BU_:  Airbag BAP_Tester ICAS1_Gateway ICAS1_KommunikationsServer LE1 LE2 Motor_BEV Schaltbetaetigung

BO_ 949 Klima_11: 8 ICAS1_Gateway
 SG_ KL_Drehz_Anh  : 0|1@1+ (1.000000,0.000000) [0.000000|1.000000] "" Vector__XXX
 SG_ KL_Vorwarn_Komp_ein  : 1|1@1+ (1.000000,0.000000) [0.000000|1.000000] "" Vector__XXX
 SG_ KL_AC_Schalter  : 2|1@1+ (1.000000,0.000000) [0.000000|1.000000] "" Vector__XXX
 SG_ KL_Komp_Moment_alt  : 3|1@1+ (1.000000,0.000000) [0.000000|1.000000] "" Vector__XXX
 SG_ KL_Vorwarn_Zuheizer_ein  : 6|1@1+ (1.000000,0.000000) [0.000000|1.000000] "" Vector__XXX
 SG_ KL_Zustand  : 7|1@1+ (1.000000,0.000000) [0.000000|1.000000] "" Vector__XXX
 SG_ KL_Kompressorkupplung_linear  : 8|8@1+ (20.000000,0.000000) [0.000000|4000.000000] "Unit_MilliAmper" Vector__XXX
 SG_ KL_Charisma_FahrPr  : 16|4@1+ (1.000000,0.000000) [0.000000|15.000000] "" Vector__XXX
 SG_ KL_Charisma_Status  : 20|2@1+ (1.000000,0.000000) [0.000000|3.000000] "" Vector__XXX
 SG_ KL_nachtr_Stopp_Anf  : 22|1@1+ (1.000000,0.000000) [0.000000|1.000000] "" Vector__XXX
 SG_ KL_T_Charge  : 23|1@1+ (1.000000,0.000000) [0.000000|1.000000] "" Vector__XXX
 SG_ KL_Last_Kompr  : 24|8@1+ (0.250000,0.000000) [0.000000|63.500000] "Unit_NewtoMeter" Vector__XXX
 SG_ KL_Spannungs_Anf  : 32|2@1+ (1.000000,0.000000) [0.000000|3.000000] "" Vector__XXX
 SG_ KL_Thermomanagement  : 34|2@1+ (1.000000,0.000000) [0.000000|3.000000] "" Motor_BEV
 SG_ KL_StartStopp_Info  : 36|2@1+ (1.000000,0.000000) [0.000000|3.000000] "" Vector__XXX
 SG_ KL_Freilauf_Info  : 38|2@1+ (1.000000,0.000000) [0.000000|3.000000] "" Vector__XXX
 SG_ KL_Anf_KL  : 40|8@1+ (0.400000,0.000000) [0.000000|101.600000] "Unit_PerCent" Motor_BEV
 SG_ KL_el_Zuheizer_Stufe  : 48|3@1+ (1.000000,0.000000) [0.000000|7.000000] "" Vector__XXX
 SG_ KL_Ausstattung_Klima  : 51|3@1+ (1.000000,0.000000) [0.000000|7.000000] "" Vector__XXX
 SG_ KL_Variante_Standheizung  : 54|2@1+ (1.000000,0.000000) [0.000000|3.000000] "" Vector__XXX
 SG_ KL_Anf_KV  : 57|7@1+ (1.000000,0.000000) [0.000000|100.000000] "Unit_PerCent" Motor_BEV

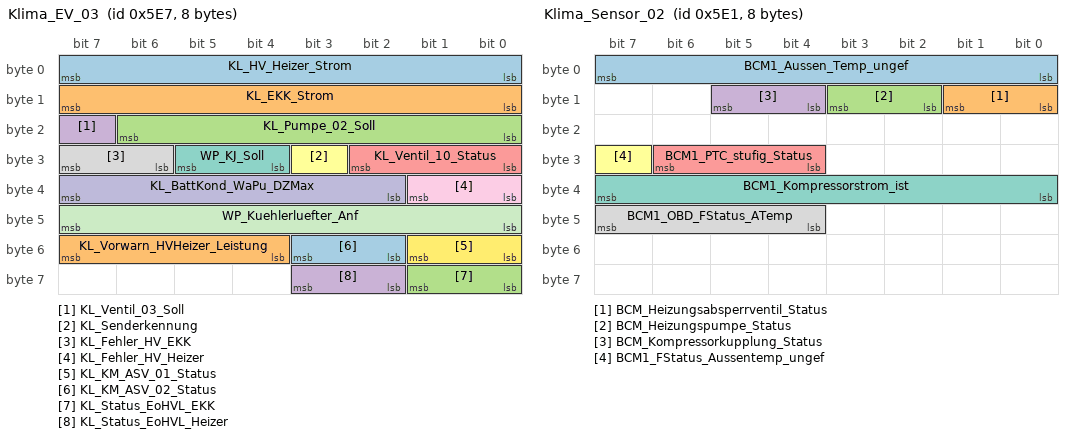
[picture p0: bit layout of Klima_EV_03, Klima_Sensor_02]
BO_ 1511 Klima_EV_03: 8 ICAS1_Gateway
 SG_ KL_HV_Heizer_Strom  : 0|8@1+ (0.250000,0.000000) [0.000000|63.500000] "Unit_Amper" Motor_BEV
 SG_ KL_EKK_Strom  : 8|8@1+ (0.250000,0.000000) [0.000000|63.500000] "Unit_Amper" Motor_BEV
 SG_ KL_Pumpe_02_Soll  : 16|7@1+ (1.000000,0.000000) [0.000000|100.000000] "Unit_PerCent" Motor_BEV
 SG_ KL_Ventil_03_Soll  : 23|1@1+ (1.000000,0.000000) [0.000000|1.000000] "" Vector__XXX
 SG_ KL_Ventil_10_Status  : 24|3@1+ (1.000000,0.000000) [0.000000|7.000000] "" Vector__XXX
 SG_ KL_Senderkennung  : 27|1@1+ (1.000000,0.000000) [0.000000|1.000000] "" Vector__XXX
 SG_ WP_KJ_Soll  : 28|2@1+ (1.000000,0.000000) [0.000000|3.000000] "" Vector__XXX
 SG_ KL_Fehler_HV_EKK  : 30|2@1+ (1.000000,0.000000) [0.000000|3.000000] "" Vector__XXX
 SG_ KL_Fehler_HV_Heizer  : 32|2@1+ (1.000000,0.000000) [0.000000|3.000000] "" Vector__XXX
 SG_ KL_BattKond_WaPu_DZMax  : 34|6@1+ (2.000000,0.000000) [0.000000|100.000000] "Unit_PerCent" Vector__XXX
 SG_ WP_Kuehlerluefter_Anf  : 40|8@1+ (0.400000,0.000000) [0.000000|101.600000] "Unit_PerCent" Vector__XXX
 SG_ KL_KM_ASV_01_Status  : 48|2@1+ (1.000000,0.000000) [0.000000|3.000000] "" Vector__XXX
 SG_ KL_KM_ASV_02_Status  : 50|2@1+ (1.000000,0.000000) [0.000000|3.000000] "" Vector__XXX
 SG_ KL_Vorwarn_HVHeizer_Leistung  : 52|4@1+ (1.000000,0.000000) [0.000000|15.000000] "" Vector__XXX
 SG_ KL_Status_EoHVL_EKK  : 56|2@1+ (1.000000,0.000000) [0.000000|3.000000] "" Motor_BEV
 SG_ KL_Status_EoHVL_Heizer  : 58|2@1+ (1.000000,0.000000) [0.000000|3.000000] "" Motor_BEV

BO_ 1505 Klima_Sensor_02: 8 ICAS1_Gateway
 SG_ BCM1_Aussen_Temp_ungef  : 0|8@1+ (0.500000,-50.000000) [-50.000000|76.000000] "Unit_DegreCelsi" LE1 LE2 Motor_BEV
 SG_ BCM_Heizungsabsperrventil_Status  : 8|2@1+ (1.000000,0.000000) [0.000000|3.000000] "" Vector__XXX
 SG_ BCM_Heizungspumpe_Status  : 10|2@1+ (1.000000,0.000000) [0.000000|3.000000] "" Vector__XXX
 SG_ BCM_Kompressorkupplung_Status  : 12|2@1+ (1.000000,0.000000) [0.000000|3.000000] "" Vector__XXX
 SG_ BCM1_PTC_stufig_Status  : 28|3@1+ (1.000000,0.000000) [0.000000|7.000000] "" Vector__XXX
 SG_ BCM1_FStatus_Aussentemp_ungef  : 31|1@1+ (1.000000,0.000000) [0.000000|1.000000] "" Vector__XXX
 SG_ BCM1_Kompressorstrom_ist  : 32|8@1+ (4.000000,0.000000) [0.000000|1000.000000] "Unit_MilliAmper" Vector__XXX
 SG_ BCM1_OBD_FStatus_ATemp  : 44|4@1+ (1.000000,0.000000) [0.000000|15.000000] "" Vector__XXX

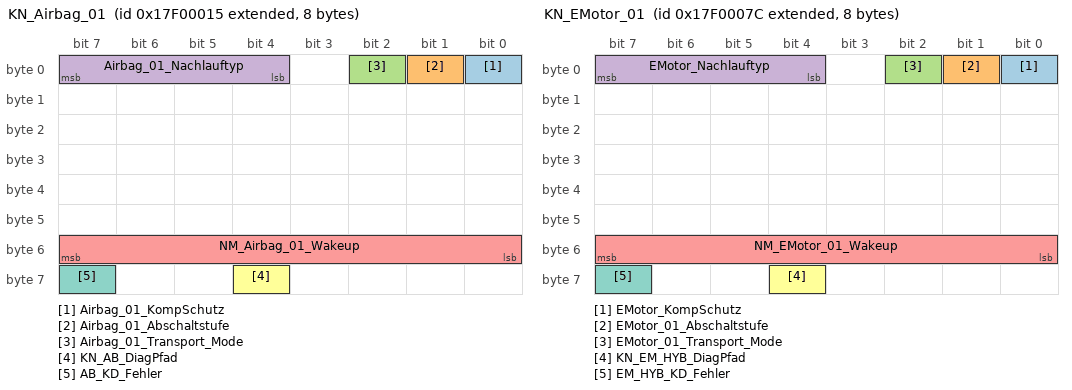
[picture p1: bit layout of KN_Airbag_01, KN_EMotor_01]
BO_ 2549088277 KN_Airbag_01: 8 Airbag
 SG_ Airbag_01_KompSchutz  : 0|1@1+ (1.000000,0.000000) [0.000000|1.000000] "" Vector__XXX
 SG_ Airbag_01_Abschaltstufe  : 1|1@1+ (1.000000,0.000000) [0.000000|1.000000] "" Vector__XXX
 SG_ Airbag_01_Transport_Mode  : 2|1@1+ (1.000000,0.000000) [0.000000|1.000000] "" Vector__XXX
 SG_ Airbag_01_Nachlauftyp  : 4|4@1+ (1.000000,0.000000) [0.000000|15.000000] "" ICAS1_Gateway
 SG_ NM_Airbag_01_Wakeup  : 48|8@1+ (1.000000,0.000000) [0.000000|255.000000] "" Vector__XXX
 SG_ KN_AB_DiagPfad  : 60|1@1+ (1.000000,0.000000) [0.000000|1.000000] "" ICAS1_Gateway
 SG_ AB_KD_Fehler  : 63|1@1+ (1.000000,0.000000) [0.000000|1.000000] "" ICAS1_Gateway

BO_ 2549088380 KN_EMotor_01: 8 LE1
 SG_ EMotor_KompSchutz  : 0|1@1+ (1.000000,0.000000) [0.000000|1.000000] "" Vector__XXX
 SG_ EMotor_01_Abschaltstufe  : 1|1@1+ (1.000000,0.000000) [0.000000|1.000000] "" Vector__XXX
 SG_ EMotor_01_Transport_Mode  : 2|1@1+ (1.000000,0.000000) [0.000000|1.000000] "" Vector__XXX
 SG_ EMotor_Nachlauftyp  : 4|4@1+ (1.000000,0.000000) [0.000000|15.000000] "" ICAS1_Gateway
 SG_ NM_EMotor_01_Wakeup  : 48|8@1+ (1.000000,0.000000) [0.000000|255.000000] "" Vector__XXX
 SG_ KN_EM_HYB_DiagPfad  : 60|1@1+ (1.000000,0.000000) [0.000000|1.000000] "" ICAS1_Gateway
 SG_ EM_HYB_KD_Fehler  : 63|1@1+ (1.000000,0.000000) [0.000000|1.000000] "" ICAS1_Gateway

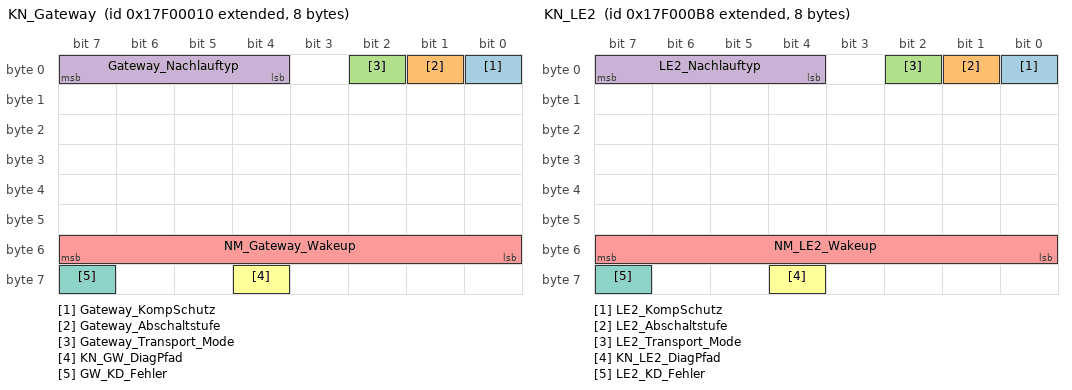
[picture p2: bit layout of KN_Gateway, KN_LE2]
BO_ 2549088272 KN_Gateway: 8 ICAS1_Gateway
 SG_ Gateway_KompSchutz  : 0|1@1+ (1.000000,0.000000) [0.000000|1.000000] "" Vector__XXX
 SG_ Gateway_Abschaltstufe  : 1|1@1+ (1.000000,0.000000) [0.000000|1.000000] "" Vector__XXX
 SG_ Gateway_Transport_Mode  : 2|1@1+ (1.000000,0.000000) [0.000000|1.000000] "" Vector__XXX
 SG_ Gateway_Nachlauftyp  : 4|4@1+ (1.000000,0.000000) [0.000000|15.000000] "" Vector__XXX
 SG_ NM_Gateway_Wakeup  : 48|8@1+ (1.000000,0.000000) [0.000000|255.000000] "" Vector__XXX
 SG_ KN_GW_DiagPfad  : 60|1@1+ (1.000000,0.000000) [0.000000|1.000000] "" Vector__XXX
 SG_ GW_KD_Fehler  : 63|1@1+ (1.000000,0.000000) [0.000000|1.000000] "" Vector__XXX

BO_ 2549088440 KN_LE2: 8 LE2
 SG_ LE2_KompSchutz  : 0|1@1+ (1.000000,0.000000) [0.000000|1.000000] "" Vector__XXX
 SG_ LE2_Abschaltstufe  : 1|1@1+ (1.000000,0.000000) [0.000000|1.000000] "" Vector__XXX
 SG_ LE2_Transport_Mode  : 2|1@1+ (1.000000,0.000000) [0.000000|1.000000] "" Vector__XXX
 SG_ LE2_Nachlauftyp  : 4|4@1+ (1.000000,0.000000) [0.000000|15.000000] "" ICAS1_Gateway
 SG_ NM_LE2_Wakeup  : 48|8@1+ (1.000000,0.000000) [0.000000|255.000000] "" Vector__XXX
 SG_ KN_LE2_DiagPfad  : 60|1@1+ (1.000000,0.000000) [0.000000|1.000000] "" ICAS1_Gateway
 SG_ LE2_KD_Fehler  : 63|1@1+ (1.000000,0.000000) [0.000000|1.000000] "" ICAS1_Gateway

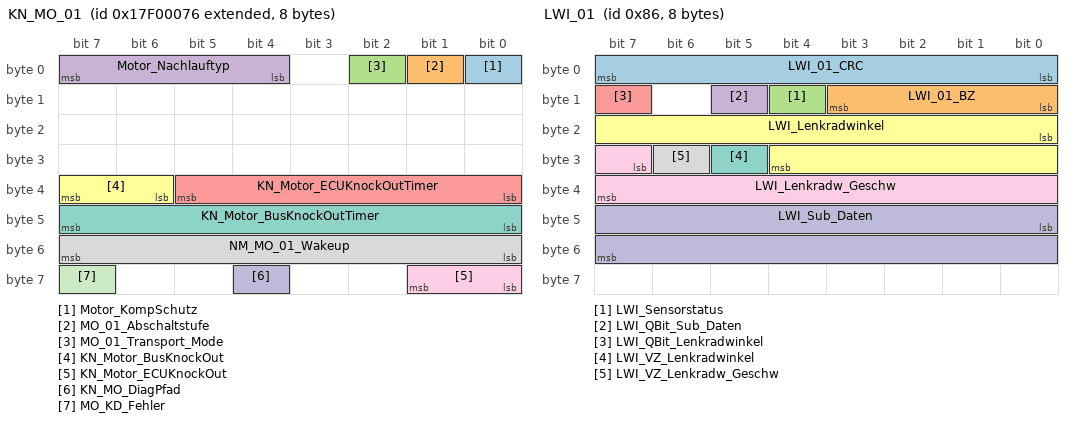
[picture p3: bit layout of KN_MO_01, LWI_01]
BO_ 2549088374 KN_MO_01: 8 Motor_BEV
 SG_ Motor_KompSchutz  : 0|1@1+ (1.000000,0.000000) [0.000000|1.000000] "" Vector__XXX
 SG_ MO_01_Abschaltstufe  : 1|1@1+ (1.000000,0.000000) [0.000000|1.000000] "" Vector__XXX
 SG_ MO_01_Transport_Mode  : 2|1@1+ (1.000000,0.000000) [0.000000|1.000000] "" Vector__XXX
 SG_ Motor_Nachlauftyp  : 4|4@1+ (1.000000,0.000000) [0.000000|15.000000] "" ICAS1_Gateway
 SG_ KN_Motor_ECUKnockOutTimer  : 32|6@1+ (1.000000,0.000000) [0.000000|62.000000] "Unit_Minut" Vector__XXX
 SG_ KN_Motor_BusKnockOut  : 38|2@1+ (1.000000,0.000000) [0.000000|3.000000] "" Vector__XXX
 SG_ KN_Motor_BusKnockOutTimer  : 40|8@1+ (1.000000,0.000000) [0.000000|254.000000] "" Vector__XXX
 SG_ NM_MO_01_Wakeup  : 48|8@1+ (1.000000,0.000000) [0.000000|255.000000] "" Vector__XXX
 SG_ KN_Motor_ECUKnockOut  : 56|2@1+ (1.000000,0.000000) [0.000000|3.000000] "" Vector__XXX
 SG_ KN_MO_DiagPfad  : 60|1@1+ (1.000000,0.000000) [0.000000|1.000000] "" ICAS1_Gateway
 SG_ MO_KD_Fehler  : 63|1@1+ (1.000000,0.000000) [0.000000|1.000000] "" ICAS1_Gateway

BO_ 2621440277 KS_Airbag_01_Req_FD: 16 ICAS1_Gateway
 SG_ KS_Airbag_01_Req_FD_Data  : 0|128@1+ (1.000000,0.000000) [0.000000|340282366920938463463374607431768211456.000000] "" Airbag

BO_ 2621571349 KS_Airbag_01_Resp_FD: 16 Airbag
 SG_ KS_Airbag_01_Resp_FD_Data  : 0|128@1+ (1.000000,0.000000) [0.000000|340282366920938463463374607431768211456.000000] "" ICAS1_Gateway

BO_ 982 Licht_hinten_01: 8 ICAS1_Gateway
 SG_ Licht_hinten_01_BZ  : 0|4@1+ (1.000000,0.000000) [0.000000|15.000000] "" Vector__XXX
 SG_ LH_Aussenlicht_def  : 7|1@1+ (1.000000,0.000000) [0.000000|1.000000] "" Vector__XXX
 SG_ LH_Standlicht_H_aktiv  : 8|1@1+ (1.000000,0.000000) [0.000000|1.000000] "" Vector__XXX
 SG_ LH_Parklicht_HL_aktiv  : 9|1@1+ (1.000000,0.000000) [0.000000|1.000000] "" Vector__XXX
 SG_ LH_Parklicht_HR_aktiv  : 10|1@1+ (1.000000,0.000000) [0.000000|1.000000] "" Vector__XXX
 SG_ LH_Bremslicht_H_aktiv  : 11|1@1+ (1.000000,0.000000) [0.000000|1.000000] "" Vector__XXX
 SG_ LH_Nebelschluss_aktiv  : 12|1@1+ (1.000000,0.000000) [0.000000|1.000000] "" Vector__XXX
 SG_ LH_Rueckfahrlicht_aktiv  : 13|1@1+ (1.000000,0.000000) [0.000000|1.000000] "" Vector__XXX
 SG_ LH_Blinker_HL_akt  : 14|1@1+ (1.000000,0.000000) [0.000000|1.000000] "" Vector__XXX
 SG_ LH_Blinker_HR_akt  : 15|1@1+ (1.000000,0.000000) [0.000000|1.000000] "" Vector__XXX
 SG_ LH_Blinker_li_def  : 16|1@1+ (1.000000,0.000000) [0.000000|1.000000] "" Vector__XXX
 SG_ LH_Bremsl_li_def  : 17|1@1+ (1.000000,0.000000) [0.000000|1.000000] "" Vector__XXX
 SG_ LH_Schlusslicht_li_def  : 18|1@1+ (1.000000,0.000000) [0.000000|1.000000] "" Vector__XXX
 SG_ LH_Rueckf_li_def  : 19|1@1+ (1.000000,0.000000) [0.000000|1.000000] "" Vector__XXX
 SG_ LH_Nebel_li_def  : 20|1@1+ (1.000000,0.000000) [0.000000|1.000000] "" Vector__XXX
 SG_ LH_Schluss_Brems_Nebel_li_def  : 21|1@1+ (1.000000,0.000000) [0.000000|1.000000] "" Vector__XXX
 SG_ LH_Schluss_Brems_Nebel_re_def  : 22|1@1+ (1.000000,0.000000) [0.000000|1.000000] "" Vector__XXX
 SG_ LH_Zusatzschlussl_def  : 23|1@1+ (1.000000,0.000000) [0.000000|1.000000] "" Vector__XXX
 SG_ LH_Schluss_Brems_li_def  : 24|1@1+ (1.000000,0.000000) [0.000000|1.000000] "" Vector__XXX
 SG_ LH_Schluss_Nebel_li_def  : 25|1@1+ (1.000000,0.000000) [0.000000|1.000000] "" Vector__XXX
 SG_ LH_SL_BRL_BLK_li_def  : 26|1@1+ (1.000000,0.000000) [0.000000|1.000000] "" Vector__XXX
 SG_ LH_Brems_Blk_li_def  : 27|1@1+ (1.000000,0.000000) [0.000000|1.000000] "" Vector__XXX
 SG_ LH_Diag_Status_re_def  : 28|1@1+ (1.000000,0.000000) [0.000000|1.000000] "" Vector__XXX
 SG_ LH_Diag_Status_li_def  : 29|1@1+ (1.000000,0.000000) [0.000000|1.000000] "" Vector__XXX
 SG_ LH_Diag_LED_li_def  : 30|1@1+ (1.000000,0.000000) [0.000000|1.000000] "" Vector__XXX
 SG_ LH_Diag_LED_re_def  : 31|1@1+ (1.000000,0.000000) [0.000000|1.000000] "" Vector__XXX
 SG_ LH_Blinker_re_def  : 32|1@1+ (1.000000,0.000000) [0.000000|1.000000] "" Vector__XXX
 SG_ LH_Bremsl_re_def  : 33|1@1+ (1.000000,0.000000) [0.000000|1.000000] "" Vector__XXX
 SG_ LH_Schlusslicht_re_def  : 34|1@1+ (1.000000,0.000000) [0.000000|1.000000] "" Vector__XXX
 SG_ LH_Rueckf_re_def  : 35|1@1+ (1.000000,0.000000) [0.000000|1.000000] "" Vector__XXX
 SG_ LH_Nebel_re_def  : 36|1@1+ (1.000000,0.000000) [0.000000|1.000000] "" Vector__XXX
 SG_ LH_Schluss_Brems_mi_def  : 37|1@1+ (1.000000,0.000000) [0.000000|1.000000] "" Vector__XXX
 SG_ LH_Schluss_Brems_re_def  : 40|1@1+ (1.000000,0.000000) [0.000000|1.000000] "" Vector__XXX
 SG_ LH_Schluss_Nebel_re_def  : 41|1@1+ (1.000000,0.000000) [0.000000|1.000000] "" Vector__XXX
 SG_ LH_SL_BRL_BLK_re_def  : 42|1@1+ (1.000000,0.000000) [0.000000|1.000000] "" Vector__XXX
 SG_ LH_Brems_Blk_re_def  : 43|1@1+ (1.000000,0.000000) [0.000000|1.000000] "" Vector__XXX
 SG_ LH_Kennzl_def  : 48|1@1+ (1.000000,0.000000) [0.000000|1.000000] "" Vector__XXX
 SG_ LH_3_Bremsl_def  : 49|1@1+ (1.000000,0.000000) [0.000000|1.000000] "" Motor_BEV
 SG_ LH_Nebel_mi_def  : 50|1@1+ (1.000000,0.000000) [0.000000|1.000000] "" Vector__XXX
 SG_ LH_Rueckf_mi_def  : 51|1@1+ (1.000000,0.000000) [0.000000|1.000000] "" Vector__XXX
 SG_ LH_Schlusslicht_mi_def  : 52|1@1+ (1.000000,0.000000) [0.000000|1.000000] "" Vector__XXX
 SG_ LH_Bremsl_li_ges_def  : 54|1@1+ (1.000000,0.000000) [0.000000|1.000000] "" Motor_BEV
 SG_ LH_Bremsl_re_ges_def  : 55|1@1+ (1.000000,0.000000) [0.000000|1.000000] "" Motor_BEV
 SG_ LH_Bremsl_mi_def  : 61|1@1+ (1.000000,0.000000) [0.000000|1.000000] "" Vector__XXX
 SG_ BRL_als_SHL  : 62|1@1+ (1.000000,0.000000) [0.000000|1.000000] "" Vector__XXX

BO_ 134 LWI_01: 8 ICAS1_Gateway
 SG_ LWI_01_CRC  : 0|8@1+ (1.000000,0.000000) [0.000000|255.000000] "" Airbag Motor_BEV
 SG_ LWI_01_BZ  : 8|4@1+ (1.000000,0.000000) [0.000000|15.000000] "" Airbag Motor_BEV
 SG_ LWI_Sensorstatus  : 12|1@1+ (1.000000,0.000000) [0.000000|1.000000] "" Airbag Motor_BEV
 SG_ LWI_QBit_Sub_Daten  : 13|1@1+ (1.000000,0.000000) [0.000000|1.000000] "" Vector__XXX
 SG_ LWI_QBit_Lenkradwinkel  : 15|1@1+ (1.000000,0.000000) [0.000000|1.000000] "" Airbag Motor_BEV
 SG_ LWI_Lenkradwinkel  : 16|13@1+ (0.100000,0.000000) [0.000000|800.000000] "Unit_DegreOfArc" Airbag Motor_BEV
 SG_ LWI_VZ_Lenkradwinkel  : 29|1@1+ (1.000000,0.000000) [0.000000|1.000000] "" Airbag Motor_BEV
 SG_ LWI_VZ_Lenkradw_Geschw  : 30|1@1+ (1.000000,0.000000) [0.000000|1.000000] "" Vector__XXX
 SG_ LWI_Lenkradw_Geschw  : 31|9@1+ (5.000000,0.000000) [0.000000|2500.000000] "Unit_DegreOfArcPerSecon" Airbag
 SG_ LWI_Sub_Daten  : 40|16@1+ (1.000000,0.000000) [0.000000|65535.000000] "" Vector__XXX

BO_ 817 MFL_01: 8 ICAS1_Gateway
 SG_ MFL_Zaehler  : 0|4@1+ (1.000000,0.000000) [0.000000|15.000000] "" Vector__XXX
 SG_ MFL_Toggle  : 4|1@1+ (1.000000,0.000000) [0.000000|1.000000] "" Vector__XXX
 SG_ MFL_Lokalaktiv  : 5|1@1+ (1.000000,0.000000) [0.000000|1.000000] "" Vector__XXX
 SG_ MFL_M_Taste  : 6|1@1+ (1.000000,0.000000) [0.000000|1.000000] "" Vector__XXX
 SG_ MFL_Paddle_Verbau  : 7|1@1+ (1.000000,0.000000) [0.000000|1.000000] "" Vector__XXX
 SG_ MFL_Tastencode_1  : 8|8@1+ (1.000000,0.000000) [0.000000|255.000000] "" Vector__XXX
 SG_ MFL_Tastencode_2  : 16|8@1+ (1.000000,0.000000) [0.000000|255.000000] "" Vector__XXX
 SG_ MFL_Eventcode_1  : 24|4@1+ (1.000000,0.000000) [0.000000|15.000000] "" Vector__XXX
 SG_ MFL_Eventcode_2  : 28|4@1+ (1.000000,0.000000) [0.000000|15.000000] "" Vector__XXX
 SG_ MFL_Marke  : 32|4@1+ (1.000000,0.000000) [0.000000|15.000000] "" Vector__XXX
 SG_ MFL_Variante  : 36|4@1+ (1.000000,0.000000) [0.000000|15.000000] "" Vector__XXX
 SG_ MFL_Dummy_0_Signal_1  : 40|8@1+ (1.000000,0.000000) [0.000000|255.000000] "" Vector__XXX
 SG_ MFL_Tip_Down  : 48|1@1+ (1.000000,0.000000) [0.000000|1.000000] "" Motor_BEV
 SG_ MFL_Tip_Up  : 49|1@1+ (1.000000,0.000000) [0.000000|1.000000] "" Motor_BEV
 SG_ MFL_SatModul_links_Err  : 50|1@1+ (1.000000,0.000000) [0.000000|1.000000] "" Vector__XXX
 SG_ MFL_SatModul_rechts_Err  : 51|1@1+ (1.000000,0.000000) [0.000000|1.000000] "" Vector__XXX
 SG_ MFL_Dummy_0_Signal_2  : 52|1@1+ (1.000000,0.000000) [0.000000|1.000000] "" Vector__XXX
 SG_ MFL_Dummy_0_Signal_3  : 53|1@1+ (1.000000,0.000000) [0.000000|1.000000] "" Vector__XXX
 SG_ MFL_LR_HZG_Status  : 54|1@1+ (1.000000,0.000000) [0.000000|1.000000] "" Vector__XXX
 SG_ MFL_LR_HZG_Err  : 55|1@1+ (1.000000,0.000000) [0.000000|1.000000] "" Vector__XXX
 SG_ MFL_Signalhorn  : 56|1@1+ (1.000000,0.000000) [0.000000|1.000000] "" Vector__XXX
 SG_ MFL_Signalhorn_Err  : 57|1@1+ (1.000000,0.000000) [0.000000|1.000000] "" Vector__XXX
 SG_ MFL_Tip_links_Err  : 58|1@1+ (1.000000,0.000000) [0.000000|1.000000] "" Vector__XXX
 SG_ MFL_Tip_rechts_Err  : 59|1@1+ (1.000000,0.000000) [0.000000|1.000000] "" Vector__XXX
 SG_ MFL_Taste_links_Err  : 60|1@1+ (1.000000,0.000000) [0.000000|1.000000] "" Vector__XXX
 SG_ MFL_Taste_rechts_Err  : 61|1@1+ (1.000000,0.000000) [0.000000|1.000000] "" Vector__XXX
 SG_ MFL_ECU_Err  : 62|1@1+ (1.000000,0.000000) [0.000000|1.000000] "" Vector__XXX
 SG_ MFL_Response_Err  : 63|1@1+ (1.000000,0.000000) [0.000000|1.000000] "" Vector__XXX

BO_ 15 MO_SOPC: 1 Motor_BEV
 SG_ MO_SOPC  : 0|1@1+ (1.000000,0.000000) [0.000000|1.000000] "" Vector__XXX

BO_ 1600 Motor_07: 8 Motor_BEV
 SG_ MO_QBit_Ansaugluft_Temp  : 0|1@1+ (1.000000,0.000000) [0.000000|1.000000] "" Vector__XXX
 SG_ MO_QBit_Oel_Temp  : 1|1@1+ (1.000000,0.000000) [0.000000|1.000000] "" Vector__XXX
 SG_ MO_QBit_Kuehlmittel_Temp  : 2|1@1+ (1.000000,0.000000) [0.000000|1.000000] "" Vector__XXX
 SG_ MO_KL15_Abschaltempfehlung  : 3|1@1+ (1.000000,0.000000) [0.000000|1.000000] "" Vector__XXX
 SG_ MO_HYB_Fehler_HV_Netz  : 4|1@1+ (1.000000,0.000000) [0.000000|1.000000] "" Vector__XXX
 SG_ MO_aktives_Getriebeheizen  : 5|1@1+ (1.000000,0.000000) [0.000000|1.000000] "" Vector__XXX
 SG_ MO_Absperrventil_oeffnen  : 6|2@1+ (1.000000,0.000000) [0.000000|3.000000] "" Vector__XXX
 SG_ MO_Ansaugluft_Temp  : 8|8@1+ (0.750000,-48.000000) [-48.000000|141.750000] "Unit_DegreCelsi" Vector__XXX
 SG_ MO_Oel_Temp  : 16|8@1+ (1.000000,-60.000000) [-60.000000|192.000000] "Unit_DegreCelsi" Vector__XXX
 SG_ MO_Kuehlmittel_Temp  : 24|8@1+ (0.750000,-48.000000) [-48.000000|141.750000] "Unit_DegreCelsi" Vector__XXX
 SG_ MO_Hoeheninfo  : 32|8@1+ (0.007810,0.000000) [0.000000|1.983740] "" Vector__XXX
 SG_ MO_Kennfeldk  : 40|1@1+ (1.000000,0.000000) [0.000000|1.000000] "" Vector__XXX
 SG_ MO_Versionsinfo_02  : 41|5@1+ (1.000000,0.000000) [0.000000|31.000000] "" Vector__XXX
 SG_ MO_QBit_Hoeheninfo  : 46|1@1+ (1.000000,0.000000) [0.000000|1.000000] "" Vector__XXX
 SG_ MO_Getriebe_kuehlen  : 47|1@1+ (1.000000,0.000000) [0.000000|1.000000] "" Vector__XXX
 SG_ MO_Mom_Traegheit_02  : 48|5@1+ (0.010000,0.000000) [0.000000|0.310000] "Unit_KiloGramMeterSquar" Vector__XXX
 SG_ MO_Heizungspumpenansteuerung  : 53|4@1+ (10.000000,0.000000) [0.000000|100.000000] "Unit_PerCent" Vector__XXX
 SG_ MO_SpannungsAnf  : 57|1@1+ (1.000000,0.000000) [0.000000|1.000000] "" Vector__XXX
 SG_ MO_Nachlaufzeit_Heizungspumpe  : 58|6@1+ (15.000000,0.000000) [0.000000|945.000000] "Unit_Secon" Vector__XXX

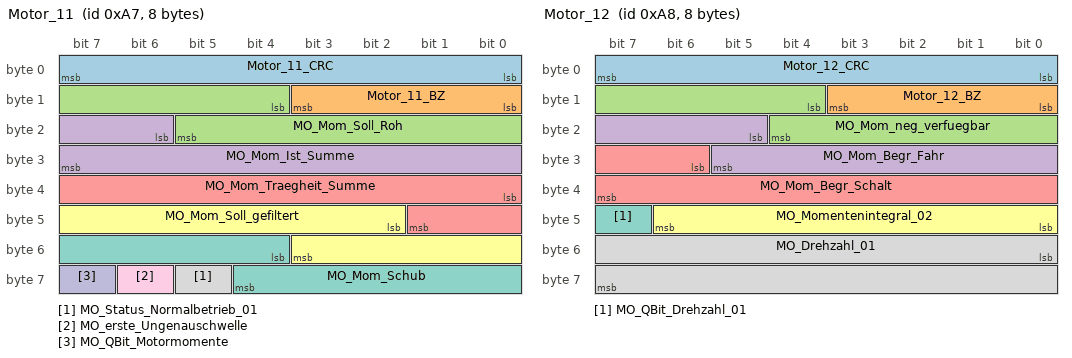
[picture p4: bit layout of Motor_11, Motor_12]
BO_ 167 Motor_11: 8 Motor_BEV
 SG_ Motor_11_CRC  : 0|8@1+ (1.000000,0.000000) [0.000000|255.000000] "" ICAS1_Gateway
 SG_ Motor_11_BZ  : 8|4@1+ (1.000000,0.000000) [0.000000|15.000000] "" ICAS1_Gateway
 SG_ MO_Mom_Soll_Roh  : 12|10@1+ (1.000000,-509.000000) [-509.000000|509.000000] "" ICAS1_Gateway
 SG_ MO_Mom_Ist_Summe  : 22|10@1+ (1.000000,-509.000000) [-509.000000|509.000000] "" ICAS1_Gateway
 SG_ MO_Mom_Traegheit_Summe  : 32|10@1+ (1.000000,-509.000000) [-509.000000|509.000000] "" ICAS1_Gateway
 SG_ MO_Mom_Soll_gefiltert  : 42|10@1+ (1.000000,-509.000000) [-509.000000|509.000000] "" ICAS1_Gateway
 SG_ MO_Mom_Schub  : 52|9@1+ (1.000000,-509.000000) [-509.000000|0.000000] "" ICAS1_Gateway
 SG_ MO_Status_Normalbetrieb_01  : 61|1@1+ (1.000000,0.000000) [0.000000|1.000000] "" ICAS1_Gateway
 SG_ MO_erste_Ungenauschwelle  : 62|1@1+ (1.000000,0.000000) [0.000000|1.000000] "" ICAS1_Gateway
 SG_ MO_QBit_Motormomente  : 63|1@1+ (1.000000,0.000000) [0.000000|1.000000] "" ICAS1_Gateway

BO_ 168 Motor_12: 8 Motor_BEV
 SG_ Motor_12_CRC  : 0|8@1+ (1.000000,0.000000) [0.000000|255.000000] "" ICAS1_Gateway
 SG_ Motor_12_BZ  : 8|4@1+ (1.000000,0.000000) [0.000000|15.000000] "" ICAS1_Gateway
 SG_ MO_Mom_neg_verfuegbar  : 12|9@1+ (1.000000,-509.000000) [-509.000000|0.000000] "" ICAS1_Gateway
 SG_ MO_Mom_Begr_Fahr  : 21|9@1+ (1.000000,0.000000) [0.000000|509.000000] "" ICAS1_Gateway
 SG_ MO_Mom_Begr_Schalt  : 30|10@1+ (1.000000,-509.000000) [-509.000000|509.000000] "" ICAS1_Gateway
 SG_ MO_Momentenintegral_02  : 40|7@1+ (1.000000,0.000000) [0.000000|100.000000] "Unit_PerCent" ICAS1_Gateway
 SG_ MO_QBit_Drehzahl_01  : 47|1@1+ (1.000000,0.000000) [0.000000|1.000000] "" Airbag ICAS1_Gateway LE2
 SG_ MO_Drehzahl_01  : 48|16@1+ (0.250000,0.000000) [0.000000|16383.000000] "Unit_MinutInver" ICAS1_Gateway

BO_ 958 Motor_14: 8 Motor_BEV
 SG_ Motor_14_CRC  : 0|8@1+ (1.000000,0.000000) [0.000000|255.000000] "" ICAS1_Gateway
 SG_ Motor_14_BZ  : 8|4@1+ (1.000000,0.000000) [0.000000|15.000000] "" ICAS1_Gateway
 SG_ MO_StartStopp_Status  : 12|2@1+ (1.000000,0.000000) [0.000000|3.000000] "" ICAS1_Gateway
 SG_ MO_StartStopp_Wiederstart  : 14|1@1+ (1.000000,0.000000) [0.000000|1.000000] "" ICAS1_Gateway
 SG_ MO_StartStopp_Motorstopp  : 15|1@1+ (1.000000,0.000000) [0.000000|1.000000] "" ICAS1_Gateway
 SG_ MO_Freig_Reku  : 16|2@1+ (1.000000,0.000000) [0.000000|3.000000] "" ICAS1_Gateway
 SG_ MO_Kl_75  : 18|1@1+ (1.000000,0.000000) [0.000000|1.000000] "" ICAS1_Gateway
 SG_ MO_Kl_50  : 19|1@1+ (1.000000,0.000000) [0.000000|1.000000] "" ICAS1_Gateway
 SG_ MO_Gangposition  : 20|4@1+ (1.000000,0.000000) [0.000000|15.000000] "" ICAS1_Gateway
 SG_ MO_StartStopp_Fahrerwunsch  : 24|2@1+ (1.000000,0.000000) [0.000000|3.000000] "" ICAS1_Gateway
 SG_ MO_HYB_Fahrbereitschaft  : 26|1@1+ (1.000000,0.000000) [0.000000|1.000000] "" ICAS1_Gateway
 SG_ MO_Ext_E_Fahrt_aktiv  : 27|1@1+ (1.000000,0.000000) [0.000000|1.000000] "" ICAS1_Gateway
 SG_ MO_Fahrer_bremst  : 28|1@1+ (1.000000,0.000000) [0.000000|1.000000] "" Airbag ICAS1_Gateway
 SG_ MO_QBit_Fahrer_bremst  : 29|1@1+ (1.000000,0.000000) [0.000000|1.000000] "" Airbag ICAS1_Gateway
 SG_ MO_BLS  : 30|1@1+ (1.000000,0.000000) [0.000000|1.000000] "" Airbag ICAS1_Gateway
 SG_ MO_Konsistenz_Bremsped  : 31|1@1+ (1.000000,0.000000) [0.000000|1.000000] "" ICAS1_Gateway
 SG_ MO_Timeout_ESP  : 32|1@1+ (1.000000,0.000000) [0.000000|1.000000] "" ICAS1_Gateway
 SG_ MO_Klima_Eingr  : 33|2@1+ (1.000000,0.000000) [0.000000|3.000000] "" ICAS1_Gateway
 SG_ MO_Aussp_Anlass  : 35|1@1+ (1.000000,0.000000) [0.000000|1.000000] "" ICAS1_Gateway
 SG_ MO_Freig_Anlass  : 36|1@1+ (1.000000,0.000000) [0.000000|1.000000] "" ICAS1_Gateway
 SG_ MO_Kuppl_schalter  : 37|1@1+ (1.000000,0.000000) [0.000000|1.000000] "" ICAS1_Gateway
 SG_ MO_Interlock  : 38|1@1+ (1.000000,0.000000) [0.000000|1.000000] "" ICAS1_Gateway
 SG_ MO_Motor_laeuft  : 39|1@1+ (1.000000,0.000000) [0.000000|1.000000] "" ICAS1_Gateway
 SG_ MO_Kickdown  : 40|1@1+ (1.000000,0.000000) [0.000000|1.000000] "" ICAS1_Gateway ICAS1_KommunikationsServer
 SG_ MO_QBit_KL_75  : 41|1@1+ (1.000000,0.000000) [0.000000|1.000000] "" ICAS1_Gateway
 SG_ MO_EKlKomLeiRed  : 42|2@1+ (1.000000,0.000000) [0.000000|3.000000] "" ICAS1_Gateway
 SG_ MO_Handshake_STH  : 44|1@1+ (1.000000,0.000000) [0.000000|1.000000] "" ICAS1_Gateway
 SG_ MO_BKV_Unterdruckwarnung  : 45|1@1+ (1.000000,0.000000) [0.000000|1.000000] "" ICAS1_Gateway
 SG_ MO_Freigabe_Segeln  : 46|1@1+ (1.000000,0.000000) [0.000000|1.000000] "" ICAS1_Gateway
 SG_ MO_PTC_Status  : 47|3@1+ (1.000000,0.000000) [0.000000|7.000000] "" ICAS1_Gateway
 SG_ MO_QBit_Gangposition  : 50|1@1+ (1.000000,0.000000) [0.000000|1.000000] "" ICAS1_Gateway
 SG_ MO_Signalquelle_Gangposition  : 51|1@1+ (1.000000,0.000000) [0.000000|1.000000] "" ICAS1_Gateway
 SG_ MO_Remotestart_Betrieb  : 52|1@1+ (1.000000,0.000000) [0.000000|1.000000] "" ICAS1_Gateway
 SG_ MO_Remotestart_moeglich  : 53|1@1+ (1.000000,0.000000) [0.000000|1.000000] "" ICAS1_Gateway
 SG_ MO_FMAus_aktiv  : 55|1@1+ (1.000000,0.000000) [0.000000|1.000000] "" ICAS1_Gateway
 SG_ MO_FMAus_Startvariante  : 56|2@1+ (1.000000,0.000000) [0.000000|3.000000] "" ICAS1_Gateway
 SG_ MO_BMS_NV_Anf_stuetzen  : 58|1@1+ (1.000000,0.000000) [0.000000|1.000000] "" ICAS1_Gateway
 SG_ MO_Zylinderabschaltung  : 59|2@1+ (1.000000,0.000000) [0.000000|3.000000] "" ICAS1_Gateway
 SG_ MO_HYB_VM_aktiv  : 61|1@1+ (1.000000,0.000000) [0.000000|1.000000] "" ICAS1_Gateway
 SG_ MO_StartVorauss_erfuellt  : 62|2@1+ (1.000000,0.000000) [0.000000|3.000000] "" ICAS1_Gateway

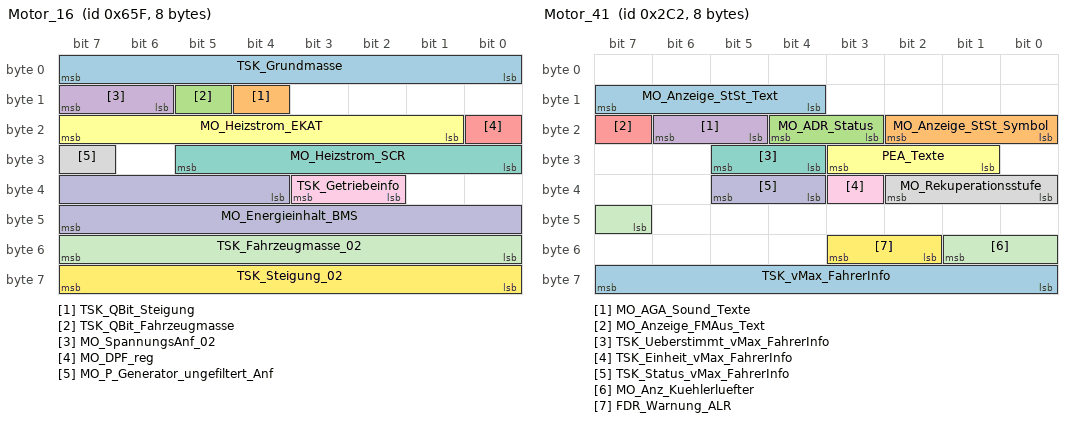
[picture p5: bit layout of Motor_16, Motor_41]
BO_ 1631 Motor_16: 8 Motor_BEV
 SG_ TSK_Grundmasse  : 0|8@1+ (32.000000,0.000000) [0.000000|8128.000000] "Unit_KiloGram" ICAS1_Gateway
 SG_ TSK_QBit_Steigung  : 12|1@1+ (1.000000,0.000000) [0.000000|1.000000] "" ICAS1_Gateway
 SG_ TSK_QBit_Fahrzeugmasse  : 13|1@1+ (1.000000,0.000000) [0.000000|1.000000] "" ICAS1_Gateway
 SG_ MO_SpannungsAnf_02  : 14|2@1+ (1.000000,0.000000) [0.000000|3.000000] "" ICAS1_Gateway
 SG_ MO_DPF_reg  : 16|1@1+ (1.000000,0.000000) [0.000000|1.000000] "" ICAS1_Gateway
 SG_ MO_Heizstrom_EKAT  : 17|7@1+ (1.000000,0.000000) [0.000000|126.000000] "Unit_Amper" ICAS1_Gateway
 SG_ MO_Heizstrom_SCR  : 24|6@1+ (1.000000,0.000000) [0.000000|62.000000] "Unit_Amper" ICAS1_Gateway
 SG_ MO_P_Generator_ungefiltert_Anf  : 31|1@1+ (1.000000,0.000000) [0.000000|1.000000] "" ICAS1_Gateway
 SG_ TSK_Getriebeinfo  : 34|2@1+ (1.000000,0.000000) [0.000000|3.000000] "" ICAS1_Gateway
 SG_ MO_Energieinhalt_BMS  : 36|12@1+ (25.000000,0.000000) [0.000000|102325.000000] "Unit_WattHour" ICAS1_Gateway
 SG_ TSK_Fahrzeugmasse_02  : 48|8@1+ (32.000000,0.000000) [0.000000|8128.000000] "Unit_KiloGram" ICAS1_Gateway
 SG_ TSK_Steigung_02  : 56|8@1+ (0.800000,-101.600000) [-100.800000|101.600000] "Unit_PerCent" ICAS1_Gateway

BO_ 1648 Motor_18: 8 Motor_BEV
 SG_ MO_max_Ladedruck  : 0|6@1+ (0.100000,0.000000) [0.000000|6.300000] "Unit_Bar" ICAS1_Gateway
 SG_ MO_ANC_Kennfeld_Anf  : 6|2@1+ (1.000000,0.000000) [0.000000|3.000000] "" ICAS1_Gateway
 SG_ MO_Bremslicht_Reku  : 8|1@1+ (1.000000,0.000000) [0.000000|1.000000] "" ICAS1_Gateway
 SG_ MO_StartStopp_PopUp  : 9|2@1+ (1.000000,0.000000) [0.000000|3.000000] "" ICAS1_Gateway
 SG_ MO1_Sperr_Info_WFS  : 11|1@1+ (1.000000,0.000000) [0.000000|1.000000] "" ICAS1_Gateway
 SG_ MO1_Freigabe_Info_WFS  : 12|1@1+ (1.000000,0.000000) [0.000000|1.000000] "" ICAS1_Gateway
 SG_ MO_EPCL  : 13|3@1+ (1.000000,0.000000) [0.000000|7.000000] "" ICAS1_Gateway ICAS1_KommunikationsServer
 SG_ MO_Zylabsch_Texte_02  : 16|4@1+ (1.000000,0.000000) [0.000000|15.000000] "" ICAS1_Gateway
 SG_ MO_Fahrzeugtyp  : 20|3@1+ (1.000000,0.000000) [0.000000|7.000000] "" ICAS1_Gateway ICAS1_KommunikationsServer
 SG_ MO_NMAX_Schaltanzeige  : 23|9@1+ (25.000000,0.000000) [0.000000|12775.000000] "Unit_MinutInver" ICAS1_Gateway
 SG_ MO_Abstellzeit  : 32|8@1+ (8.000000,0.000000) [0.000000|2024.000000] "Unit_Minut" ICAS1_Gateway
 SG_ MO_Abstellzeit_Status  : 40|2@1+ (1.000000,0.000000) [0.000000|3.000000] "" ICAS1_Gateway
 SG_ MO1_Freigabe_Verfallsinfo_WFS  : 42|1@1+ (1.000000,0.000000) [0.000000|1.000000] "" ICAS1_Gateway
 SG_ MO_Hybrid_StartStopp_LED  : 43|2@1+ (1.000000,0.000000) [0.000000|3.000000] "" ICAS1_Gateway
 SG_ MO_Fehler_Zylabsch  : 45|2@1+ (1.000000,0.000000) [0.000000|3.000000] "" ICAS1_Gateway
 SG_ MO_Anzahl_Abgesch_Zyl  : 47|3@1+ (1.000000,0.000000) [0.000000|7.000000] "" ICAS1_Gateway
 SG_ MO_Zylabsch_Texte  : 50|2@1+ (1.000000,0.000000) [0.000000|3.000000] "" ICAS1_Gateway
 SG_ MO_Ethanol_BS_Texte  : 52|3@1+ (1.000000,0.000000) [0.000000|7.000000] "" ICAS1_Gateway
 SG_ MO_Drehzahl_Warnung  : 55|1@1+ (1.000000,0.000000) [0.000000|1.000000] "" ICAS1_Gateway
 SG_ MO_obere_Drehzahlgrenze  : 56|8@1+ (50.000000,0.000000) [50.000000|12750.000000] "Unit_MinutInver" ICAS1_Gateway

BO_ 967 Motor_26: 8 Motor_BEV
 SG_ MO_Kuehlerluefter_MUX M : 0|1@1+ (1.000000,0.000000) [0.000000|1.000000] "siema ooo" ICAS1_Gateway
 SG_ MO_Kuehlerluefter_1 m0 : 1|7@1+ (1.000000,0.000000) [0.000000|100.000000] "Unit_PerCent" ICAS1_Gateway
 SG_ MO_Kuehlerluefter_2 m1 : 1|7@1+ (1.000000,0.000000) [0.000000|100.000000] "Unit_PerCent" ICAS1_Gateway
 SG_ MO_EFLEX_Lampe  : 8|2@1+ (1.000000,0.000000) [0.000000|3.000000] "" ICAS1_Gateway
 SG_ MO_KJS_nicht_bereit  : 10|1@1+ (1.000000,0.000000) [0.000000|1.000000] "" ICAS1_Gateway
 SG_ MO_ITM_Warnung_Pumpe  : 11|1@1+ (1.000000,0.000000) [0.000000|1.000000] "" ICAS1_Gateway
 SG_ WIV_Anzeige_aktiv  : 12|1@1+ (1.000000,0.000000) [0.000000|1.000000] "" ICAS1_Gateway
 SG_ WIV_Oelmin_Warn  : 13|1@1+ (1.000000,0.000000) [0.000000|1.000000] "" ICAS1_Gateway
 SG_ WIV_Sensorfehler  : 14|1@1+ (1.000000,0.000000) [0.000000|1.000000] "" ICAS1_Gateway
 SG_ WIV_Schieflage  : 15|1@1+ (1.000000,0.000000) [0.000000|1.000000] "" ICAS1_Gateway
 SG_ WIV_Oelstand  : 16|4@1+ (12.500000,0.000000) [0.000000|100.000000] "Unit_PerCent" ICAS1_Gateway
 SG_ MO_Zustand_HWP  : 20|2@1+ (1.000000,0.000000) [0.000000|3.000000] "" ICAS1_Gateway
 SG_ OLEV_Systemstoerung  : 22|1@1+ (1.000000,0.000000) [0.000000|1.000000] "" ICAS1_Gateway
 SG_ MO_Oelwarnung_max  : 23|1@1+ (1.000000,0.000000) [0.000000|1.000000] "" ICAS1_Gateway
 SG_ WIV_Oelsystem_aktiv  : 24|1@1+ (1.000000,0.000000) [0.000000|1.000000] "" ICAS1_Gateway
 SG_ WIV_nicht_betriebswarm  : 25|1@1+ (1.000000,0.000000) [0.000000|1.000000] "" ICAS1_Gateway
 SG_ WIV_Ueberfuell_Warn  : 26|1@1+ (1.000000,0.000000) [0.000000|1.000000] "" ICAS1_Gateway
 SG_ WIV_laufender_Motor  : 27|1@1+ (1.000000,0.000000) [0.000000|1.000000] "" ICAS1_Gateway
 SG_ MO_E_Warnungen  : 28|4@1+ (1.000000,0.000000) [0.000000|15.000000] "" ICAS1_Gateway
 SG_ MO_Text_Motorstart  : 32|4@1+ (1.000000,0.000000) [0.000000|15.000000] "" ICAS1_Gateway
 SG_ MO_E_Texte  : 36|4@1+ (1.000000,0.000000) [0.000000|15.000000] "" ICAS1_Gateway
 SG_ WIV_Oeldyn_avl  : 40|1@1+ (1.000000,0.000000) [0.000000|1.000000] "" ICAS1_Gateway
 SG_ MO_Text_Partikelfil_Reg  : 41|1@1+ (1.000000,0.000000) [0.000000|1.000000] "" ICAS1_Gateway
 SG_ OLEV_Oelstand_nicht_vorhanden  : 42|1@1+ (1.000000,0.000000) [0.000000|1.000000] "" ICAS1_Gateway
 SG_ WIV_Oelmenge  : 43|5@1+ (125.000000,0.000000) [0.000000|3875.000000] "Unit_MilliLiter" ICAS1_Gateway
 SG_ MO_Systemlampe  : 48|1@1+ (1.000000,0.000000) [0.000000|1.000000] "" ICAS1_Gateway
 SG_ MO_OBD2_Lampe  : 49|1@1+ (1.000000,0.000000) [0.000000|1.000000] "" ICAS1_Gateway
 SG_ MO_Heissleuchte  : 50|1@1+ (1.000000,0.000000) [0.000000|1.000000] "" ICAS1_Gateway
 SG_ MO_Partikel_Lampe  : 51|1@1+ (1.000000,0.000000) [0.000000|1.000000] "" ICAS1_Gateway
 SG_ MO_RedFahrleistung_Lampe  : 52|1@1+ (1.000000,0.000000) [0.000000|1.000000] "" ICAS1_Gateway ICAS1_KommunikationsServer
 SG_ WIV_Oelstand_nicht_vorhanden  : 53|1@1+ (1.000000,0.000000) [0.000000|1.000000] "" ICAS1_Gateway
 SG_ WIV_nachfuellanzeige_ein  : 54|1@1+ (1.000000,0.000000) [0.000000|1.000000] "" ICAS1_Gateway
 SG_ WIV_Ueberfuell_deaktiv  : 55|1@1+ (1.000000,0.000000) [0.000000|1.000000] "" ICAS1_Gateway
 SG_ WIV_Unterfuell_Warn  : 56|1@1+ (1.000000,0.000000) [0.000000|1.000000] "" ICAS1_Gateway
 SG_ MO_Tankdeckel_Lampe  : 57|1@1+ (1.000000,0.000000) [0.000000|1.000000] "" ICAS1_Gateway
 SG_ MO_Text_Tankdeckelwarn  : 58|1@1+ (1.000000,0.000000) [0.000000|1.000000] "" ICAS1_Gateway
 SG_ MO_Vorglueh_Lampe  : 59|1@1+ (1.000000,0.000000) [0.000000|1.000000] "" ICAS1_Gateway
 SG_ WIV_Oeldr_Warn_Motor  : 60|1@1+ (1.000000,0.000000) [0.000000|1.000000] "" ICAS1_Gateway
 SG_ MO_E_Mode  : 61|3@1+ (1.000000,0.000000) [0.000000|7.000000] "" ICAS1_Gateway

BO_ 706 Motor_41: 8 Motor_BEV
 SG_ MO_Anzeige_StSt_Text  : 12|4@1+ (1.000000,0.000000) [0.000000|15.000000] "" Vector__XXX
 SG_ MO_Anzeige_StSt_Symbol  : 16|3@1+ (1.000000,0.000000) [0.000000|7.000000] "" Vector__XXX
 SG_ MO_ADR_Status  : 19|2@1+ (1.000000,0.000000) [0.000000|3.000000] "" Vector__XXX
 SG_ MO_AGA_Sound_Texte  : 21|2@1+ (1.000000,0.000000) [0.000000|3.000000] "" Vector__XXX
 SG_ MO_Anzeige_FMAus_Text  : 23|1@1+ (1.000000,0.000000) [0.000000|1.000000] "" Vector__XXX
 SG_ PEA_Texte  : 25|3@1+ (1.000000,0.000000) [0.000000|7.000000] "" Vector__XXX
 SG_ TSK_Ueberstimmt_vMax_FahrerInfo  : 28|2@1+ (1.000000,0.000000) [0.000000|3.000000] "" Vector__XXX
 SG_ MO_Rekuperationsstufe  : 32|3@1+ (1.000000,0.000000) [0.000000|7.000000] "" ICAS1_KommunikationsServer
 SG_ TSK_Einheit_vMax_FahrerInfo  : 35|1@1+ (1.000000,0.000000) [0.000000|1.000000] "" ICAS1_KommunikationsServer
 SG_ TSK_Status_vMax_FahrerInfo  : 36|2@1+ (1.000000,0.000000) [0.000000|3.000000] "" ICAS1_KommunikationsServer
 SG_ MO_Anz_Kuehlerluefter  : 47|3@1+ (1.000000,0.000000) [0.000000|7.000000] "" Vector__XXX
 SG_ FDR_Warnung_ALR  : 50|2@1+ (1.000000,0.000000) [0.000000|3.000000] "" ICAS1_KommunikationsServer
 SG_ TSK_vMax_FahrerInfo  : 56|8@1+ (1.000000,15.000000) [16.000000|270.000000] "" ICAS1_KommunikationsServer

BO_ 267 Motor_51: 32 Motor_BEV
 SG_ Motor_51_CRC  : 0|8@1+ (1.000000,0.000000) [0.000000|255.000000] "" ICAS1_Gateway
 SG_ Motor_51_BZ  : 8|4@1+ (1.000000,0.000000) [0.000000|15.000000] "" ICAS1_Gateway
 SG_ MO_Fahrpedalrohwert_01  : 12|8@1+ (0.400000,0.000000) [0.000000|101.600000] "Unit_PerCent" Airbag ICAS1_Gateway
 SG_ MO_QBit_Fahrpedalwerte_01  : 20|1@1+ (1.000000,0.000000) [0.000000|1.000000] "" Airbag ICAS1_Gateway
 SG_ MO_Fahrpedalgradient  : 21|8@1+ (25.000000,0.000000) [0.000000|6350.000000] "Unit_PerCentPerSecon" ICAS1_Gateway
 SG_ MO_Sig_Fahrpedalgradient  : 29|1@1+ (1.000000,0.000000) [0.000000|1.000000] "" ICAS1_Gateway
 SG_ MO_rel_Saugrohrdruck  : 30|6@1+ (18.000000,0.000000) [0.000000|1116.000000] "Unit_MilliBar" ICAS1_Gateway
 SG_ MO_rel_Saugrohrdruck_gem_err  : 36|1@1+ (1.000000,0.000000) [0.000000|1.000000] "" ICAS1_Gateway
 SG_ MO_Moment_im_Leerlauf  : 37|1@1+ (1.000000,0.000000) [0.000000|1.000000] "" ICAS1_Gateway
 SG_ MO_Schubabschaltung  : 38|1@1+ (1.000000,0.000000) [0.000000|1.000000] "" ICAS1_Gateway
 SG_ MO_Solldrehz_Leerlauf  : 40|8@1+ (10.000000,0.000000) [0.000000|2540.000000] "Unit_MinutInver" ICAS1_Gateway
 SG_ MO_Entkopplung_Sollschlupf  : 48|7@1+ (20.000000,0.000000) [0.000000|2480.000000] "Unit_MinutInver" ICAS1_Gateway
 SG_ MO_temporaere_Fahrerabwesenheit  : 55|1@1+ (1.000000,0.000000) [0.000000|1.000000] "" ICAS1_Gateway
 SG_ TSK_a_Soll_gradientenbegrenzt  : 57|7@1+ (0.100000,-7.200000) [-7.200000|5.400000] "Unit_MeterPerSeconSquar" ICAS1_Gateway
 SG_ TSK_Radbremsmom  : 76|12@1+ (8.000000,0.000000) [0.000000|32760.000000] "Unit_NewtoMeter" ICAS1_Gateway
 SG_ TSK_Status  : 88|3@1+ (1.000000,0.000000) [0.000000|7.000000] "" ICAS1_Gateway
 SG_ TSK_v_Begrenzung_aktiv  : 91|1@1+ (1.000000,0.000000) [0.000000|1.000000] "" ICAS1_Gateway
 SG_ TSK_Standby_Anf_ESP  : 92|1@1+ (1.000000,0.000000) [0.000000|1.000000] "" ICAS1_Gateway
 SG_ TSK_Freig_WU  : 93|1@1+ (1.000000,0.000000) [0.000000|1.000000] "" ICAS1_Gateway
 SG_ TSK_Freig_Verzoeg_Anf  : 94|1@1+ (1.000000,0.000000) [0.000000|1.000000] "" ICAS1_Gateway
 SG_ TSK_Limiter_ausgewaehlt  : 95|1@1+ (1.000000,0.000000) [0.000000|1.000000] "" ICAS1_Gateway
 SG_ TSK_Wunsch_Uebersetz  : 96|10@1+ (0.024500,0.000000) [0.024500|25.063500] "" ICAS1_Gateway
 SG_ TSK_Hauptschalter_GRA_ACC  : 106|2@1+ (1.000000,0.000000) [0.000000|3.000000] "" ICAS1_Gateway ICAS1_KommunikationsServer
 SG_ TSK_SRBM_Anf_ASIL  : 108|3@1+ (1.000000,0.000000) [0.000000|7.000000] "" ICAS1_Gateway
 SG_ TSK_ax_Getriebe_02  : 112|9@1+ (0.024000,-2.016000) [-2.016000|10.224000] "Unit_MeterPerSeconSquar" ICAS1_Gateway
 SG_ TSK_Zwangszusch_ESP  : 121|1@1+ (1.000000,0.000000) [0.000000|1.000000] "" ICAS1_Gateway
 SG_ TSK_zul_Regelabw  : 122|6@1+ (0.024000,0.000000) [0.000000|1.512000] "Unit_MeterPerSeconSquar" ICAS1_Gateway
 SG_ MO_Status_MinDrzEingriff  : 235|3@1+ (1.000000,0.000000) [0.000000|7.000000] "" ICAS1_Gateway
 SG_ MO_Status_MaxDrzEingriff  : 238|3@1+ (1.000000,0.000000) [0.000000|7.000000] "" ICAS1_Gateway
 SG_ MO_Status_MinDrzEingriff_sek  : 241|3@1+ (1.000000,0.000000) [0.000000|7.000000] "" ICAS1_Gateway
 SG_ MO_Status_MaxDrzEingriff_sek  : 244|3@1+ (1.000000,0.000000) [0.000000|7.000000] "" ICAS1_Gateway
 SG_ GRA_KuFu_aktiv  : 247|1@1+ (1.000000,0.000000) [0.000000|1.000000] "" ICAS1_Gateway
 SG_ TSK_SRBM_max_Gradient  : 248|7@1+ (50.000000,0.000000) [0.000000|6250.000000] "Unit_NewtoMeterPerSecon" ICAS1_Gateway
 SG_ LIM_KuFu_aktiv  : 255|1@1+ (1.000000,0.000000) [0.000000|1.000000] "" ICAS1_Gateway

BO_ 330 Motor_52: 32 Motor_BEV
 SG_ MO_Hochschaltdrehz  : 21|12@1+ (3.000000,0.000000) [3.000000|12282.000000] "Unit_MinutInver" Vector__XXX
 SG_ MO_Anzeige_Verbr_Einheit  : 33|2@1+ (1.000000,0.000000) [0.000000|3.000000] "" Vector__XXX
 SG_ MO_Schaltblitz_Anz  : 35|7@1+ (1.000000,0.000000) [0.000000|100.000000] "Unit_PerCent" Vector__XXX
 SG_ MO_Anzeige_Drehmoment  : 42|11@1+ (1.000000,0.000000) [0.000000|2045.000000] "Unit_NewtoMeter" Vector__XXX
 SG_ MO_Anzeige_Leistung  : 53|11@1+ (0.600000,0.000000) [0.000000|1227.000000] "Unit_KiloWatt" Vector__XXX
 SG_ MO_rel_Ladedruck  : 64|8@1+ (0.400000,0.000000) [0.000000|100.000000] "Unit_PerCent" Vector__XXX
 SG_ MO_Istgang  : 72|4@1+ (1.000000,0.000000) [0.000000|15.000000] "" Vector__XXX
 SG_ MO_Sollgang  : 76|4@1+ (1.000000,0.000000) [0.000000|15.000000] "" Vector__XXX
 SG_ MO_Oeldruck  : 80|8@1+ (0.040000,0.000000) [0.000000|10.000000] "Unit_Bar" Vector__XXX
 SG_ MO_Anzeigedrehz  : 88|12@1+ (3.000000,0.000000) [0.000000|12282.000000] "Unit_MinutInver" Vector__XXX
 SG_ MO_Effizienzmodus  : 100|1@1+ (1.000000,0.000000) [0.000000|1.000000] "" Vector__XXX
 SG_ MO_Fehler_Oeldrucksensor  : 101|1@1+ (1.000000,0.000000) [0.000000|1.000000] "" Vector__XXX
 SG_ MO_Schaltempf_verfbar  : 102|1@1+ (1.000000,0.000000) [0.000000|1.000000] "" Vector__XXX
 SG_ MO_Ladedruck  : 103|9@1+ (0.010000,0.000000) [0.000000|5.100000] "Unit_Bar" Vector__XXX
 SG_ MO_KVS  : 112|15@1+ (1.000000,0.000000) [0.000000|32767.000000] "Unit_MicroLiter" Vector__XXX
 SG_ MO_KVS_Ueberlauf  : 127|1@1+ (1.000000,0.000000) [0.000000|1.000000] "" Vector__XXX
 SG_ MO_ePowermeter  : 128|8@1+ (0.400000,-0.400000) [0.000000|100.800000] "Unit_PerCent" Vector__XXX
 SG_ MO_ePerformance  : 136|8@1+ (0.400000,-0.400000) [0.000000|100.800000] "Unit_PerCent" ICAS1_KommunikationsServer
 SG_ MO_Zust_Antrieb  : 144|4@1+ (1.000000,0.000000) [0.000000|15.000000] "" Vector__XXX
 SG_ MO_Zust_Betriebsstrategie  : 148|3@1+ (1.000000,0.000000) [0.000000|7.000000] "" Vector__XXX
 SG_ Ladezustand_02  : 152|8@1+ (0.500000,0.000000) [0.000000|100.000000] "Unit_PerCent" ICAS1_Gateway ICAS1_KommunikationsServer
 SG_ MO_Powermeter_Elm_02  : 168|12@1+ (0.050000,-102.400000) [-100.000000|100.000000] "Unit_PerCent" Vector__XXX
 SG_ MO_Powermeter  : 180|12@1+ (1.000000,0.000000) [0.000000|4092.000000] "" ICAS1_KommunikationsServer

BO_ 512 Motor_53: 32 Motor_BEV
 SG_ TSK_Wunschgeschw  : 12|10@1+ (0.320000,0.000000) [0.000000|326.720000] "Unit_KiloMeterPerHour" ICAS1_Gateway ICAS1_KommunikationsServer
 SG_ TSK_praediktiver_Hinweis  : 22|3@1+ (1.000000,0.000000) [0.000000|7.000000] "" ICAS1_Gateway
 SG_ TSK_naechstes_Event  : 25|6@1+ (1.000000,0.000000) [0.000000|63.000000] "" ICAS1_Gateway
 SG_ TSK_Fahrzeugstatus_praed_Fkt  : 31|3@1+ (1.000000,0.000000) [0.000000|7.000000] "" ICAS1_Gateway
 SG_ TSK_Texte  : 40|5@1+ (1.000000,0.000000) [0.000000|31.000000] "" ICAS1_Gateway ICAS1_KommunikationsServer
 SG_ TSK_Akustik  : 45|3@1+ (1.000000,0.000000) [0.000000|7.000000] "" ICAS1_Gateway ICAS1_KommunikationsServer
 SG_ TSK_Texte_Primaeranz  : 48|5@1+ (1.000000,0.000000) [0.000000|31.000000] "" ICAS1_Gateway ICAS1_KommunikationsServer
 SG_ TSK_Limiter_Fahrerinfo  : 53|2@1+ (1.000000,0.000000) [0.000000|3.000000] "" ICAS1_Gateway ICAS1_KommunikationsServer
 SG_ TSK_Limiter_Anzeige  : 55|1@1+ (1.000000,0.000000) [0.000000|1.000000] "" ICAS1_Gateway ICAS1_KommunikationsServer
 SG_ TSK_Fahrzeugstatus_GRA  : 56|1@1+ (1.000000,0.000000) [0.000000|1.000000] "" ICAS1_Gateway ICAS1_KommunikationsServer
 SG_ TSK_Fahrzeugstatus_Limiter  : 57|1@1+ (1.000000,0.000000) [0.000000|1.000000] "" ICAS1_Gateway ICAS1_KommunikationsServer
 SG_ MO_Motorlaufwarnung  : 58|1@1+ (1.000000,0.000000) [0.000000|1.000000] "" ICAS1_Gateway
 SG_ TSK_naechstes_Event_Einheit  : 60|1@1+ (1.000000,0.000000) [0.000000|1.000000] "" ICAS1_Gateway
 SG_ TSK_Status_Anzeige  : 61|3@1+ (1.000000,0.000000) [0.000000|7.000000] "" ICAS1_Gateway ICAS1_KommunikationsServer
 SG_ MO_Sperrung_FahrPr_BZS  : 64|8@1+ (1.000000,0.000000) [0.000000|255.000000] "" ICAS1_Gateway
 SG_ MO_Rampenzeit_Generator_Anf  : 72|4@1+ (1.000000,0.000000) [0.000000|15.000000] "" ICAS1_Gateway
 SG_ MO_Prio_MAX_Wunschdrehzahl  : 76|1@1+ (1.000000,0.000000) [0.000000|1.000000] "" ICAS1_Gateway
 SG_ MO_Prio_MIN_Wunschdrehzahl  : 77|1@1+ (1.000000,0.000000) [0.000000|1.000000] "" ICAS1_Gateway
 SG_ MO_Luftpfad_aktiv  : 78|1@1+ (1.000000,0.000000) [0.000000|1.000000] "" ICAS1_Gateway
 SG_ MO_v_Begrenz_Aktivierbar  : 79|1@1+ (1.000000,0.000000) [0.000000|1.000000] "" ICAS1_Gateway
 SG_ MO_Drehzahlbeeinflussung  : 80|8@1+ (0.390000,0.000000) [0.000000|99.450000] "Unit_PerCent" ICAS1_Gateway
 SG_ MO_MIN_Wunschdrehzahl  : 88|8@1+ (25.000000,0.000000) [0.000000|6350.000000] "Unit_MinutInver" ICAS1_Gateway
 SG_ MO_MAX_Wunschdrehzahl  : 96|9@1+ (25.000000,0.000000) [0.000000|12750.000000] "Unit_MinutInver" ICAS1_Gateway
 SG_ MO_Charisma_FahrPr  : 105|4@1+ (1.000000,0.000000) [0.000000|15.000000] "" ICAS1_Gateway
 SG_ MO_Charisma_Status  : 109|2@1+ (1.000000,0.000000) [0.000000|3.000000] "" ICAS1_Gateway
 SG_ MO_StSt_Charisma_FahrPr  : 111|4@1+ (1.000000,0.000000) [0.000000|15.000000] "" ICAS1_Gateway
 SG_ MO_StSt_Charisma_Status  : 115|2@1+ (1.000000,0.000000) [0.000000|3.000000] "" ICAS1_Gateway
 SG_ MO_BZS_Charisma_FahrPr  : 117|4@1+ (1.000000,0.000000) [0.000000|15.000000] "" ICAS1_Gateway
 SG_ MO_BZS_Charisma_Status  : 121|2@1+ (1.000000,0.000000) [0.000000|3.000000] "" ICAS1_Gateway
 SG_ MO_NGS_Position  : 123|1@1+ (1.000000,0.000000) [0.000000|1.000000] "" ICAS1_Gateway
 SG_ MO_NGS_Status  : 124|2@1+ (1.000000,0.000000) [0.000000|3.000000] "" ICAS1_Gateway
 SG_ MO_v_Begrenzung_Niveau  : 126|2@1+ (1.000000,0.000000) [0.000000|3.000000] "" ICAS1_Gateway
 SG_ MO_Anzeige_Rekuperation  : 128|8@1+ (0.500000,-0.500000) [0.000000|100.000000] "Unit_PerCent" ICAS1_Gateway
 SG_ PEA_Fortschrittsanzeige  : 136|7@1+ (1.000000,0.000000) [0.000000|100.000000] "Unit_PerCent" ICAS1_Gateway
 SG_ MO_Anzeige_Fahrbereitschaft  : 143|1@1+ (1.000000,0.000000) [0.000000|1.000000] "" ICAS1_Gateway ICAS1_KommunikationsServer
 SG_ MO_Boost_verfuegbar  : 144|8@1+ (0.400000,-0.400000) [0.000000|100.400000] "Unit_PerCent" ICAS1_Gateway
 SG_ MO_Overboost  : 152|1@1+ (1.000000,0.000000) [0.000000|1.000000] "" ICAS1_Gateway
 SG_ MO_Boost_aktiv  : 153|1@1+ (1.000000,0.000000) [0.000000|1.000000] "" ICAS1_Gateway
 SG_ MO_Anzeige_Betriebsmodus  : 154|4@1+ (1.000000,0.000000) [0.000000|15.000000] "" ICAS1_Gateway
 SG_ PEA_Hinweis  : 158|2@1+ (1.000000,0.000000) [0.000000|3.000000] "" ICAS1_Gateway
 SG_ PEA_Ereignisanzeige  : 160|5@1+ (1.000000,0.000000) [0.000000|31.000000] "" ICAS1_Gateway
 SG_ PEA_Ereignisanzeige_temporaer  : 165|1@1+ (1.000000,0.000000) [0.000000|1.000000] "" ICAS1_Gateway
 SG_ PEA_Abschalttexte  : 166|2@1+ (1.000000,0.000000) [0.000000|3.000000] "" ICAS1_Gateway
 SG_ PEA_Zielgeschw_Einheit  : 168|1@1+ (1.000000,0.000000) [0.000000|1.000000] "" ICAS1_Gateway
 SG_ PEA_Zielgeschw  : 169|5@1+ (1.000000,0.000000) [0.000000|31.000000] "" ICAS1_Gateway
 SG_ MO_Antriebsstrang_Warnung_HS  : 174|2@1+ (1.000000,0.000000) [0.000000|3.000000] "" ICAS1_Gateway
 SG_ MO_Anzeige_Verbrauch_oE  : 176|16@1+ (0.005000,0.000000) [0.000000|327.675000] "Unit_None" ICAS1_Gateway

BO_ 332 Motor_54: 32 Motor_BEV
 SG_ MO_Anforderung_HMS  : 12|3@1+ (1.000000,0.000000) [0.000000|7.000000] "" ICAS1_Gateway
 SG_ FoD_DTC_TSK_GRA  : 15|1@1+ (1.000000,0.000000) [0.000000|1.000000] "" ICAS1_Gateway
 SG_ TSK_vMax_aktuell  : 16|8@1+ (1.000000,0.000000) [0.000000|253.000000] "Unit_KiloMeterPerHour" ICAS1_Gateway
 SG_ TSK_Status_EA  : 32|3@1+ (1.000000,0.000000) [0.000000|7.000000] "" ICAS1_Gateway
 SG_ FoD_DTC_TSK_ACC  : 35|1@1+ (1.000000,0.000000) [0.000000|1.000000] "" ICAS1_Gateway
 SG_ TSK_ACC_FoD_Status  : 36|2@1+ (1.000000,0.000000) [0.000000|3.000000] "" ICAS1_Gateway
 SG_ TSK_GRA_FoD_Status  : 38|2@1+ (1.000000,0.000000) [0.000000|3.000000] "" ICAS1_Gateway
 SG_ TSK_vMax_Fahrerassistenz  : 40|9@1+ (1.000000,0.000000) [0.000000|510.000000] "" ICAS1_Gateway
 SG_ TSK_Einheit_vMax_Fahrerassistenz  : 49|1@1+ (1.000000,0.000000) [0.000000|1.000000] "" ICAS1_Gateway
 SG_ TSK_Status_PLA  : 50|3@1+ (1.000000,0.000000) [0.000000|7.000000] "" ICAS1_Gateway
 SG_ TSK_aktives_System  : 53|3@1+ (1.000000,0.000000) [0.000000|7.000000] "" ICAS1_Gateway
 SG_ TSK_erhoehter_Fahrwiderstand  : 56|1@1+ (1.000000,0.000000) [0.000000|1.000000] "" ICAS1_Gateway
 SG_ TSK_Anf_Antriebsmoment  : 57|1@1+ (1.000000,0.000000) [0.000000|1.000000] "" ICAS1_Gateway
 SG_ TSK_Status_ARA  : 58|3@1+ (1.000000,0.000000) [0.000000|7.000000] "" ICAS1_Gateway
 SG_ TSK_Status_IPA  : 61|3@1+ (1.000000,0.000000) [0.000000|7.000000] "" ICAS1_Gateway
 SG_ MO_Fahrbereitschaft  : 76|2@1+ (1.000000,0.000000) [0.000000|3.000000] "" ICAS1_Gateway LE1 LE2
 SG_ MO_Freilauf_Info  : 78|2@1+ (1.000000,0.000000) [0.000000|3.000000] "" ICAS1_Gateway
 SG_ MO_Krit_Heckobjekt  : 81|3@1+ (1.000000,0.000000) [0.000000|7.000000] "" ICAS1_Gateway
 SG_ MO_NGS_Gangpos  : 84|3@1+ (1.000000,0.000000) [0.000000|7.000000] "" ICAS1_Gateway
 SG_ MO_Freilauf_Status  : 87|3@1+ (1.000000,0.000000) [0.000000|7.000000] "" ICAS1_Gateway
 SG_ MO_EBoost_verf_praed  : 90|2@1+ (1.000000,0.000000) [0.000000|3.000000] "" ICAS1_Gateway
 SG_ MO_Heckspoiler_Anf  : 92|1@1+ (1.000000,0.000000) [0.000000|1.000000] "" ICAS1_Gateway
 SG_ MO_eLaunch_verf  : 93|2@1+ (1.000000,0.000000) [0.000000|3.000000] "" ICAS1_Gateway
 SG_ MO_Positionierung_aktiv  : 95|1@1+ (1.000000,0.000000) [0.000000|1.000000] "" ICAS1_Gateway
 SG_ MO_Freilauf_Typ  : 98|2@1+ (1.000000,0.000000) [0.000000|3.000000] "" ICAS1_Gateway
 SG_ MO_Startwunsch  : 100|1@1+ (1.000000,0.000000) [0.000000|1.000000] "" ICAS1_Gateway
 SG_ OBD_Calc_Load_Val  : 128|8@1+ (0.392157,0.000000) [0.000000|100.000000] "Unit_PerCent" ICAS1_Gateway LE1 LE2
 SG_ OBD_Eng_Cool_Temp  : 136|8@1+ (1.000000,-40.000000) [-40.000000|215.000000] "Unit_DegreCelsi" ICAS1_Gateway LE1 LE2
 SG_ OBD_Abs_Throttle_Pos  : 144|8@1+ (0.392157,0.000000) [0.000000|100.000000] "Unit_PerCent" ICAS1_Gateway LE1 LE2
 SG_ OBD_Abs_Load_Val  : 152|16@1+ (0.392157,0.000000) [0.000000|25700.000000] "Unit_PerCent" ICAS1_Gateway LE1 LE2
 SG_ OBD_Abs_Pedal_Pos  : 168|8@1+ (0.392157,0.000000) [0.000000|100.000000] "Unit_PerCent" ICAS1_Gateway LE1 LE2
 SG_ MO_Servicemodus  : 176|4@1+ (1.000000,0.000000) [0.000000|15.000000] "" ICAS1_Gateway LE1 LE2
 SG_ OBD_ClearMem_Inhibit  : 183|1@1+ (1.000000,0.000000) [0.000000|1.000000] "" ICAS1_Gateway LE1 LE2
 SG_ OBD_Sperrung_Kaltstart_Denom  : 184|1@1+ (1.000000,0.000000) [0.000000|1.000000] "" ICAS1_Gateway LE1 LE2
 SG_ MO_QBit_Aussen_Temp  : 185|1@1+ (1.000000,0.000000) [0.000000|1.000000] "" ICAS1_Gateway
 SG_ OBD_Sperrung_IUMPR  : 186|1@1+ (1.000000,0.000000) [0.000000|1.000000] "" ICAS1_Gateway LE1 LE2
 SG_ OBD_Kaltstart_Denominator  : 187|1@1+ (1.000000,0.000000) [0.000000|1.000000] "" ICAS1_Gateway LE1 LE2
 SG_ OBD_Minimum_Trip  : 188|1@1+ (1.000000,0.000000) [0.000000|1.000000] "" ICAS1_Gateway LE1 LE2
 SG_ OBD_Driving_Cycle  : 189|1@1+ (1.000000,0.000000) [0.000000|1.000000] "" ICAS1_Gateway LE1 LE2
 SG_ OBD_Warm_Up_Cycle  : 190|1@1+ (1.000000,0.000000) [0.000000|1.000000] "" ICAS1_Gateway LE1 LE2
 SG_ OBD_Normed_Trip  : 191|1@1+ (1.000000,0.000000) [0.000000|1.000000] "" ICAS1_Gateway LE1 LE2
 SG_ OBD_Aussen_Temp_gef  : 248|8@1+ (1.000000,-40.000000) [-40.000000|213.000000] "Unit_DegreCelsi" ICAS1_Gateway

BO_ 246 Motor_55: 32 Motor_BEV
 SG_ Motor_55_CRC  : 0|8@1+ (1.000000,0.000000) [0.000000|255.000000] "" ICAS1_Gateway
 SG_ Motor_55_BZ  : 8|4@1+ (1.000000,0.000000) [0.000000|15.000000] "" ICAS1_Gateway
 SG_ TS_Faktor_Radmomente  : 12|2@1+ (1.000000,0.000000) [0.000000|3.000000] "" ICAS1_Gateway
 SG_ TS_Status_MomRad_Ist  : 14|2@1+ (1.000000,0.000000) [0.000000|3.000000] "" ICAS1_Gateway
 SG_ TS_MomRad_verfuegb_maxReku_Summe  : 16|12@1+ (3.000000,-12279.000000) [-12279.000000|0.000000] "" ICAS1_Gateway
 SG_ TS_MomRad_Ist  : 28|13@1+ (3.000000,-12279.000000) [-12279.000000|12279.000000] "Unit_None" ICAS1_Gateway
 SG_ TS_MomRad_Soll_Summe  : 41|13@1+ (3.000000,-12279.000000) [-12279.000000|12279.000000] "Unit_None" ICAS1_Gateway
 SG_ TS_MomRad_Wunsch  : 54|13@1+ (3.000000,-12279.000000) [-12279.000000|12279.000000] "Unit_None" ICAS1_Gateway
 SG_ TS_MomRad_Wunsch_sek  : 67|13@1+ (3.000000,-12279.000000) [-12279.000000|12279.000000] "Unit_None" ICAS1_Gateway
 SG_ TS_MomRad_verfuegb_max  : 80|12@1+ (3.000000,0.000000) [0.000000|12279.000000] "Unit_None" ICAS1_Gateway
 SG_ TS_MomRad_verfuegb_max_sek  : 92|12@1+ (3.000000,0.000000) [0.000000|12279.000000] "Unit_None" ICAS1_Gateway
 SG_ TS_MomRad_verfuegb_maxReku  : 104|12@1+ (3.000000,-12279.000000) [-12279.000000|0.000000] "Unit_None" ICAS1_Gateway
 SG_ TS_MomRad_verfuegb_maxReku_sek  : 116|12@1+ (3.000000,-12279.000000) [-12279.000000|0.000000] "Unit_None" ICAS1_Gateway
 SG_ TS_MomRad_Ist_sek  : 128|13@1+ (3.000000,-12279.000000) [-12279.000000|12279.000000] "Unit_None" ICAS1_Gateway
 SG_ TS_Allrad_Anteil_sek  : 141|9@1+ (0.200000,0.000000) [0.000000|100.000000] "Unit_PerCent" ICAS1_Gateway
 SG_ FDR_Allrad_Anteil_max_sek  : 150|9@1+ (0.200000,0.000000) [0.000000|100.000000] "Unit_PerCent" ICAS1_Gateway
 SG_ FDR_Allrad_Anteil_min_sek  : 159|9@1+ (0.200000,0.000000) [0.000000|100.000000] "Unit_PerCent" ICAS1_Gateway
 SG_ FDR_MomRad_Eingriff  : 168|13@1+ (3.000000,-12279.000000) [-12279.000000|12279.000000] "Unit_NewtoMeter" ICAS1_Gateway
 SG_ FDR_Status_Eingriff  : 181|1@1+ (1.000000,0.000000) [0.000000|1.000000] "" ICAS1_Gateway
 SG_ FDR_MomRad_Eingriff_sek  : 182|13@1+ (3.000000,-12279.000000) [-12279.000000|12279.000000] "Unit_NewtoMeter" ICAS1_Gateway
 SG_ FDR_Status_Eingriff_sek  : 195|1@1+ (1.000000,0.000000) [0.000000|1.000000] "" ICAS1_Gateway

BO_ 190 Motor_56: 48 Motor_BEV
 SG_ Motor_56_CRC  : 0|8@1+ (1.000000,0.000000) [0.000000|255.000000] "" ICAS1_Gateway LE1 LE2
 SG_ Motor_56_BZ  : 8|4@1+ (1.000000,0.000000) [0.000000|15.000000] "" ICAS1_Gateway LE1 LE2
 SG_ MO_EM1_MinDrehzahl  : 12|14@1+ (2.000000,-10000.000000) [-10000.000000|22764.000000] "Unit_MinutInver" ICAS1_Gateway LE1
 SG_ MO_EM1_MaxDrehzahl  : 26|14@1+ (2.000000,-10000.000000) [-10000.000000|22764.000000] "Unit_MinutInver" ICAS1_Gateway LE1
 SG_ MO_EM1_DynLimit_AR  : 40|8@1+ (1.000000,0.000000) [0.000000|254.000000] "Unit_NewtoMeter" ICAS1_Gateway LE1
 SG_ MO_EM1_Periode_AR  : 48|8@1+ (0.001953,0.000000) [0.000000|0.496094] "Unit_Secon" ICAS1_Gateway LE1
 SG_ MO_EM1_SollMoment  : 56|12@1+ (0.500000,-1023.000000) [-1023.000000|1023.500000] "Unit_NewtoMeter" ICAS1_Gateway LE1
 SG_ MO_EM1_Sollmodus  : 68|4@1+ (1.000000,0.000000) [0.000000|15.000000] "" ICAS1_Gateway LE1
 SG_ MO_EM1_Min_Leistung  : 72|14@1+ (100.000000,-819000.000000) [-819000.000000|819100.000000] "Unit_Watt" ICAS1_Gateway LE1
 SG_ MO_EM1_Max_Leistung  : 86|14@1+ (100.000000,-819000.000000) [-819000.000000|819100.000000] "Unit_Watt" ICAS1_Gateway LE1
 SG_ MO_EM1_Min_Strom_Lim  : 100|13@1+ (0.500000,-2047.000000) [-2047.000000|2047.500000] "Unit_Amper" ICAS1_Gateway LE1
 SG_ MO_EM1_Max_Strom_Lim  : 113|13@1+ (0.500000,-2047.000000) [-2047.000000|2047.500000] "Unit_Amper" ICAS1_Gateway LE1
 SG_ MO_EM1_AR_Anf  : 126|3@1+ (1.000000,0.000000) [0.000000|7.000000] "" ICAS1_Gateway LE1
 SG_ MO_EM1_Kp_AR  : 129|9@1+ (0.003906,0.000000) [0.000000|1.992188] "Unit_NewtoMeterPerRPM" ICAS1_Gateway LE1
 SG_ MO_EM1_SollSpannung  : 138|12@1+ (0.500000,0.000000) [0.000000|2047.000000] "Unit_Volt" ICAS1_Gateway LE1
 SG_ MO_EM2_MinDrehzahl  : 156|14@1+ (2.000000,-10000.000000) [-10000.000000|22764.000000] "Unit_MinutInver" ICAS1_Gateway LE2
 SG_ MO_EM2_MaxDrehzahl  : 170|14@1+ (2.000000,-10000.000000) [-10000.000000|22764.000000] "Unit_MinutInver" ICAS1_Gateway LE2
 SG_ MO_EM2_DynLimit_AR  : 184|8@1+ (1.000000,0.000000) [0.000000|254.000000] "Unit_NewtoMeter" ICAS1_Gateway LE2
 SG_ MO_EM2_Periode_AR  : 192|8@1+ (0.001953,0.000000) [0.000000|0.496094] "Unit_Secon" ICAS1_Gateway LE2
 SG_ MO_EM2_SollMoment  : 200|12@1+ (0.500000,-1023.000000) [-1023.000000|1023.500000] "Unit_NewtoMeter" ICAS1_Gateway LE2
 SG_ MO_EM2_Sollmodus  : 212|4@1+ (1.000000,0.000000) [0.000000|15.000000] "" ICAS1_Gateway LE2
 SG_ MO_EM2_Min_Leistung  : 216|14@1+ (100.000000,-819000.000000) [-819000.000000|819100.000000] "Unit_Watt" ICAS1_Gateway LE2
 SG_ MO_EM2_Max_Leistung  : 230|14@1+ (100.000000,-819000.000000) [-819000.000000|819100.000000] "Unit_Watt" ICAS1_Gateway LE2
 SG_ MO_EM2_Min_Strom_Lim  : 244|13@1+ (0.500000,-2047.000000) [-2047.000000|2047.500000] "Unit_Amper" ICAS1_Gateway LE2
 SG_ MO_EM2_Max_Strom_Lim  : 257|13@1+ (0.500000,-2047.000000) [-2047.000000|2047.500000] "Unit_Amper" ICAS1_Gateway LE2
 SG_ MO_EM2_AR_Anf  : 270|3@1+ (1.000000,0.000000) [0.000000|7.000000] "" ICAS1_Gateway LE2
 SG_ MO_EM2_SollSpannung  : 282|12@1+ (0.500000,0.000000) [0.000000|2047.000000] "Unit_Volt" ICAS1_Gateway LE2
 SG_ MO_DC_Max_Strom_HV  : 296|8@1+ (0.200000,0.000000) [0.000000|50.800000] "Unit_Amper" ICAS1_Gateway
 SG_ MO_DC_SollSpannung_HV  : 304|8@1+ (2.000000,0.000000) [0.000000|508.000000] "Unit_Volt" ICAS1_Gateway
 SG_ MO_EM1_Max_Moment  : 312|12@1+ (0.500000,-1023.000000) [-1023.000000|1023.500000] "Unit_NewtoMeter" ICAS1_Gateway LE1
 SG_ MO_EM1_Min_Moment  : 324|12@1+ (0.500000,-1023.000000) [-1023.000000|1023.500000] "Unit_NewtoMeter" ICAS1_Gateway LE1
 SG_ MO_EM2_Max_Moment  : 336|12@1+ (0.500000,-1023.000000) [-1023.000000|1023.500000] "Unit_NewtoMeter" ICAS1_Gateway LE2
 SG_ MO_EM2_Min_Moment  : 348|12@1+ (0.500000,-1023.000000) [-1023.000000|1023.500000] "Unit_NewtoMeter" ICAS1_Gateway LE2

BO_ 2463978666 Motor_57: 32 Motor_BEV
 SG_ MO_EM1_Min_Spannung_Lim  : 12|10@1+ (1.000000,0.000000) [0.000000|1021.000000] "Unit_Volt" ICAS1_Gateway LE1
 SG_ MO_EM1_Max_Spannung_Lim  : 22|10@1+ (1.000000,0.000000) [0.000000|1021.000000] "Unit_Volt" ICAS1_Gateway LE1
 SG_ MO_EM1_Min_Leistung_Gesamt  : 32|13@1+ (200.000000,-819000.000000) [-819000.000000|818800.000000] "Unit_Watt" ICAS1_Gateway LE1
 SG_ MO_EM1_Max_Leistung_Gesamt  : 45|13@1+ (200.000000,-819000.000000) [-819000.000000|818800.000000] "Unit_Watt" ICAS1_Gateway LE1
 SG_ MO_EM2_Min_Leistung_Gesamt  : 58|13@1+ (200.000000,-819000.000000) [-819000.000000|818800.000000] "Unit_Watt" ICAS1_Gateway LE2
 SG_ MO_EM2_Max_Leistung_Gesamt  : 71|13@1+ (200.000000,-819000.000000) [-819000.000000|818800.000000] "Unit_Watt" ICAS1_Gateway LE2
 SG_ MO_EM2_Min_Spannung_Lim  : 84|10@1+ (1.000000,0.000000) [0.000000|1021.000000] "Unit_Volt" ICAS1_Gateway LE2
 SG_ MO_EM2_Max_Spannung_Lim  : 94|10@1+ (1.000000,0.000000) [0.000000|1021.000000] "Unit_Volt" ICAS1_Gateway LE2
 SG_ MO_EM1_Generator_Leistung  : 104|8@1+ (100.000000,0.000000) [0.000000|25300.000000] "Unit_Watt" ICAS1_Gateway LE1
 SG_ MO_Verbrauch_EM_Ges  : 120|15@1+ (10.000000,0.000000) [0.000000|327670.000000] "Unit_WattSecond" ICAS1_Gateway ICAS1_KommunikationsServer
 SG_ MO_Verbrauch_EM_Ges_Ueberlauf  : 135|1@1+ (1.000000,0.000000) [0.000000|1.000000] "" ICAS1_Gateway ICAS1_KommunikationsServer
 SG_ MO_Rekuperation_Ges_EM  : 136|15@1+ (10.000000,0.000000) [0.000000|327670.000000] "Unit_WattSecond" ICAS1_Gateway ICAS1_KommunikationsServer
 SG_ MO_Rekuperation_EM_Ges_Ueberlauf  : 151|1@1+ (1.000000,0.000000) [0.000000|1.000000] "" ICAS1_Gateway ICAS1_KommunikationsServer
 SG_ MO_Drehzahl_EM  : 152|13@1+ (8.000000,-32768.000000) [-32768.000000|32744.000000] "Unit_RevPerMinute" ICAS1_Gateway
 SG_ MO_Uebersetzung_EM  : 165|10@1+ (0.031250,0.000000) [0.031250|31.906250] "" ICAS1_Gateway
 SG_ MO_Drehzahl_EM_sek  : 175|13@1+ (8.000000,-32768.000000) [-32768.000000|32744.000000] "Unit_RevPerMinute" ICAS1_Gateway
 SG_ MO_Uebersetzung_EM_sek  : 188|10@1+ (0.031250,0.000000) [0.031250|31.906250] "" ICAS1_Gateway

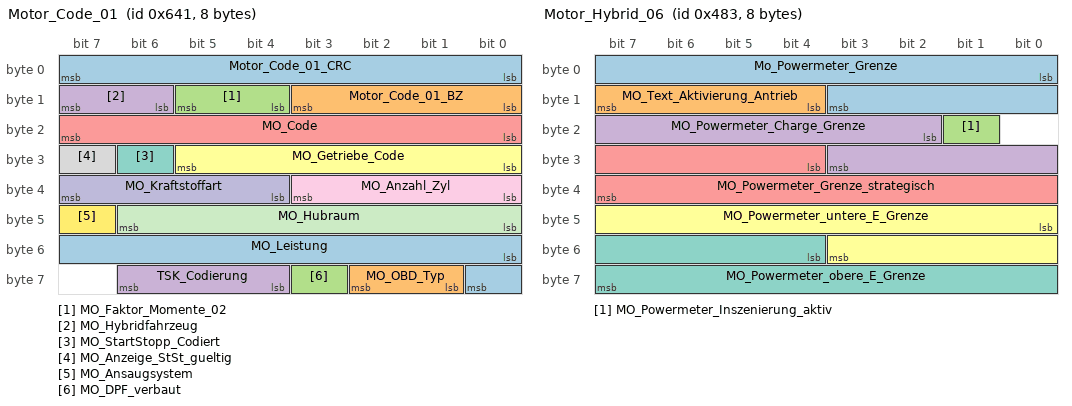
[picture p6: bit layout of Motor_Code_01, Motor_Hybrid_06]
BO_ 1601 Motor_Code_01: 8 Motor_BEV
 SG_ Motor_Code_01_CRC  : 0|8@1+ (1.000000,0.000000) [0.000000|255.000000] "" ICAS1_Gateway
 SG_ Motor_Code_01_BZ  : 8|4@1+ (1.000000,0.000000) [0.000000|15.000000] "" ICAS1_Gateway
 SG_ MO_Faktor_Momente_02  : 12|2@1+ (1.000000,0.000000) [1.000000|3.000000] "Unit_NewtoMeter" ICAS1_Gateway
 SG_ MO_Hybridfahrzeug  : 14|2@1+ (1.000000,0.000000) [0.000000|3.000000] "" ICAS1_Gateway
 SG_ MO_Code  : 16|8@1+ (1.000000,0.000000) [0.000000|255.000000] "" ICAS1_Gateway
 SG_ MO_Getriebe_Code  : 24|6@1+ (1.000000,0.000000) [0.000000|63.000000] "" ICAS1_Gateway
 SG_ MO_StartStopp_Codiert  : 30|1@1+ (1.000000,0.000000) [0.000000|1.000000] "" ICAS1_Gateway
 SG_ MO_Anzeige_StSt_gueltig  : 31|1@1+ (1.000000,0.000000) [0.000000|1.000000] "" ICAS1_Gateway
 SG_ MO_Anzahl_Zyl  : 32|4@1+ (1.000000,0.000000) [0.000000|15.000000] "" ICAS1_Gateway
 SG_ MO_Kraftstoffart  : 36|4@1+ (1.000000,0.000000) [0.000000|15.000000] "" ICAS1_Gateway ICAS1_KommunikationsServer
 SG_ MO_Hubraum  : 40|7@1+ (0.100000,0.000000) [0.000000|12.700000] "Unit_Liter" ICAS1_Gateway
 SG_ MO_Ansaugsystem  : 47|1@1+ (1.000000,0.000000) [0.000000|1.000000] "" ICAS1_Gateway
 SG_ MO_Leistung  : 48|9@1+ (1.000000,0.000000) [0.000000|511.000000] "Unit_KiloWatt" ICAS1_Gateway
 SG_ MO_OBD_Typ  : 57|2@1+ (1.000000,0.000000) [0.000000|3.000000] "" ICAS1_Gateway
 SG_ MO_DPF_verbaut  : 59|1@1+ (1.000000,0.000000) [0.000000|1.000000] "" ICAS1_Gateway
 SG_ TSK_Codierung  : 60|3@1+ (1.000000,0.000000) [0.000000|7.000000] "" ICAS1_Gateway

BO_ 1155 Motor_Hybrid_06: 8 Motor_BEV
 SG_ Mo_Powermeter_Grenze  : 0|12@1+ (1.000000,0.000000) [0.000000|4092.000000] "" ICAS1_KommunikationsServer
 SG_ MO_Text_Aktivierung_Antrieb  : 12|4@1+ (1.000000,0.000000) [0.000000|15.000000] "" ICAS1_KommunikationsServer
 SG_ MO_Powermeter_Inszenierung_aktiv  : 17|1@1+ (1.000000,0.000000) [0.000000|1.000000] "" Vector__XXX
 SG_ MO_Powermeter_Charge_Grenze  : 18|10@1+ (1.000000,0.000000) [0.000000|1021.000000] "Unit_None" ICAS1_KommunikationsServer
 SG_ MO_Powermeter_Grenze_strategisch  : 28|12@1+ (1.000000,0.000000) [0.000000|4093.000000] "Unit_None" ICAS1_KommunikationsServer
 SG_ MO_Powermeter_untere_E_Grenze  : 40|12@1+ (1.000000,0.000000) [0.000000|4093.000000] "Unit_None" Vector__XXX
 SG_ MO_Powermeter_obere_E_Grenze  : 52|12@1+ (1.000000,0.000000) [0.000000|4093.000000] "Unit_None" Vector__XXX

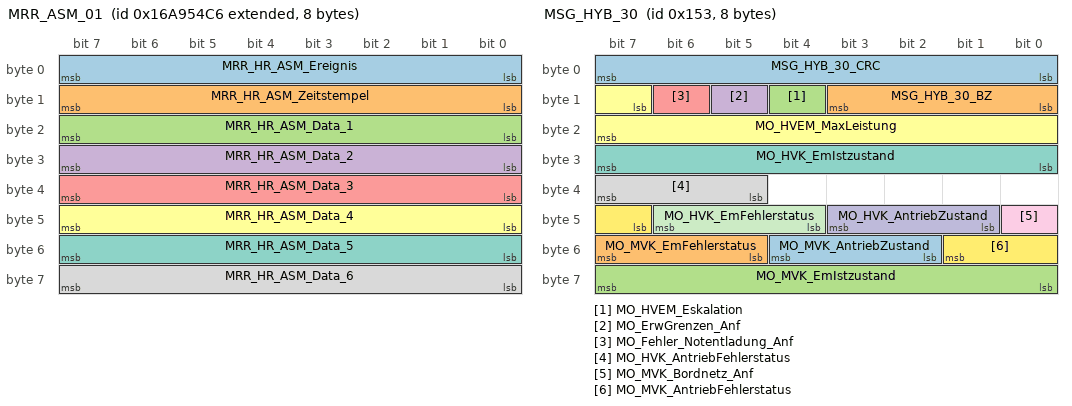
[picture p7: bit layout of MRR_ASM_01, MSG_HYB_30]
BO_ 2527679686 MRR_ASM_01: 8 ICAS1_Gateway
 SG_ MRR_HR_ASM_Ereignis  : 0|8@1+ (1.000000,0.000000) [1.000000|254.000000] "" Airbag
 SG_ MRR_HR_ASM_Zeitstempel  : 8|8@1+ (0.080000,0.000000) [0.000000|20.320000] "Unit_Secon" Airbag
 SG_ MRR_HR_ASM_Data_1  : 16|8@1+ (1.000000,0.000000) [0.000000|255.000000] "" Airbag
 SG_ MRR_HR_ASM_Data_2  : 24|8@1+ (1.000000,0.000000) [0.000000|255.000000] "" Airbag
 SG_ MRR_HR_ASM_Data_3  : 32|8@1+ (1.000000,0.000000) [0.000000|255.000000] "" Airbag
 SG_ MRR_HR_ASM_Data_4  : 40|8@1+ (1.000000,0.000000) [0.000000|255.000000] "" Airbag
 SG_ MRR_HR_ASM_Data_5  : 48|8@1+ (1.000000,0.000000) [0.000000|255.000000] "" Airbag
 SG_ MRR_HR_ASM_Data_6  : 56|8@1+ (1.000000,0.000000) [0.000000|255.000000] "" Airbag

BO_ 22 MSG3_WFS_Anfrage: 8 LE2
 SG_ WFS_MSG3_RND  : 0|32@1+ (1.000000,0.000000) [0.000000|4294967295.000000] "" ICAS1_Gateway
 SG_ WFS_MSG3_CRC  : 32|32@1+ (1.000000,0.000000) [0.000000|4294967295.000000] "" ICAS1_Gateway

BO_ 24 MSG4_WFS_Anfrage: 8 LE1
 SG_ WFS_MSG4_RND  : 0|32@1+ (1.000000,0.000000) [0.000000|4294967295.000000] "" ICAS1_Gateway
 SG_ WFS_MSG4_CRC  : 32|32@1+ (1.000000,0.000000) [0.000000|4294967295.000000] "" ICAS1_Gateway

BO_ 339 MSG_HYB_30: 8 Motor_BEV
 SG_ MSG_HYB_30_CRC  : 0|8@1+ (1.000000,0.000000) [0.000000|255.000000] "" Vector__XXX
 SG_ MSG_HYB_30_BZ  : 8|4@1+ (1.000000,0.000000) [0.000000|15.000000] "" Vector__XXX
 SG_ MO_HVEM_Eskalation  : 12|1@1+ (1.000000,0.000000) [0.000000|1.000000] "" ICAS1_Gateway
 SG_ MO_ErwGrenzen_Anf  : 13|1@1+ (1.000000,0.000000) [0.000000|1.000000] "" LE1 LE2
 SG_ MO_Fehler_Notentladung_Anf  : 14|1@1+ (1.000000,0.000000) [0.000000|1.000000] "" Vector__XXX
 SG_ MO_HVEM_MaxLeistung  : 15|9@1+ (50.000000,0.000000) [0.000000|25450.000000] "Unit_Watt" ICAS1_Gateway
 SG_ MO_HVK_EmIstzustand  : 24|8@1+ (1.000000,0.000000) [0.000000|255.000000] "" Vector__XXX
 SG_ MO_HVK_AntriebFehlerstatus  : 37|3@1+ (1.000000,0.000000) [0.000000|7.000000] "" Vector__XXX
 SG_ MO_MVK_Bordnetz_Anf  : 40|1@1+ (1.000000,0.000000) [0.000000|1.000000] "" Vector__XXX
 SG_ MO_HVK_AntriebZustand  : 41|3@1+ (1.000000,0.000000) [0.000000|7.000000] "" Vector__XXX
 SG_ MO_HVK_EmFehlerstatus  : 44|3@1+ (1.000000,0.000000) [0.000000|7.000000] "" Vector__XXX
 SG_ MO_MVK_AntriebFehlerstatus  : 47|3@1+ (1.000000,0.000000) [0.000000|7.000000] "" Vector__XXX
 SG_ MO_MVK_AntriebZustand  : 50|3@1+ (1.000000,0.000000) [0.000000|7.000000] "" Vector__XXX
 SG_ MO_MVK_EmFehlerstatus  : 53|3@1+ (1.000000,0.000000) [0.000000|7.000000] "" Vector__XXX
 SG_ MO_MVK_EmIstzustand  : 56|8@1+ (1.000000,0.000000) [0.000000|255.000000] "" Vector__XXX

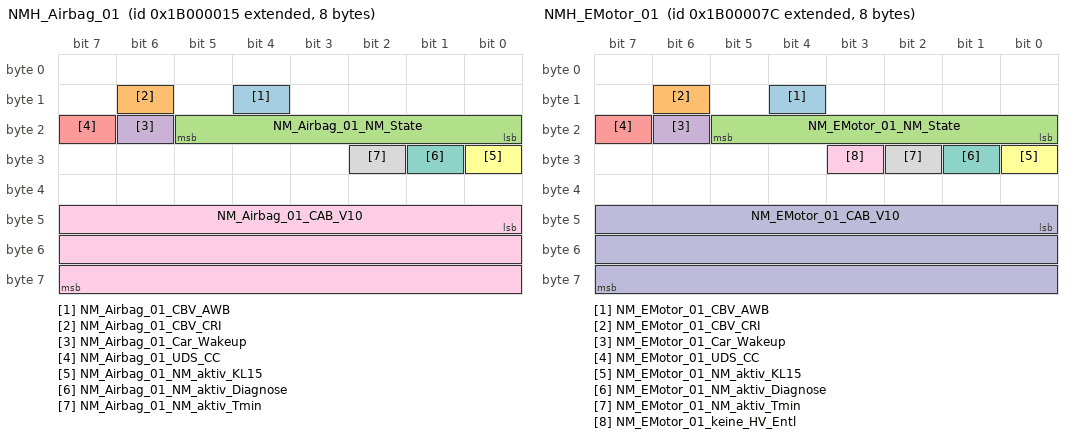
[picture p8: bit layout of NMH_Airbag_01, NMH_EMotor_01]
BO_ 2600468501 NMH_Airbag_01: 8 Airbag
 SG_ NM_Airbag_01_CBV_AWB  : 12|1@1+ (1.000000,0.000000) [0.000000|1.000000] "" ICAS1_Gateway
 SG_ NM_Airbag_01_CBV_CRI  : 14|1@1+ (1.000000,0.000000) [0.000000|1.000000] "" ICAS1_Gateway
 SG_ NM_Airbag_01_NM_State  : 16|6@1+ (1.000000,0.000000) [0.000000|63.000000] "" LE1 LE2 Motor_BEV Schaltbetaetigung
 SG_ NM_Airbag_01_Car_Wakeup  : 22|1@1+ (1.000000,0.000000) [0.000000|1.000000] "" ICAS1_Gateway
 SG_ NM_Airbag_01_UDS_CC  : 23|1@1+ (1.000000,0.000000) [0.000000|1.000000] "" Vector__XXX
 SG_ NM_Airbag_01_NM_aktiv_KL15  : 24|1@1+ (1.000000,0.000000) [0.000000|1.000000] "" Vector__XXX
 SG_ NM_Airbag_01_NM_aktiv_Diagnose  : 25|1@1+ (1.000000,0.000000) [0.000000|1.000000] "" Vector__XXX
 SG_ NM_Airbag_01_NM_aktiv_Tmin  : 26|1@1+ (1.000000,0.000000) [0.000000|1.000000] "" Vector__XXX
 SG_ NM_Airbag_01_CAB_V10  : 40|24@1+ (1.000000,0.000000) [0.000000|16777215.000000] "" ICAS1_Gateway

BO_ 2600468604 NMH_EMotor_01: 8 LE1
 SG_ NM_EMotor_01_CBV_AWB  : 12|1@1+ (1.000000,0.000000) [0.000000|1.000000] "" ICAS1_Gateway
 SG_ NM_EMotor_01_CBV_CRI  : 14|1@1+ (1.000000,0.000000) [0.000000|1.000000] "" ICAS1_Gateway
 SG_ NM_EMotor_01_NM_State  : 16|6@1+ (1.000000,0.000000) [0.000000|63.000000] "" Airbag LE2 Motor_BEV Schaltbetaetigung
 SG_ NM_EMotor_01_Car_Wakeup  : 22|1@1+ (1.000000,0.000000) [0.000000|1.000000] "" ICAS1_Gateway
 SG_ NM_EMotor_01_UDS_CC  : 23|1@1+ (1.000000,0.000000) [0.000000|1.000000] "" Vector__XXX
 SG_ NM_EMotor_01_NM_aktiv_KL15  : 24|1@1+ (1.000000,0.000000) [0.000000|1.000000] "" Vector__XXX
 SG_ NM_EMotor_01_NM_aktiv_Diagnose  : 25|1@1+ (1.000000,0.000000) [0.000000|1.000000] "" Vector__XXX
 SG_ NM_EMotor_01_NM_aktiv_Tmin  : 26|1@1+ (1.000000,0.000000) [0.000000|1.000000] "" Vector__XXX
 SG_ NM_EMotor_01_keine_HV_Entl  : 27|1@1+ (1.000000,0.000000) [0.000000|1.000000] "" Vector__XXX
 SG_ NM_EMotor_01_CAB_V10  : 40|24@1+ (1.000000,0.000000) [0.000000|16777215.000000] "" ICAS1_Gateway

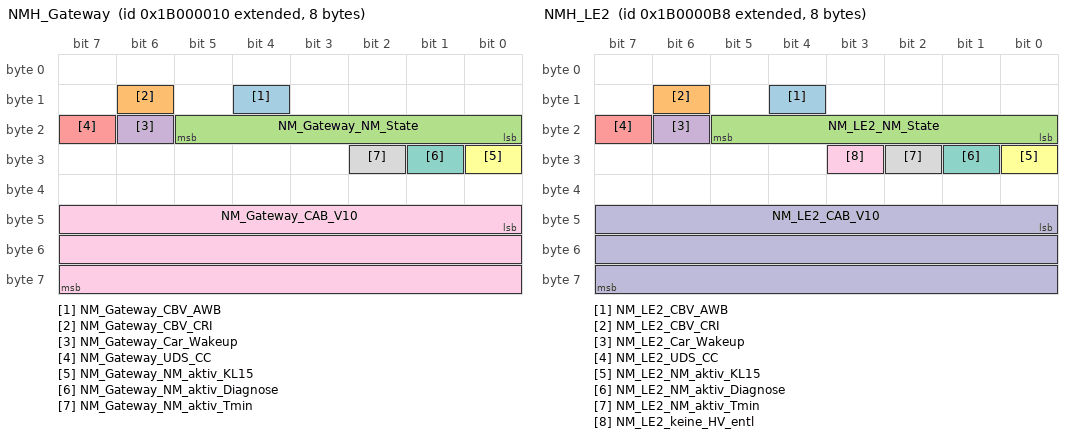
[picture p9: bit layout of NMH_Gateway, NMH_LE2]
BO_ 2600468496 NMH_Gateway: 8 ICAS1_Gateway
 SG_ NM_Gateway_CBV_AWB  : 12|1@1+ (1.000000,0.000000) [0.000000|1.000000] "" Vector__XXX
 SG_ NM_Gateway_CBV_CRI  : 14|1@1+ (1.000000,0.000000) [0.000000|1.000000] "" Vector__XXX
 SG_ NM_Gateway_NM_State  : 16|6@1+ (1.000000,0.000000) [0.000000|63.000000] "" Airbag LE1 LE2 Motor_BEV Schaltbetaetigung
 SG_ NM_Gateway_Car_Wakeup  : 22|1@1+ (1.000000,0.000000) [0.000000|1.000000] "" Vector__XXX
 SG_ NM_Gateway_UDS_CC  : 23|1@1+ (1.000000,0.000000) [0.000000|1.000000] "" Vector__XXX
 SG_ NM_Gateway_NM_aktiv_KL15  : 24|1@1+ (1.000000,0.000000) [0.000000|1.000000] "" Vector__XXX
 SG_ NM_Gateway_NM_aktiv_Diagnose  : 25|1@1+ (1.000000,0.000000) [0.000000|1.000000] "" Vector__XXX
 SG_ NM_Gateway_NM_aktiv_Tmin  : 26|1@1+ (1.000000,0.000000) [0.000000|1.000000] "" Vector__XXX
 SG_ NM_Gateway_CAB_V10  : 40|24@1+ (1.000000,0.000000) [0.000000|16777215.000000] "" Vector__XXX

BO_ 2600468664 NMH_LE2: 8 LE2
 SG_ NM_LE2_CBV_AWB  : 12|1@1+ (1.000000,0.000000) [0.000000|1.000000] "" ICAS1_Gateway
 SG_ NM_LE2_CBV_CRI  : 14|1@1+ (1.000000,0.000000) [0.000000|1.000000] "" ICAS1_Gateway
 SG_ NM_LE2_NM_State  : 16|6@1+ (1.000000,0.000000) [0.000000|63.000000] "" Airbag LE1 Motor_BEV Schaltbetaetigung
 SG_ NM_LE2_Car_Wakeup  : 22|1@1+ (1.000000,0.000000) [0.000000|1.000000] "" ICAS1_Gateway
 SG_ NM_LE2_UDS_CC  : 23|1@1+ (1.000000,0.000000) [0.000000|1.000000] "" Vector__XXX
 SG_ NM_LE2_NM_aktiv_KL15  : 24|1@1+ (1.000000,0.000000) [0.000000|1.000000] "" Vector__XXX
 SG_ NM_LE2_NM_aktiv_Diagnose  : 25|1@1+ (1.000000,0.000000) [0.000000|1.000000] "" Vector__XXX
 SG_ NM_LE2_NM_aktiv_Tmin  : 26|1@1+ (1.000000,0.000000) [0.000000|1.000000] "" Vector__XXX
 SG_ NM_LE2_keine_HV_entl  : 27|1@1+ (1.000000,0.000000) [0.000000|1.000000] "" Vector__XXX
 SG_ NM_LE2_CAB_V10  : 40|24@1+ (1.000000,0.000000) [0.000000|16777215.000000] "" ICAS1_Gateway

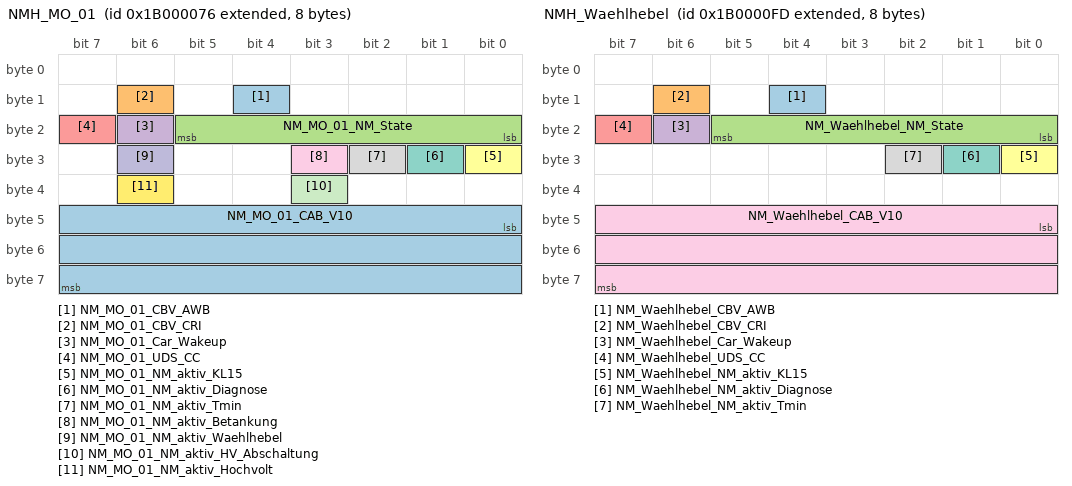
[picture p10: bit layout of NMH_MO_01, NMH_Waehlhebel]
BO_ 2600468598 NMH_MO_01: 8 Motor_BEV
 SG_ NM_MO_01_CBV_AWB  : 12|1@1+ (1.000000,0.000000) [0.000000|1.000000] "" ICAS1_Gateway
 SG_ NM_MO_01_CBV_CRI  : 14|1@1+ (1.000000,0.000000) [0.000000|1.000000] "" ICAS1_Gateway
 SG_ NM_MO_01_NM_State  : 16|6@1+ (1.000000,0.000000) [0.000000|63.000000] "" Airbag LE1 LE2 Schaltbetaetigung
 SG_ NM_MO_01_Car_Wakeup  : 22|1@1+ (1.000000,0.000000) [0.000000|1.000000] "" ICAS1_Gateway
 SG_ NM_MO_01_UDS_CC  : 23|1@1+ (1.000000,0.000000) [0.000000|1.000000] "" Vector__XXX
 SG_ NM_MO_01_NM_aktiv_KL15  : 24|1@1+ (1.000000,0.000000) [0.000000|1.000000] "" Vector__XXX
 SG_ NM_MO_01_NM_aktiv_Diagnose  : 25|1@1+ (1.000000,0.000000) [0.000000|1.000000] "" Vector__XXX
 SG_ NM_MO_01_NM_aktiv_Tmin  : 26|1@1+ (1.000000,0.000000) [0.000000|1.000000] "" Vector__XXX
 SG_ NM_MO_01_NM_aktiv_Betankung  : 27|1@1+ (1.000000,0.000000) [0.000000|1.000000] "" Vector__XXX
 SG_ NM_MO_01_NM_aktiv_Waehlhebel  : 30|1@1+ (1.000000,0.000000) [0.000000|1.000000] "" Vector__XXX
 SG_ NM_MO_01_NM_aktiv_HV_Abschaltung  : 35|1@1+ (1.000000,0.000000) [0.000000|1.000000] "" Vector__XXX
 SG_ NM_MO_01_NM_aktiv_Hochvolt  : 38|1@1+ (1.000000,0.000000) [0.000000|1.000000] "" Vector__XXX
 SG_ NM_MO_01_CAB_V10  : 40|24@1+ (1.000000,0.000000) [0.000000|16777215.000000] "" ICAS1_Gateway

BO_ 2600468733 NMH_Waehlhebel: 8 Schaltbetaetigung
 SG_ NM_Waehlhebel_CBV_AWB  : 12|1@1+ (1.000000,0.000000) [0.000000|1.000000] "" ICAS1_Gateway
 SG_ NM_Waehlhebel_CBV_CRI  : 14|1@1+ (1.000000,0.000000) [0.000000|1.000000] "" ICAS1_Gateway
 SG_ NM_Waehlhebel_NM_State  : 16|6@1+ (1.000000,0.000000) [0.000000|63.000000] "" Airbag LE1 LE2 Motor_BEV
 SG_ NM_Waehlhebel_Car_Wakeup  : 22|1@1+ (1.000000,0.000000) [0.000000|1.000000] "" ICAS1_Gateway
 SG_ NM_Waehlhebel_UDS_CC  : 23|1@1+ (1.000000,0.000000) [0.000000|1.000000] "" Vector__XXX
 SG_ NM_Waehlhebel_NM_aktiv_KL15  : 24|1@1+ (1.000000,0.000000) [0.000000|1.000000] "" Vector__XXX
 SG_ NM_Waehlhebel_NM_aktiv_Diagnose  : 25|1@1+ (1.000000,0.000000) [0.000000|1.000000] "" Vector__XXX
 SG_ NM_Waehlhebel_NM_aktiv_Tmin  : 26|1@1+ (1.000000,0.000000) [0.000000|1.000000] "" Vector__XXX
 SG_ NM_Waehlhebel_CAB_V10  : 40|24@1+ (1.000000,0.000000) [0.000000|16777215.000000] "" ICAS1_Gateway

BO_ 2621440533 OBDC_Airbag_01_Req_FD: 64 ICAS1_Gateway
 SG_ OBDC_Airbag_01_Req_FD_Data  : 0|512@1+ (1.000000,0.000000) [0.000000|13407807929942597099574024998205846127479365820592393377723561443721764030073546976801874298166903427690031858186486050853753882811946569946433649006084096.000000] "" Airbag

BO_ 2621571605 OBDC_Airbag_01_Resp_FD: 64 Airbag
 SG_ OBDC_Airbag_01_Resp_FD_Data  : 0|512@1+ (1.000000,0.000000) [0.000000|13407807929942597099574024998205846127479365820592393377723561443721764030073546976801874298166903427690031858186486050853753882811946569946433649006084096.000000] "" ICAS1_Gateway

BO_ 2621440636 OBDC_EMotor_01_Req_FD: 64 ICAS1_Gateway
 SG_ OBDC_EMotor_01_Req_FD_Data  : 0|512@1+ (1.000000,0.000000) [0.000000|13407807929942597099574024998205846127479365820592393377723561443721764030073546976801874298166903427690031858186486050853753882811946569946433649006084096.000000] "" LE1

BO_ 2621571708 OBDC_EMotor_01_Resp_FD: 64 LE1
 SG_ OBDC_EMotor_01_Resp_FD_Data  : 0|512@1+ (1.000000,0.000000) [0.000000|13407807929942597099574024998205846127479365820592393377723561443721764030073546976801874298166903427690031858186486050853753882811946569946433649006084096.000000] "" ICAS1_Gateway

BO_ 2621440696 OBDC_EMotor_02_Req_FD: 64 ICAS1_Gateway
 SG_ OBDC_EMotor_02_Req_FD_Data  : 0|512@1+ (1.000000,0.000000) [0.000000|13407807929942597099574024998205846127479365820592393377723561443721764030073546976801874298166903427690031858186486050853753882811946569946433649006084096.000000] "" LE2

BO_ 2621571768 OBDC_EMotor_02_Resp_FD: 64 LE2
 SG_ OBDC_EMotor_02_Resp_FD_Data  : 0|512@1+ (1.000000,0.000000) [0.000000|13407807929942597099574024998205846127479365820592393377723561443721764030073546976801874298166903427690031858186486050853753882811946569946433649006084096.000000] "" ICAS1_Gateway

BO_ 2621506048 OBDC_Funktionaler_Req_All_FD: 64 ICAS1_Gateway
 SG_ OBDC_Funktion_Req_All_FD_Data  : 0|512@1+ (1.000000,0.000000) [0.000000|13407807929942597099574024998205846127479365820592393377723561443721764030073546976801874298166903427690031858186486050853753882811946569946433649006084096.000000] "" Airbag LE1 LE2 Motor_BEV

BO_ 2621440630 OBDC_MO_01_Req_FD: 64 ICAS1_Gateway
 SG_ OBDC_MO_01_Req_FD_Data  : 0|512@1+ (1.000000,0.000000) [0.000000|13407807929942597099574024998205846127479365820592393377723561443721764030073546976801874298166903427690031858186486050853753882811946569946433649006084096.000000] "" Motor_BEV

BO_ 2621571702 OBDC_MO_01_Resp_FD: 64 Motor_BEV
 SG_ OBDC_MO_01_Resp_FD_Data  : 0|512@1+ (1.000000,0.000000) [0.000000|13407807929942597099574024998205846127479365820592393377723561443721764030073546976801874298166903427690031858186486050853753882811946569946433649006084096.000000] "" ICAS1_Gateway

BO_ 2564502513 OBDx_allOBD_Req: 8 ICAS1_Gateway
 SG_ OBDx_allOBD_Req_Data  : 0|64@1+ (1.000000,0.000000) [0.000000|18446744073709551616.000000] "" LE1 LE2 Motor_BEV

BO_ 2564425457 OBDx_LE1_Req: 8 ICAS1_Gateway
 SG_ OBDx_LE1_Req_Data  : 0|64@1+ (1.000000,0.000000) [0.000000|18446744073709551616.000000] "" LE1

BO_ 2564485382 OBDx_LE1_Resp: 8 LE1
 SG_ OBDx_LE1_Resp_Data  : 0|64@1+ (1.000000,0.000000) [0.000000|18446744073709551616.000000] "" ICAS1_Gateway

BO_ 2564425713 OBDx_LE2_Req: 8 ICAS1_Gateway
 SG_ OBDx_LE2_Req_Data  : 0|64@1+ (1.000000,0.000000) [0.000000|18446744073709551616.000000] "" LE2

BO_ 2564485383 OBDx_LE2_Resp: 8 LE2
 SG_ OBDx_LE2_Resp_Data  : 0|64@1+ (1.000000,0.000000) [0.000000|18446744073709551616.000000] "" ICAS1_Gateway

BO_ 2564424177 OBDx_MO_01_Req: 8 ICAS1_Gateway
 SG_ OBDx_MO_01_Req_Data  : 0|64@1+ (1.000000,0.000000) [0.000000|18446744073709551616.000000] "" Motor_BEV

BO_ 2564485377 OBDx_MO_01_Resp: 8 Motor_BEV
 SG_ OBDx_MO_01_Resp_Data  : 0|64@1+ (1.000000,0.000000) [0.000000|18446744073709551616.000000] "" ICAS1_Gateway

BO_ 627 OCC_01: 24 ICAS1_Gateway
 SG_ OCC_01_CRC  : 0|8@1+ (1.000000,0.000000) [0.000000|255.000000] "" Vector__XXX
 SG_ OCC_01_BZ  : 8|4@1+ (1.000000,0.000000) [0.000000|15.000000] "" Vector__XXX
 SG_ OCC_Stecker_Status  : 12|2@1+ (1.000000,0.000000) [0.000000|3.000000] "" Vector__XXX
 SG_ OCC_Status_Spgfreiheit  : 14|2@1+ (1.000000,0.000000) [0.000000|3.000000] "" Motor_BEV
 SG_ OCC_DC_IstStrom  : 16|11@1+ (0.100000,0.000000) [0.000000|204.500000] "Unit_Amper" Vector__XXX
 SG_ OCC_CC_Latchstatus_DC_GBT  : 27|3@1+ (1.000000,0.000000) [0.000000|7.000000] "" Vector__XXX
 SG_ OCC_Status_EoHVL  : 30|2@1+ (1.000000,0.000000) [0.000000|3.000000] "" Motor_BEV
 SG_ OCC_I_istAC_Netz_L1  : 32|9@1+ (0.100000,0.000000) [0.000000|50.800000] "Unit_Amper" Vector__XXX
 SG_ OCC_PP_Latchstatus_A  : 41|3@1+ (1.000000,0.000000) [0.000000|7.000000] "" Vector__XXX
 SG_ OCC_PP_Latchstatus_B  : 44|3@1+ (1.000000,0.000000) [0.000000|7.000000] "" Vector__XXX
 SG_ OCC_I_istAC_Netz_L2  : 47|9@1+ (0.100000,0.000000) [0.000000|50.800000] "Unit_Amper" Vector__XXX
 SG_ OCC_I_istAC_Netz_L3  : 56|9@1+ (0.100000,0.000000) [0.000000|50.800000] "Unit_Amper" Vector__XXX
 SG_ OCC_IstModus  : 65|3@1+ (1.000000,0.000000) [0.000000|7.000000] "" Motor_BEV
 SG_ OCC_CP_Status_A  : 68|2@1+ (1.000000,0.000000) [0.000000|3.000000] "" Vector__XXX
 SG_ OCC_CP_Status_B  : 70|2@1+ (1.000000,0.000000) [0.000000|3.000000] "" Vector__XXX
 SG_ OCC_IstSpannung_HV  : 72|10@1+ (1.000000,0.000000) [0.000000|1021.000000] "Unit_Volt" Vector__XXX
 SG_ OCC_PP_Status_A  : 82|2@1+ (1.000000,0.000000) [0.000000|3.000000] "" Vector__XXX
 SG_ OCC_PP_Status_B  : 84|2@1+ (1.000000,0.000000) [0.000000|3.000000] "" Vector__XXX
 SG_ OCC_CC_Status_DC_GBT  : 86|2@1+ (1.000000,0.000000) [0.000000|3.000000] "" Vector__XXX
 SG_ OCC_CC_Fehlerstatus_DC_GBT  : 88|4@1+ (1.000000,0.000000) [0.000000|15.000000] "" Vector__XXX
 SG_ OCC_Temp_Sensor_Fehlerstatus_DC  : 92|4@1+ (1.000000,0.000000) [0.000000|15.000000] "" Vector__XXX
 SG_ OCC_Temp_Sensor_Fehlerstatus_AC  : 96|3@1+ (1.000000,0.000000) [0.000000|7.000000] "" Vector__XXX
 SG_ OCC_Temp_Sensor_Status  : 99|3@1+ (1.000000,0.000000) [0.000000|7.000000] "" Vector__XXX

BO_ 2463978709 OCC_02: 32 ICAS1_Gateway
 SG_ OCC_CP_Tastgrad_A  : 12|10@1+ (0.100000,0.000000) [0.000000|100.000000] "Unit_PerCent" Vector__XXX
 SG_ OCC_CP_Tastgrad_B  : 22|10@1+ (0.100000,0.000000) [0.000000|100.000000] "Unit_PerCent" Vector__XXX
 SG_ OCC_CP_Frequenz_A  : 32|8@1+ (1.000000,880.000000) [880.000000|1132.000000] "Unit_Hertz" Vector__XXX
 SG_ OCC_CP_Frequenz_B  : 40|8@1+ (1.000000,880.000000) [880.000000|1132.000000] "Unit_Hertz" Vector__XXX
 SG_ OCC_CP_Spannung_A  : 48|9@1+ (0.100000,-25.000000) [-25.000000|25.900000] "Unit_Volt" Vector__XXX
 SG_ OCC_CP_Spannung_B  : 57|9@1+ (0.100000,-25.000000) [-25.000000|25.900000] "Unit_Volt" Vector__XXX
 SG_ OCC_CP_Fehlerstatus_A  : 66|3@1+ (1.000000,0.000000) [0.000000|7.000000] "" Vector__XXX
 SG_ OCC_CP_Fehlerstatus_B  : 69|3@1+ (1.000000,0.000000) [0.000000|7.000000] "" Vector__XXX
 SG_ OCC_Temp_Ladedose_A_AC  : 72|8@1+ (1.000000,-40.000000) [-40.000000|213.000000] "Unit_DegreCelsi" Vector__XXX
 SG_ OCC_Temp_Ladedose_A_DC_minus  : 80|8@1+ (1.000000,-40.000000) [-40.000000|213.000000] "Unit_DegreCelsi" Vector__XXX
 SG_ OCC_Temp_Ladedose_A_DC_plus  : 88|8@1+ (1.000000,-40.000000) [-40.000000|213.000000] "Unit_DegreCelsi" Vector__XXX
 SG_ OCC_U_istAC_Netz_L1  : 96|9@1+ (1.000000,0.000000) [0.000000|509.000000] "Unit_Volt" Vector__XXX
 SG_ OCC_U_istAC_Netz_L2  : 105|9@1+ (1.000000,0.000000) [0.000000|509.000000] "Unit_Volt" Vector__XXX
 SG_ OCC_U_istAC_Netz_L3  : 114|9@1+ (1.000000,0.000000) [0.000000|508.000000] "Unit_Volt" Vector__XXX
 SG_ OCC_StatusVerEntriegelungAktor_A  : 123|3@1+ (1.000000,0.000000) [0.000000|7.000000] "" Vector__XXX
 SG_ OCC_SteckerEntriegelung_Verbot_A  : 126|2@1+ (1.000000,0.000000) [0.000000|3.000000] "" Vector__XXX
 SG_ OCC_StatusVerEntriegelungAktor_B  : 128|3@1+ (1.000000,0.000000) [0.000000|7.000000] "" Vector__XXX
 SG_ OCC_SteckerEntriegelung_Verbot_B  : 131|2@1+ (1.000000,0.000000) [0.000000|3.000000] "" Vector__XXX
 SG_ OCC_Verriegelung_Status_A  : 133|3@1+ (1.000000,0.000000) [0.000000|7.000000] "" Vector__XXX
 SG_ OCC_Verriegelung_Status_B  : 136|3@1+ (1.000000,0.000000) [0.000000|7.000000] "" Vector__XXX
 SG_ OCC_RtmWarnLadeKommunikation  : 139|3@1+ (1.000000,0.000000) [0.000000|7.000000] "" Vector__XXX
 SG_ OCC_Ist_Wirkungsgrad  : 145|7@1+ (1.000000,0.000000) [0.000000|100.000000] "Unit_PerCent" Vector__XXX
 SG_ OCC_PP_Max_Strom_A  : 152|4@1+ (1.000000,0.000000) [0.000000|15.000000] "" Vector__XXX
 SG_ OCC_PP_Max_Strom_B  : 156|4@1+ (1.000000,0.000000) [0.000000|15.000000] "" Vector__XXX
 SG_ OCC_DC_MaxStrom  : 160|11@1+ (0.100000,0.000000) [0.000000|204.500000] "Unit_Amper" Vector__XXX
 SG_ OCC_Derating_Temperatur  : 171|1@1+ (1.000000,0.000000) [0.000000|1.000000] "" Vector__XXX
 SG_ OCC_Fehlerzustand  : 172|1@1+ (1.000000,0.000000) [0.000000|1.000000] "" Vector__XXX
 SG_ OCC_Ladest_Entriegelungs_Verbot  : 173|3@1+ (1.000000,0.000000) [0.000000|7.000000] "" Vector__XXX
 SG_ OCC_Netzfrequenz_EVU  : 176|9@1+ (0.100000,40.000000) [40.000000|80.000000] "Unit_Hertz" Vector__XXX
 SG_ OCC_Warnzustand  : 185|1@1+ (1.000000,0.000000) [0.000000|1.000000] "" Vector__XXX
 SG_ OCC_Kuehltemperatur  : 192|8@1+ (1.000000,-40.000000) [-40.000000|213.000000] "Unit_DegreCelsi" Motor_BEV
 SG_ OCC_PP_Fehlerstatus_A  : 200|4@1+ (1.000000,0.000000) [0.000000|15.000000] "" Vector__XXX
 SG_ OCC_PP_Fehlerstatus_B  : 204|4@1+ (1.000000,0.000000) [0.000000|15.000000] "" Vector__XXX

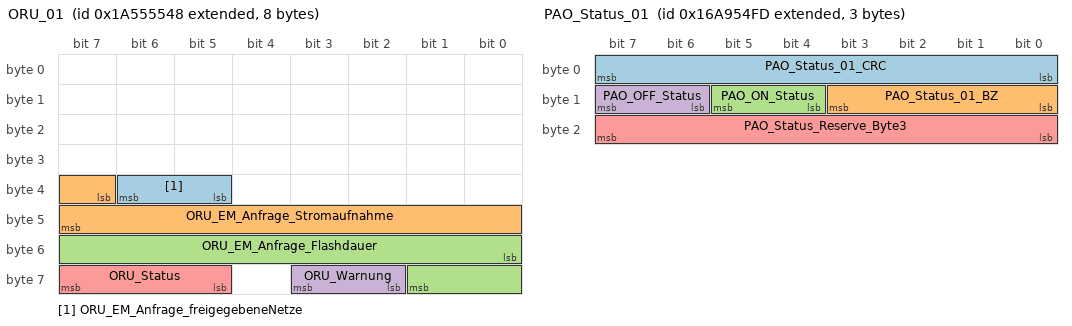
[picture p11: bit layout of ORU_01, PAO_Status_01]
BO_ 2589283656 ORU_01: 8 ICAS1_Gateway
 SG_ ORU_EM_Anfrage_freigegebeneNetze  : 37|2@1+ (1.000000,0.000000) [0.000000|3.000000] "" Vector__XXX
 SG_ ORU_EM_Anfrage_Stromaufnahme  : 39|9@1+ (0.100000,0.000000) [0.000000|51.100000] "Unit_Amper" Vector__XXX
 SG_ ORU_EM_Anfrage_Flashdauer  : 48|10@1+ (10.000000,0.000000) [0.000000|10230.000000] "Unit_Secon" Vector__XXX
 SG_ ORU_Warnung  : 58|2@1+ (1.000000,0.000000) [0.000000|3.000000] "" Vector__XXX
 SG_ ORU_Status  : 61|3@1+ (1.000000,0.000000) [0.000000|7.000000] "" Airbag LE1 LE2 Motor_BEV

BO_ 2527679741 PAO_Status_01: 3 ICAS1_Gateway
 SG_ PAO_Status_01_CRC  : 0|8@1+ (1.000000,0.000000) [0.000000|255.000000] "" Airbag
 SG_ PAO_Status_01_BZ  : 8|4@1+ (1.000000,0.000000) [0.000000|15.000000] "" Airbag
 SG_ PAO_ON_Status  : 12|2@1+ (1.000000,0.000000) [0.000000|3.000000] "" Airbag
 SG_ PAO_OFF_Status  : 14|2@1+ (1.000000,0.000000) [0.000000|3.000000] "" Airbag
 SG_ PAO_Status_Reserve_Byte3  : 16|8@1+ (1.000000,0.000000) [0.000000|255.000000] "" Vector__XXX

BO_ 518 Parken_01: 24 ICAS1_Gateway
 SG_ Parken_BKD_Anf  : 12|4@1+ (0.100000,0.000000) [0.000000|1.300000] "Unit_Secon" Vector__XXX
 SG_ Parken_Verz_Anf  : 16|7@1+ (0.100000,-12.600000) [-12.600000|-0.100000] "Unit_MeterPerSeconSquar" Vector__XXX
 SG_ Parken_Prefill_Anf  : 23|1@1+ (1.000000,0.000000) [0.000000|1.000000] "" Vector__XXX
 SG_ Parken_Warnruck_Anf  : 24|2@1+ (1.000000,0.000000) [0.000000|3.000000] "" Vector__XXX
 SG_ Parken_Verz_Anf_ASIL  : 26|2@1+ (1.000000,0.000000) [0.000000|3.000000] "" Vector__XXX
 SG_ Parken_Warnruckeln_Anf  : 28|2@1+ (1.000000,0.000000) [0.000000|3.000000] "" Vector__XXX
 SG_ Parken_beibehalten  : 30|2@1+ (1.000000,0.000000) [0.000000|3.000000] "" Vector__XXX
 SG_ Parken_Anforderung_HMS  : 32|3@1+ (1.000000,0.000000) [0.000000|7.000000] "" Vector__XXX
 SG_ Parken_Notstopp_Anf  : 40|2@1+ (1.000000,0.000000) [0.000000|3.000000] "" Vector__XXX
 SG_ Parken_Anhalteweg_Anf  : 42|10@1+ (0.010000,0.000000) [0.000000|10.210000] "Unit_Meter" Vector__XXX
 SG_ Parken_aktives_System  : 52|4@1+ (1.000000,0.000000) [0.000000|15.000000] "" Motor_BEV
 SG_ Parken_max_Beschleunigung  : 56|7@1+ (0.100000,-6.000000) [-5.900000|6.100000] "Unit_MeterPerSeconSquar" Motor_BEV
 SG_ Parken_Blinker_li_Anf  : 63|1@1+ (1.000000,0.000000) [0.000000|1.000000] "" Vector__XXX
 SG_ Parken_QFK_KruemmSoll  : 64|15@1+ (0.000007,0.000000) [0.000000|0.219539] "Unit_MeterInver" Vector__XXX
 SG_ Parken_QFK_KruemmSoll_VZ  : 79|1@1+ (1.000000,0.000000) [0.000000|1.000000] "" Vector__XXX
 SG_ Parken_QFK_Spuerb  : 80|8@1+ (0.400000,0.000000) [0.000000|100.000000] "Unit_PerCent" Vector__XXX
 SG_ Parken_QFK_AnfStat  : 88|4@1+ (1.000000,0.000000) [0.000000|15.000000] "" Vector__XXX
 SG_ Parken_QFK_Signal1  : 92|10@1+ (1.000000,0.000000) [0.000000|1023.000000] "" Vector__XXX
 SG_ Parken_QFK_Art1  : 102|3@1+ (1.000000,0.000000) [0.000000|7.000000] "" Vector__XXX
 SG_ Parken_QFK_Art2  : 105|3@1+ (1.000000,0.000000) [0.000000|7.000000] "" Vector__XXX
 SG_ Parken_QFK_Signal2  : 108|10@1+ (1.000000,0.000000) [0.000000|1023.000000] "" Vector__XXX
 SG_ Parken_Sollbeschleunigung  : 118|9@1+ (0.010000,-4.110000) [-4.100000|1.000000] "Unit_MeterPerSeconSquar" Motor_BEV
 SG_ Parken_Blinker_re_Anf  : 127|1@1+ (1.000000,0.000000) [0.000000|1.000000] "" Vector__XXX
 SG_ Parken_Status_IPA_TSK  : 128|4@1+ (1.000000,0.000000) [0.000000|15.000000] "" Motor_BEV
 SG_ Parken_erhoehtes_Moment  : 132|4@1+ (1.000000,0.000000) [0.000000|15.000000] "" Motor_BEV
 SG_ Parken_max_Geschwindigkeit  : 136|8@1+ (0.100000,0.000000) [0.100000|25.000000] "Unit_KiloMeterPerHour" Motor_BEV
 SG_ Parken_Soll_Anhalteweg_Anf  : 144|10@1+ (0.010000,0.000000) [0.000000|10.210000] "Unit_Meter" Vector__XXX
 SG_ Parken_Fahrstufenwunsch  : 154|3@1+ (1.000000,0.000000) [0.000000|7.000000] "" Motor_BEV
 SG_ IPA_TPA_Remote  : 157|2@1+ (1.000000,0.000000) [0.000000|3.000000] "" Vector__XXX
 SG_ IPA_TPA_Remote_Anf  : 159|1@1+ (1.000000,0.000000) [0.000000|1.000000] "" Vector__XXX
 SG_ IPA_TPA_Fehler  : 160|4@1+ (1.000000,0.000000) [0.000000|15.000000] "" Vector__XXX
 SG_ IPA_TPA_Abbruch  : 164|4@1+ (1.000000,0.000000) [0.000000|15.000000] "" Vector__XXX
 SG_ IPA_TPA_Status  : 168|4@1+ (1.000000,0.000000) [0.000000|15.000000] "" Vector__XXX

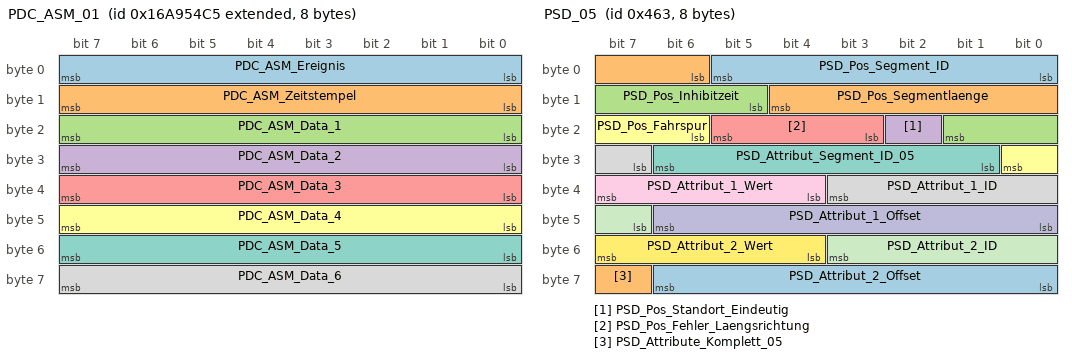
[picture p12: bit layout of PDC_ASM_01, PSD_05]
BO_ 2527679685 PDC_ASM_01: 8 ICAS1_Gateway
 SG_ PDC_ASM_Ereignis  : 0|8@1+ (1.000000,0.000000) [1.000000|254.000000] "" Airbag
 SG_ PDC_ASM_Zeitstempel  : 8|8@1+ (0.080000,0.000000) [0.000000|20.320000] "Unit_Secon" Airbag
 SG_ PDC_ASM_Data_1  : 16|8@1+ (1.000000,0.000000) [0.000000|255.000000] "" Airbag
 SG_ PDC_ASM_Data_2  : 24|8@1+ (1.000000,0.000000) [0.000000|255.000000] "" Airbag
 SG_ PDC_ASM_Data_3  : 32|8@1+ (1.000000,0.000000) [0.000000|255.000000] "" Airbag
 SG_ PDC_ASM_Data_4  : 40|8@1+ (1.000000,0.000000) [0.000000|255.000000] "" Airbag
 SG_ PDC_ASM_Data_5  : 48|8@1+ (1.000000,0.000000) [0.000000|255.000000] "" Airbag
 SG_ PDC_ASM_Data_6  : 56|8@1+ (1.000000,0.000000) [0.000000|255.000000] "" Airbag

BO_ 319 PreCrash_02: 8 Airbag
 SG_ PreCrash_Charisma_FahrPr  : 12|4@1+ (1.000000,0.000000) [0.000000|15.000000] "" ICAS1_Gateway
 SG_ PreCrash_Charisma_Status  : 16|2@1+ (1.000000,0.000000) [0.000000|3.000000] "" ICAS1_Gateway
 SG_ PreCrash_Schiebedach_schliessen  : 18|1@1+ (1.000000,0.000000) [0.000000|1.000000] "" ICAS1_Gateway
 SG_ PreCrash_Fenster_schliessen  : 19|1@1+ (1.000000,0.000000) [0.000000|1.000000] "" ICAS1_Gateway
 SG_ PreCrash_Blinken  : 20|3@1+ (1.000000,0.000000) [0.000000|7.000000] "" ICAS1_Gateway
 SG_ SC_PreSense_FCWP  : 23|1@1+ (1.000000,0.000000) [0.000000|1.000000] "" ICAS1_Gateway
 SG_ PreCrash_Tueren_Verriegeln  : 24|1@1+ (1.000000,0.000000) [0.000000|1.000000] "" ICAS1_Gateway
 SG_ PreCrash_FS_Laengsverstellung  : 25|1@1+ (1.000000,0.000000) [0.000000|1.000000] "" ICAS1_Gateway
 SG_ PreCrash_Anforderung_AFR  : 26|3@1+ (1.000000,0.000000) [0.000000|7.000000] "" ICAS1_Gateway
 SG_ SC_PreCrash_LED  : 29|2@1+ (1.000000,0.000000) [0.000000|3.000000] "" ICAS1_Gateway
 SG_ PreCrash_FS_Pneumatik_ansteuern  : 31|1@1+ (1.000000,0.000000) [0.000000|1.000000] "" ICAS1_Gateway
 SG_ PreCrash_BFS_Pneumatik_ansteuern  : 32|1@1+ (1.000000,0.000000) [0.000000|1.000000] "" ICAS1_Gateway
 SG_ PreCrash_Fo_Pneumatik_ansteuern  : 33|1@1+ (1.000000,0.000000) [0.000000|1.000000] "" ICAS1_Gateway
 SG_ PreCrash_FS_Sitzlehne_verfahren  : 34|3@1+ (1.000000,0.000000) [0.000000|7.000000] "" ICAS1_Gateway
 SG_ PreCrash_BFS_Sitzlehne_verfahren  : 37|3@1+ (1.000000,0.000000) [0.000000|7.000000] "" ICAS1_Gateway
 SG_ PreCrash_Fo_Sitzlehne_verfahren  : 40|3@1+ (1.000000,0.000000) [0.000000|7.000000] "" ICAS1_Gateway
 SG_ PreCrash_FS_KSV_verfahren  : 43|4@1+ (1.000000,0.000000) [0.000000|15.000000] "" ICAS1_Gateway
 SG_ PreCrash_BFS_KSV_verfahren  : 47|4@1+ (1.000000,0.000000) [0.000000|15.000000] "" ICAS1_Gateway
 SG_ PreCrash_Fo_KSV_verfahren  : 51|4@1+ (1.000000,0.000000) [0.000000|15.000000] "" ICAS1_Gateway
 SG_ PreCrash_BFS_Laengsverstellung  : 55|1@1+ (1.000000,0.000000) [0.000000|1.000000] "" ICAS1_Gateway
 SG_ SC_PreCrash_Warnung  : 56|4@1+ (1.000000,0.000000) [0.000000|15.000000] "" ICAS1_Gateway ICAS1_KommunikationsServer
 SG_ SC_PreCrash_Texte  : 60|4@1+ (1.000000,0.000000) [0.000000|15.000000] "" ICAS1_Gateway ICAS1_KommunikationsServer

BO_ 1122 PSD_04: 8 ICAS1_Gateway
 SG_ PSD_Segment_ID  : 0|6@1+ (1.000000,0.000000) [2.000000|63.000000] "" Motor_BEV
 SG_ PSD_Vorgaenger_Segment_ID  : 6|6@1+ (1.000000,0.000000) [2.000000|63.000000] "" Motor_BEV
 SG_ PSD_Segmentlaenge  : 12|7@1+ (2.000000,0.000000) [0.000000|254.000000] "Unit_Meter" Motor_BEV
 SG_ PSD_Strassenkategorie  : 19|3@1+ (1.000000,0.000000) [0.000000|7.000000] "" Motor_BEV
 SG_ PSD_Endkruemmung  : 22|8@1+ (1.000000,0.000000) [0.000000|254.000000] "Unit_None" Motor_BEV
 SG_ PSD_Endkruemmung_Vorz  : 30|1@1+ (1.000000,0.000000) [0.000000|1.000000] "" Motor_BEV
 SG_ PSD_Idenditaets_ID  : 31|6@1+ (1.000000,0.000000) [2.000000|63.000000] "" Vector__XXX
 SG_ PSD_ADAS_Qualitaet  : 37|1@1+ (1.000000,0.000000) [0.000000|1.000000] "" Motor_BEV
 SG_ PSD_wahrscheinlichster_Pfad  : 38|1@1+ (1.000000,0.000000) [0.000000|1.000000] "" Motor_BEV
 SG_ PSD_Geradester_Pfad  : 39|1@1+ (1.000000,0.000000) [0.000000|1.000000] "" Motor_BEV
 SG_ PSD_Fahrspuren_Anzahl  : 40|3@1+ (1.000000,0.000000) [0.000000|7.000000] "" Motor_BEV
 SG_ PSD_Bebauung  : 43|1@1+ (1.000000,0.000000) [0.000000|1.000000] "" Motor_BEV
 SG_ PSD_Segment_Komplett  : 44|1@1+ (1.000000,0.000000) [0.000000|1.000000] "" Motor_BEV
 SG_ PSD_Rampe  : 45|2@1+ (1.000000,0.000000) [0.000000|3.000000] "" Motor_BEV
 SG_ PSD_Anfangskruemmung  : 47|8@1+ (1.000000,0.000000) [0.000000|254.000000] "" Motor_BEV
 SG_ PSD_Anfangskruemmung_Vorz  : 55|1@1+ (1.000000,0.000000) [0.000000|1.000000] "" Motor_BEV
 SG_ PSD_Abzweigerichtung  : 56|1@1+ (1.000000,0.000000) [0.000000|1.000000] "" Motor_BEV
 SG_ PSD_Abzweigewinkel  : 57|7@1+ (1.417323,0.000000) [0.000000|180.000021] "" Motor_BEV

BO_ 1123 PSD_05: 8 ICAS1_Gateway
 SG_ PSD_Pos_Segment_ID  : 0|6@1+ (1.000000,0.000000) [2.000000|63.000000] "" Motor_BEV
 SG_ PSD_Pos_Segmentlaenge  : 6|7@1+ (2.000000,0.000000) [0.000000|254.000000] "Unit_Meter" Motor_BEV
 SG_ PSD_Pos_Inhibitzeit  : 13|5@1+ (10.000000,0.000000) [0.000000|310.000000] "Unit_MilliSecon" Motor_BEV
 SG_ PSD_Pos_Standort_Eindeutig  : 18|1@1+ (1.000000,0.000000) [0.000000|1.000000] "" Motor_BEV
 SG_ PSD_Pos_Fehler_Laengsrichtung  : 19|3@1+ (1.000000,0.000000) [0.000000|7.000000] "" Motor_BEV
 SG_ PSD_Pos_Fahrspur  : 22|3@1+ (1.000000,0.000000) [0.000000|7.000000] "" Motor_BEV
 SG_ PSD_Attribut_Segment_ID_05  : 25|6@1+ (1.000000,0.000000) [2.000000|63.000000] "" Motor_BEV
 SG_ PSD_Attribut_1_ID  : 31|5@1+ (1.000000,0.000000) [1.000000|31.000000] "" Motor_BEV
 SG_ PSD_Attribut_1_Wert  : 36|4@1+ (1.000000,0.000000) [0.000000|15.000000] "" Motor_BEV
 SG_ PSD_Attribut_1_Offset  : 40|7@1+ (2.000000,0.000000) [0.000000|254.000000] "Unit_Meter" Motor_BEV
 SG_ PSD_Attribut_2_ID  : 47|5@1+ (1.000000,0.000000) [1.000000|31.000000] "" Motor_BEV
 SG_ PSD_Attribut_2_Wert  : 52|4@1+ (1.000000,0.000000) [0.000000|15.000000] "" Motor_BEV
 SG_ PSD_Attribut_2_Offset  : 56|7@1+ (2.000000,0.000000) [0.000000|254.000000] "Unit_Meter" Motor_BEV
 SG_ PSD_Attribute_Komplett_05  : 63|1@1+ (1.000000,0.000000) [0.000000|1.000000] "" Motor_BEV

BO_ 1124 PSD_06: 8 ICAS1_Gateway
 SG_ PSD_06_Mux M : 0|3@1+ (1.000000,0.000000) [0.000000|7.000000] "" Motor_BEV
 SG_ PSD_Sys_Segment_ID m0 : 3|6@1+ (1.000000,0.000000) [2.000000|63.000000] "" Motor_BEV
 SG_ PSD_Attribut_Segment_ID m1 : 3|6@1+ (1.000000,0.000000) [2.000000|63.000000] "" Motor_BEV
 SG_ PSD_Ges_Segment_ID m2 : 3|6@1+ (1.000000,0.000000) [2.000000|63.000000] "" Motor_BEV
 SG_ PSD_Baum_Laenge_VZ m3 : 3|1@1+ (1.000000,0.000000) [0.000000|1.000000] "" Motor_BEV
 SG_ PSD_Steigung_1_Segment_ID m4 : 3|6@1+ (1.000000,0.000000) [2.000000|63.000000] "" Motor_BEV
 SG_ PSD_Baum_Laenge m3 : 4|25@1+ (0.000010,0.000000) [0.000000|180.000000] "Unit_DegreOfArc" Motor_BEV
 SG_ PSD_Sys_Laendercode m0 : 9|8@1+ (1.000000,0.000000) [0.000000|255.000000] "" Motor_BEV
 SG_ PSD_Attribut_3_ID m1 : 9|5@1+ (1.000000,0.000000) [1.000000|31.000000] "" Motor_BEV
 SG_ PSD_Ges_Offset m2 : 9|7@1+ (2.000000,0.000000) [0.000000|254.000000] "Unit_Meter" Motor_BEV
 SG_ PSD_Steigung_1_A_Steigung m4 : 9|7@1+ (0.120000,0.000000) [0.000000|15.000000] "Unit_PerCent" Motor_BEV
 SG_ PSD_Attribut_3_Offset m1 : 14|7@1+ (2.000000,0.000000) [0.000000|254.000000] "Unit_Meter" Motor_BEV
 SG_ PSD_Ges_Geschwindigkeit m2 : 16|5@1+ (1.000000,0.000000) [0.000000|31.000000] "" Motor_BEV
 SG_ PSD_Steigung_1_A_Vorz m4 : 16|1@1+ (1.000000,0.000000) [0.000000|1.000000] "" Motor_BEV
 SG_ PSD_Sys_Geschwindigkeit_Einheit m0 : 17|1@1+ (1.000000,0.000000) [0.000000|1.000000] "" Motor_BEV
 SG_ PSD_Steigung_1_A_Offset m4 : 17|7@1+ (2.000000,0.000000) [0.000000|254.000000] "Unit_Meter" Motor_BEV
 SG_ PSD_Sys_Verkehrsrichtung m0 : 18|1@1+ (1.000000,0.000000) [0.000000|1.000000] "" Motor_BEV
 SG_ PSD_Sys_Geometrieguete m0 : 19|2@1+ (1.000000,0.000000) [0.000000|3.000000] "" Motor_BEV
 SG_ PSD_Sys_Mapmatchingguete m0 : 21|2@1+ (1.000000,0.000000) [0.000000|3.000000] "" Motor_BEV
 SG_ PSD_Attribut_3_Wert m1 : 21|4@1+ (1.000000,0.000000) [0.000000|15.000000] "" Motor_BEV
 SG_ PSD_Ges_Typ m2 : 21|2@1+ (1.000000,0.000000) [0.000000|3.000000] "" Motor_BEV
 SG_ PSD_Sys_Alter_Karte m0 : 23|3@1+ (1.000000,0.000000) [0.000000|7.000000] "" Motor_BEV
 SG_ PSD_Ges_Spur_Geschw_Begrenzung m2 : 23|6@1+ (1.000000,0.000000) [0.000000|63.000000] "" Motor_BEV
 SG_ PSD_Steigung_1_B_Steigung m4 : 24|7@1+ (0.120000,0.000000) [0.000000|15.000000] "Unit_PerCent" Motor_BEV
 SG_ PSD_Attribut_4_ID m1 : 25|5@1+ (1.000000,0.000000) [1.000000|31.000000] "" Motor_BEV
 SG_ PSD_Sys_Zielfuehrung m0 : 26|1@1+ (1.000000,0.000000) [0.000000|1.000000] "" Motor_BEV
 SG_ PSD_Sys_US_State m0 : 27|6@1+ (1.000000,0.000000) [0.000000|63.000000] "" Motor_BEV
 SG_ PSD_Ges_Geschwindigkeit_Gespann m2 : 29|2@1+ (1.000000,0.000000) [0.000000|3.000000] "" Motor_BEV
 SG_ PSD_Baum_Breite_VZ m3 : 29|1@1+ (1.000000,0.000000) [0.000000|1.000000] "" Motor_BEV
 SG_ PSD_Attribut_4_Wert m1 : 30|4@1+ (1.000000,0.000000) [0.000000|15.000000] "" Motor_BEV
 SG_ PSD_Baum_Breite m3 : 30|24@1+ (0.000010,0.000000) [0.000000|90.000000] "Unit_DegreOfArc" Motor_BEV
 SG_ PSD_Ges_Geschwindigkeit_Witter m2 : 31|2@1+ (1.000000,0.000000) [0.000000|3.000000] "" Motor_BEV
 SG_ PSD_Steigung_1_B_Vorz m4 : 31|1@1+ (1.000000,0.000000) [0.000000|1.000000] "" Motor_BEV
 SG_ PSD_Steigung_1_B_Offset m4 : 32|7@1+ (2.000000,0.000000) [0.000000|254.000000] "Unit_Meter" Motor_BEV
 SG_ PSD_Sys_Quali_Geometrien m0 : 33|3@1+ (1.000000,0.000000) [0.000000|7.000000] "Unit_None" Vector__XXX
 SG_ PSD_Ges_Geschwindigkeit_Tag_Anf m2 : 33|3@1+ (1.000000,0.000000) [0.000000|7.000000] "" Motor_BEV
 SG_ PSD_Attribut_4_Offset m1 : 34|7@1+ (2.000000,0.000000) [0.000000|254.000000] "Unit_Meter" Motor_BEV
 SG_ PSD_Sys_Quali_Ortsinfo m0 : 36|2@1+ (1.000000,0.000000) [0.000000|3.000000] "Unit_None" Vector__XXX
 SG_ PSD_Ges_Geschwindigkeit_Tag_Ende m2 : 36|3@1+ (1.000000,0.000000) [0.000000|7.000000] "" Motor_BEV
 SG_ PSD_Sys_Quali_verfuegbar m0 : 38|1@1+ (1.000000,0.000000) [0.000000|1.000000] "" Vector__XXX
 SG_ PSD_Sys_Zielfuehrung_geaendert m0 : 39|1@1+ (1.000000,0.000000) [0.000000|1.000000] "" Motor_BEV
 SG_ PSD_Ges_Geschwindigkeit_Std_Anf m2 : 39|5@1+ (1.000000,0.000000) [0.000000|24.000000] "Unit_Hours" Motor_BEV
 SG_ PSD_Steigung_1_Attribute_kompl m4 : 39|1@1+ (1.000000,0.000000) [0.000000|1.000000] "" Motor_BEV
 SG_ PSD_Sys_Geometrieguete_erweitert m0 : 40|8@1+ (1.000000,0.000000) [0.000000|255.000000] "" Vector__XXX
 SG_ PSD_Steigung_2_Segment_ID m4 : 40|6@1+ (1.000000,0.000000) [2.000000|63.000000] "" Motor_BEV
 SG_ PSD_Attribut_5_ID m1 : 41|5@1+ (1.000000,0.000000) [1.000000|31.000000] "" Motor_BEV
 SG_ PSD_Ges_Geschwindigkeit_Std_Ende m2 : 44|5@1+ (1.000000,0.000000) [0.000000|24.000000] "Unit_Hours" Motor_BEV
 SG_ PSD_Attribut_5_Offset m1 : 46|7@1+ (2.000000,0.000000) [0.000000|254.000000] "Unit_Meter" Motor_BEV
 SG_ PSD_Steigung_2_Steigung m4 : 46|7@1+ (0.120000,0.000000) [0.000000|15.000000] "Unit_PerCent" Motor_BEV
 SG_ PSD_Sys_Quali_sonstige_Attribute m0 : 48|3@1+ (1.000000,0.000000) [0.000000|7.000000] "Unit_None" Vector__XXX
 SG_ PSD_Ges_Ueberholverbot m2 : 49|2@1+ (1.000000,0.000000) [0.000000|3.000000] "" Vector__XXX
 SG_ PSD_Sys_Quali_Steigungen m0 : 51|3@1+ (1.000000,0.000000) [0.000000|7.000000] "" Vector__XXX
 SG_ PSD_Ges_Wechselverkehrszeichen m2 : 51|3@1+ (1.000000,0.000000) [0.000000|7.000000] "" Vector__XXX
 SG_ PSD_Attribut_5_Wert m1 : 53|4@1+ (1.000000,0.000000) [0.000000|15.000000] "" Motor_BEV
 SG_ PSD_Steigung_2_Vorz m4 : 53|1@1+ (1.000000,0.000000) [0.000000|1.000000] "" Motor_BEV
 SG_ PSD_Sys_Quali_Strassenkennz m0 : 54|3@1+ (1.000000,0.000000) [0.000000|7.000000] "Unit_None" Vector__XXX
 SG_ PSD_Wechselverkehrszeichen_Typ m2 : 54|2@1+ (1.000000,0.000000) [0.000000|3.000000] "" Vector__XXX
 SG_ PSD_Baum_Ausrichtung m3 : 54|10@1+ (0.351562,0.000000) [0.000000|359.648438] "Unit_DegreOfArc" Vector__XXX
 SG_ PSD_Steigung_2_Offset m4 : 54|7@1+ (2.000000,0.000000) [0.000000|254.000000] "Unit_Meter" Motor_BEV
 SG_ PSD_Ges_Gesetzlich_Kategorie m2 : 56|3@1+ (1.000000,0.000000) [0.000000|7.000000] "" Motor_BEV
 SG_ PSD_Sys_Quali_Tempolimits m0 : 57|3@1+ (1.000000,0.000000) [0.000000|7.000000] "Unit_None" Vector__XXX
 SG_ PSD_Attribute_Komplett_06 m1 : 57|1@1+ (1.000000,0.000000) [0.000000|1.000000] "" Motor_BEV
 SG_ PSD_Ges_Gesetzlich_Zusatz m2 : 59|2@1+ (1.000000,0.000000) [0.000000|3.000000] "" Motor_BEV
 SG_ PSD_Sys_Quali_Vorfahrtsregelung m0 : 60|3@1+ (1.000000,0.000000) [0.000000|7.000000] "Unit_None" Vector__XXX
 SG_ PSD_Ges_Verkehrszeichen_Quelle m2 : 61|2@1+ (1.000000,0.000000) [0.000000|3.000000] "" Motor_BEV
 SG_ PSD_Steigung_2_Attribute_kompl m4 : 61|1@1+ (1.000000,0.000000) [0.000000|1.000000] "" Motor_BEV
 SG_ PSD_Ges_Attribute_Komplett m2 : 63|1@1+ (1.000000,0.000000) [0.000000|1.000000] "" Motor_BEV

BO_ 591 RDR1_Objekte_02: 64 ICAS1_Gateway
 SG_ RDR1_relevanter_Fehler  : 12|1@1+ (1.000000,0.000000) [0.000000|1.000000] "" Motor_BEV
 SG_ RDR1_Blindheit_erkannt  : 13|1@1+ (1.000000,0.000000) [0.000000|1.000000] "" Motor_BEV
 SG_ RDR1_relev_Nichtverfuegbarkeit  : 14|1@1+ (1.000000,0.000000) [0.000000|1.000000] "" Motor_BEV
 SG_ RDR1_Obj_01_Nummer  : 16|6@1+ (1.000000,0.000000) [0.000000|63.000000] "" Vector__XXX
 SG_ RDR1_Obj_02_Nummer  : 22|6@1+ (1.000000,0.000000) [0.000000|63.000000] "" Vector__XXX
 SG_ RDR1_Obj_03_Nummer  : 28|6@1+ (1.000000,0.000000) [0.000000|63.000000] "" Vector__XXX
 SG_ RDR1_Obj_04_Nummer  : 34|6@1+ (1.000000,0.000000) [0.000000|63.000000] "" Vector__XXX
 SG_ RDR1_Obj_05_Nummer  : 40|6@1+ (1.000000,0.000000) [0.000000|63.000000] "" Vector__XXX
 SG_ RDR1_Obj_06_Nummer  : 46|6@1+ (1.000000,0.000000) [0.000000|63.000000] "" Vector__XXX
 SG_ RDR1_Verkehrssinn  : 52|2@1+ (1.000000,0.000000) [0.000000|3.000000] "" Vector__XXX
 SG_ RDR1_Objekte_02_Datenalter  : 54|10@1+ (0.000977,0.000000) [0.000000|0.998047] "Unit_Secon" Vector__XXX
 SG_ RDR1_Obj_01_dx_v  : 64|12@1+ (0.062500,0.000000) [0.000000|255.937500] "Unit_Meter" Motor_BEV
 SG_ RDR1_Obj_01_dy_v  : 76|10@1+ (0.062500,-32.000000) [-32.000000|31.937500] "Unit_Meter" Motor_BEV
 SG_ RDR1_Obj_01_vx_v  : 86|10@1+ (0.250000,-128.000000) [-128.000000|127.750000] "Unit_MeterPerSecon" Motor_BEV
 SG_ RDR1_Obj_02_dx_v  : 96|12@1+ (0.062500,0.000000) [0.000000|255.937500] "Unit_Meter" Vector__XXX
 SG_ RDR1_Obj_02_dy_v  : 108|10@1+ (0.062500,-32.000000) [-32.000000|31.937500] "Unit_Meter" Vector__XXX
 SG_ RDR1_Obj_02_vx_v  : 118|10@1+ (0.250000,-128.000000) [-128.000000|127.750000] "Unit_MeterPerSecon" Vector__XXX
 SG_ RDR1_Obj_03_dx_v  : 128|12@1+ (0.062500,0.000000) [0.000000|255.937500] "Unit_Meter" Vector__XXX
 SG_ RDR1_Obj_03_dy_v  : 140|10@1+ (0.062500,-32.000000) [-32.000000|31.937500] "Unit_Meter" Vector__XXX
 SG_ RDR1_Obj_03_vx_v  : 150|10@1+ (0.250000,-128.000000) [-128.000000|127.750000] "Unit_MeterPerSecon" Vector__XXX
 SG_ RDR1_Obj_04_dx_v  : 160|12@1+ (0.062500,0.000000) [0.000000|255.937500] "Unit_Meter" Motor_BEV
 SG_ RDR1_Obj_04_dy_v  : 172|10@1+ (0.062500,-32.000000) [-32.000000|31.937500] "Unit_Meter" Vector__XXX
 SG_ RDR1_Obj_04_vx_v  : 182|10@1+ (0.250000,-128.000000) [-128.000000|127.750000] "Unit_MeterPerSecon" Motor_BEV
 SG_ RDR1_Obj_05_dx_v  : 192|12@1+ (0.062500,0.000000) [0.000000|255.937500] "Unit_Meter" Vector__XXX
 SG_ RDR1_Obj_05_dy_v  : 204|10@1+ (0.062500,-32.000000) [-32.000000|31.937500] "Unit_Meter" Vector__XXX
 SG_ RDR1_Obj_05_vx_v  : 214|10@1+ (0.250000,-128.000000) [-128.000000|127.750000] "Unit_MeterPerSecon" Vector__XXX
 SG_ RDR1_Obj_06_dx_v  : 224|12@1+ (0.062500,0.000000) [0.000000|255.937500] "Unit_Meter" Vector__XXX
 SG_ RDR1_Obj_06_dy_v  : 236|10@1+ (0.062500,-32.000000) [-32.000000|31.937500] "Unit_Meter" Vector__XXX
 SG_ RDR1_Obj_06_vx_v  : 246|10@1+ (0.250000,-128.000000) [-128.000000|127.750000] "Unit_MeterPerSecon" Vector__XXX
 SG_ RDR1_Obj_01_ax_v  : 256|8@1+ (0.125000,-16.000000) [-16.000000|15.750000] "Unit_MeterPerSeconSquar" Motor_BEV
 SG_ RDR1_Obj_01_ax_StdA  : 264|6@1+ (0.125000,0.000000) [0.000000|7.750000] "Unit_MeterPerSeconSquar" Motor_BEV
 SG_ RDR1_Obj_01_vx_StdA  : 270|7@1+ (0.031250,0.000000) [0.000000|3.937500] "Unit_MeterPerSecon" Motor_BEV
 SG_ RDR1_Obj_01_dx_StdA  : 277|7@1+ (0.050000,0.000000) [0.000000|6.300000] "Unit_Meter" Motor_BEV
 SG_ RDR1_Obj_01_dy_StdA  : 284|7@1+ (0.062500,0.000000) [0.000000|7.875000] "Unit_Meter" Motor_BEV

BO_ 2033 Request_Airbag_Deployment: 8 ICAS1_Gateway
 SG_ Request_Airbag_Deployment  : 0|64@1+ (1.000000,0.000000) [0.000000|18446744073709551616.000000] "" Airbag

BO_ 2041 Response_Airbag_Deployment: 8 Airbag
 SG_ Response_Airbag_Deployment  : 0|64@1+ (1.000000,0.000000) [0.000000|18446744073709551616.000000] "" ICAS1_Gateway

BO_ 980 SMLS_01: 8 ICAS1_Gateway
 SG_ SMLS_01_CRC  : 0|8@1+ (1.000000,0.000000) [0.000000|255.000000] "" Vector__XXX
 SG_ SMLS_01_BZ  : 8|4@1+ (1.000000,0.000000) [0.000000|15.000000] "" Vector__XXX
 SG_ BH_Blinker_li  : 12|1@1+ (1.000000,0.000000) [0.000000|1.000000] "" Motor_BEV
 SG_ BH_Blinker_re  : 13|1@1+ (1.000000,0.000000) [0.000000|1.000000] "" Motor_BEV
 SG_ BH_Lichthupe  : 14|1@1+ (1.000000,0.000000) [0.000000|1.000000] "" Vector__XXX
 SG_ BH_Fernlicht  : 15|1@1+ (1.000000,0.000000) [0.000000|1.000000] "" Vector__XXX
 SG_ WH_Tipwischen  : 16|1@1+ (1.000000,0.000000) [0.000000|1.000000] "" Vector__XXX
 SG_ WH_Intervall  : 17|1@1+ (1.000000,0.000000) [0.000000|1.000000] "" Vector__XXX
 SG_ WH_WischerStufe1  : 18|1@1+ (1.000000,0.000000) [0.000000|1.000000] "" Vector__XXX
 SG_ WH_WischerStufe2  : 19|1@1+ (1.000000,0.000000) [0.000000|1.000000] "" Vector__XXX
 SG_ WH_Frontwaschen  : 20|1@1+ (1.000000,0.000000) [0.000000|1.000000] "" Vector__XXX
 SG_ WH_Heckintervall  : 21|1@1+ (1.000000,0.000000) [0.000000|1.000000] "" Vector__XXX
 SG_ WH_Heckwaschen  : 22|1@1+ (1.000000,0.000000) [0.000000|1.000000] "" Vector__XXX
 SG_ WH_Intervallstufen  : 23|4@1+ (1.000000,0.000000) [0.000000|15.000000] "" Vector__XXX
 SG_ FAS_Taster  : 27|1@1+ (1.000000,0.000000) [0.000000|1.000000] "" Vector__XXX
 SG_ FAS_Taster_Fehler  : 28|1@1+ (1.000000,0.000000) [0.000000|1.000000] "" Vector__XXX
 SG_ SMLS_Hupe  : 29|1@1+ (1.000000,0.000000) [0.000000|1.000000] "" Vector__XXX
 SG_ LRH_on_off  : 30|2@1+ (1.000000,0.000000) [0.000000|3.000000] "" Vector__XXX
 SG_ LSS_Tastencode  : 32|8@1+ (1.000000,0.000000) [0.000000|255.000000] "" Vector__XXX
 SG_ LRH_aktiv  : 40|1@1+ (1.000000,0.000000) [0.000000|1.000000] "" Vector__XXX
 SG_ SMLS_P_verriegelt  : 41|2@1+ (1.000000,0.000000) [0.000000|3.000000] "" Vector__XXX
 SG_ SMLS_P_verriegelt_plausibel  : 43|1@1+ (1.000000,0.000000) [0.000000|1.000000] "" Vector__XXX
 SG_ WH_SRA  : 44|1@1+ (1.000000,0.000000) [0.000000|1.000000] "" Vector__XXX
 SG_ WH_Wischer_Fehler  : 45|1@1+ (1.000000,0.000000) [0.000000|1.000000] "" Vector__XXX
 SG_ BH_Blinker_Fehler  : 46|1@1+ (1.000000,0.000000) [0.000000|1.000000] "" Vector__XXX
 SG_ SMLS_PTT  : 47|1@1+ (1.000000,0.000000) [0.000000|1.000000] "" Vector__XXX
 SG_ WH_Tipwischen_lang  : 48|1@1+ (1.000000,0.000000) [0.000000|1.000000] "" Vector__XXX

BO_ 2464153718 SOK_FoD_MO_01_Req_Chal_01: 8 Motor_BEV
 SG_ SOK_FoD_MO_01_Req_Challenge  : 0|64@1+ (1.000000,0.000000) [0.000000|18446744073709551616.000000] "Unit_None" ICAS1_Gateway

BO_ 2464284790 SOK_FoD_MO_01_Resp_Chal_01: 8 ICAS1_Gateway
 SG_ SOK_FoD_MO_01_Resp_Challenge  : 0|64@1+ (1.000000,0.000000) [0.000000|18446744073709551616.000000] "Unit_None" Motor_BEV

BO_ 1413 Systeminfo_01: 8 ICAS1_Gateway
 SG_ SI_Sammel_SG_Fehler  : 0|6@1+ (1.000000,0.000000) [0.000000|60.000000] "" Vector__XXX
 SG_ SI_P_Mode_gueltig  : 6|1@1+ (1.000000,0.000000) [0.000000|1.000000] "" Vector__XXX
 SG_ SI_Diagnose_Aktiv  : 7|1@1+ (1.000000,0.000000) [0.000000|1.000000] "" Vector__XXX
 SG_ SI_QRS_Mode  : 8|1@1+ (1.000000,0.000000) [0.000000|1.000000] "" Airbag Motor_BEV
 SG_ SI_T_Mode  : 9|1@1+ (1.000000,0.000000) [0.000000|1.000000] "" Motor_BEV
 SG_ SI_NWDF  : 10|1@1+ (1.000000,0.000000) [0.000000|1.000000] "" Vector__XXX
 SG_ SI_NWDF_gueltig  : 11|1@1+ (1.000000,0.000000) [0.000000|1.000000] "" Vector__XXX
 SG_ SI_Sammelfehler  : 12|1@1+ (1.000000,0.000000) [0.000000|1.000000] "" Vector__XXX
 SG_ GW_KD_Fehler  : 13|1@1+ (1.000000,0.000000) [0.000000|1.000000] "" Vector__XXX
 SG_ SI_T_Schutz  : 14|1@1+ (1.000000,0.000000) [0.000000|1.000000] "" Motor_BEV
 SG_ SI_P_Mode  : 15|1@1+ (1.000000,0.000000) [0.000000|1.000000] "" Vector__XXX
 SG_ SI_BUS_01  : 16|1@1+ (1.000000,0.000000) [0.000000|1.000000] "" Vector__XXX
 SG_ SI_BUS_02  : 17|1@1+ (1.000000,0.000000) [0.000000|1.000000] "" Vector__XXX
 SG_ SI_BUS_03  : 18|1@1+ (1.000000,0.000000) [0.000000|1.000000] "" Vector__XXX
 SG_ SI_BUS_04  : 19|1@1+ (1.000000,0.000000) [0.000000|1.000000] "" Vector__XXX
 SG_ SI_BUS_05  : 20|1@1+ (1.000000,0.000000) [0.000000|1.000000] "" Vector__XXX
 SG_ SI_BUS_06  : 21|1@1+ (1.000000,0.000000) [0.000000|1.000000] "" Vector__XXX
 SG_ SI_BUS_07  : 22|1@1+ (1.000000,0.000000) [0.000000|1.000000] "" Vector__XXX
 SG_ SI_BUS_08  : 23|1@1+ (1.000000,0.000000) [0.000000|1.000000] "" Vector__XXX
 SG_ SI_BUS_09  : 24|1@1+ (1.000000,0.000000) [0.000000|1.000000] "" Vector__XXX
 SG_ SI_BUS_10  : 25|1@1+ (1.000000,0.000000) [0.000000|1.000000] "" Vector__XXX
 SG_ SI_BUS_11  : 26|1@1+ (1.000000,0.000000) [0.000000|1.000000] "" Vector__XXX
 SG_ SI_BUS_12  : 27|1@1+ (1.000000,0.000000) [0.000000|1.000000] "" Vector__XXX
 SG_ SI_BUS_13  : 28|1@1+ (1.000000,0.000000) [0.000000|1.000000] "" Vector__XXX
 SG_ SI_BUS_14  : 29|1@1+ (1.000000,0.000000) [0.000000|1.000000] "" Vector__XXX
 SG_ SI_BUS_15  : 30|1@1+ (1.000000,0.000000) [0.000000|1.000000] "" Vector__XXX
 SG_ SI_Bus_Identifikation  : 32|8@1+ (1.000000,0.000000) [0.000000|255.000000] "" Vector__XXX
 SG_ SI_CAB_V10  : 40|24@1+ (1.000000,0.000000) [0.000000|16777215.000000] "" Vector__XXX

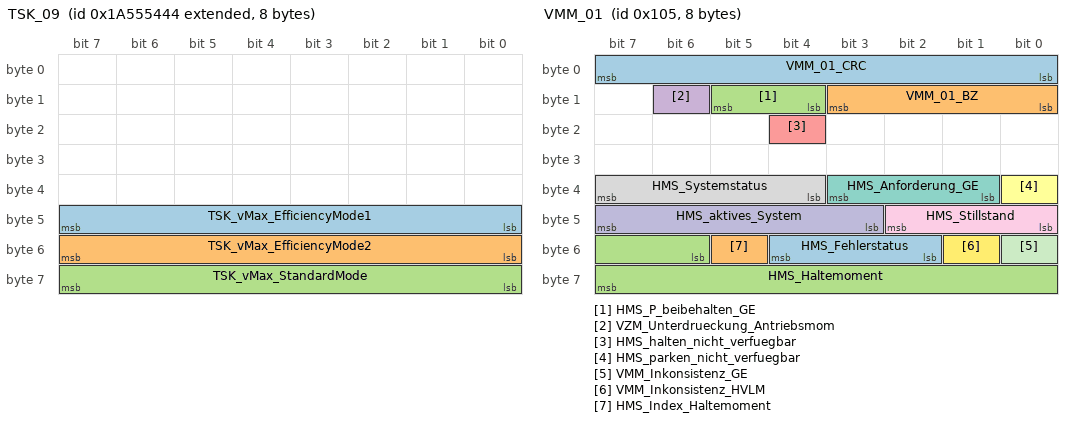
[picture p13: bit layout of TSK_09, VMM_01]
BO_ 2589283396 TSK_09: 8 Motor_BEV
 SG_ TSK_vMax_EfficiencyMode1  : 40|8@1+ (1.000000,0.000000) [0.000000|253.000000] "Unit_KiloMeterPerHour" ICAS1_Gateway
 SG_ TSK_vMax_EfficiencyMode2  : 48|8@1+ (1.000000,0.000000) [0.000000|253.000000] "Unit_KiloMeterPerHour" ICAS1_Gateway
 SG_ TSK_vMax_StandardMode  : 56|8@1+ (1.000000,0.000000) [0.000000|253.000000] "Unit_KiloMeterPerHour" ICAS1_Gateway

BO_ 1019 TSK_Ausrollkurve_01: 8 Motor_BEV
 SG_ TSK_Ausrollkurve_Schub_Reku_01 m0 : 0|7@1+ (2.000000,0.000000) [0.000000|252.000000] "Unit_KiloMeterPerHour" ICAS1_Gateway
 SG_ TSK_Ausrollkurve_Schub_Reku_05 m1 : 0|7@1+ (2.000000,0.000000) [0.000000|252.000000] "Unit_KiloMeterPerHour" ICAS1_Gateway
 SG_ TSK_Ausrollkurve_Schub_Reku_09 m2 : 0|7@1+ (2.000000,0.000000) [0.000000|252.000000] "Unit_KiloMeterPerHour" ICAS1_Gateway
 SG_ TSK_Ausrollkurve_Schub_Reku_13 m3 : 0|7@1+ (2.000000,0.000000) [0.000000|252.000000] "Unit_KiloMeterPerHour" ICAS1_Gateway
 SG_ TSK_Ausrollkurve_Schub_Reku_17 m4 : 0|7@1+ (2.000000,0.000000) [0.000000|252.000000] "Unit_KiloMeterPerHour" ICAS1_Gateway
 SG_ TSK_Ausrollkurve_Schub_Reku_02 m0 : 7|7@1+ (2.000000,0.000000) [0.000000|252.000000] "Unit_KiloMeterPerHour" ICAS1_Gateway
 SG_ TSK_Ausrollkurve_Schub_Reku_06 m1 : 7|7@1+ (2.000000,0.000000) [0.000000|252.000000] "Unit_KiloMeterPerHour" ICAS1_Gateway
 SG_ TSK_Ausrollkurve_Schub_Reku_10 m2 : 7|7@1+ (2.000000,0.000000) [0.000000|252.000000] "Unit_KiloMeterPerHour" ICAS1_Gateway
 SG_ TSK_Ausrollkurve_Schub_Reku_14 m3 : 7|7@1+ (2.000000,0.000000) [0.000000|252.000000] "Unit_KiloMeterPerHour" ICAS1_Gateway
 SG_ TSK_Ausrollkurve_Schub_Reku_18 m4 : 7|7@1+ (2.000000,0.000000) [0.000000|252.000000] "Unit_KiloMeterPerHour" ICAS1_Gateway
 SG_ TSK_Ausrollkurve_Schub_Reku_03 m0 : 14|7@1+ (2.000000,0.000000) [0.000000|252.000000] "Unit_KiloMeterPerHour" ICAS1_Gateway
 SG_ TSK_Ausrollkurve_Schub_Reku_07 m1 : 14|7@1+ (2.000000,0.000000) [0.000000|252.000000] "Unit_KiloMeterPerHour" ICAS1_Gateway
 SG_ TSK_Ausrollkurve_Schub_Reku_11 m2 : 14|7@1+ (2.000000,0.000000) [0.000000|252.000000] "Unit_KiloMeterPerHour" ICAS1_Gateway
 SG_ TSK_Ausrollkurve_Schub_Reku_15 m3 : 14|7@1+ (2.000000,0.000000) [0.000000|252.000000] "Unit_KiloMeterPerHour" ICAS1_Gateway
 SG_ TSK_Ausrollkurve_Schub_Reku_19 m4 : 14|7@1+ (2.000000,0.000000) [0.000000|252.000000] "Unit_KiloMeterPerHour" ICAS1_Gateway
 SG_ TSK_Ausrollkurve_Schub_Reku_04 m0 : 21|7@1+ (2.000000,0.000000) [0.000000|252.000000] "Unit_KiloMeterPerHour" ICAS1_Gateway
 SG_ TSK_Ausrollkurve_Schub_Reku_08 m1 : 21|7@1+ (2.000000,0.000000) [0.000000|252.000000] "Unit_KiloMeterPerHour" ICAS1_Gateway
 SG_ TSK_Ausrollkurve_Schub_Reku_12 m2 : 21|7@1+ (2.000000,0.000000) [0.000000|252.000000] "Unit_KiloMeterPerHour" ICAS1_Gateway
 SG_ TSK_Ausrollkurve_Schub_Reku_16 m3 : 21|7@1+ (2.000000,0.000000) [0.000000|252.000000] "Unit_KiloMeterPerHour" ICAS1_Gateway
 SG_ TSK_Ausrollkurve_Schub_Reku_20 m4 : 21|7@1+ (2.000000,0.000000) [0.000000|252.000000] "Unit_KiloMeterPerHour" ICAS1_Gateway
 SG_ TSK_Ausrollkurve_Segeln_01 m0 : 28|7@1+ (2.000000,0.000000) [0.000000|252.000000] "Unit_KiloMeterPerHour" ICAS1_Gateway
 SG_ TSK_Ausrollkurve_Segeln_05 m1 : 28|7@1+ (2.000000,0.000000) [0.000000|252.000000] "Unit_KiloMeterPerHour" ICAS1_Gateway
 SG_ TSK_Ausrollkurve_Segeln_09 m2 : 28|7@1+ (2.000000,0.000000) [0.000000|252.000000] "Unit_KiloMeterPerHour" ICAS1_Gateway
 SG_ TSK_Ausrollkurve_Segeln_13 m3 : 28|7@1+ (2.000000,0.000000) [0.000000|252.000000] "Unit_KiloMeterPerHour" ICAS1_Gateway
 SG_ TSK_Ausrollkurve_Segeln_17 m4 : 28|7@1+ (2.000000,0.000000) [0.000000|252.000000] "Unit_KiloMeterPerHour" ICAS1_Gateway
 SG_ TSK_Ausrollkurve_Segeln_02 m0 : 35|7@1+ (2.000000,0.000000) [0.000000|252.000000] "Unit_KiloMeterPerHour" ICAS1_Gateway
 SG_ TSK_Ausrollkurve_Segeln_06 m1 : 35|7@1+ (2.000000,0.000000) [0.000000|252.000000] "Unit_KiloMeterPerHour" ICAS1_Gateway
 SG_ TSK_Ausrollkurve_Segeln_10 m2 : 35|7@1+ (2.000000,0.000000) [0.000000|252.000000] "Unit_KiloMeterPerHour" ICAS1_Gateway
 SG_ TSK_Ausrollkurve_Segeln_14 m3 : 35|7@1+ (2.000000,0.000000) [0.000000|252.000000] "Unit_KiloMeterPerHour" ICAS1_Gateway
 SG_ TSK_Ausrollkurve_Segeln_18 m4 : 35|7@1+ (2.000000,0.000000) [0.000000|252.000000] "Unit_KiloMeterPerHour" ICAS1_Gateway
 SG_ TSK_Ausrollkurve_Segeln_03 m0 : 42|7@1+ (2.000000,0.000000) [0.000000|252.000000] "Unit_KiloMeterPerHour" ICAS1_Gateway
 SG_ TSK_Ausrollkurve_Segeln_07 m1 : 42|7@1+ (2.000000,0.000000) [0.000000|252.000000] "Unit_KiloMeterPerHour" ICAS1_Gateway
 SG_ TSK_Ausrollkurve_Segeln_11 m2 : 42|7@1+ (2.000000,0.000000) [0.000000|252.000000] "Unit_KiloMeterPerHour" ICAS1_Gateway
 SG_ TSK_Ausrollkurve_Segeln_15 m3 : 42|7@1+ (2.000000,0.000000) [0.000000|252.000000] "Unit_KiloMeterPerHour" ICAS1_Gateway
 SG_ TSK_Ausrollkurve_Segeln_19 m4 : 42|7@1+ (2.000000,0.000000) [0.000000|252.000000] "Unit_KiloMeterPerHour" ICAS1_Gateway
 SG_ TSK_Ausrollkurve_Segeln_04 m0 : 49|7@1+ (2.000000,0.000000) [0.000000|252.000000] "Unit_KiloMeterPerHour" ICAS1_Gateway
 SG_ TSK_Ausrollkurve_Segeln_08 m1 : 49|7@1+ (2.000000,0.000000) [0.000000|252.000000] "Unit_KiloMeterPerHour" ICAS1_Gateway
 SG_ TSK_Ausrollkurve_Segeln_12 m2 : 49|7@1+ (2.000000,0.000000) [0.000000|252.000000] "Unit_KiloMeterPerHour" ICAS1_Gateway
 SG_ TSK_Ausrollkurve_Segeln_16 m3 : 49|7@1+ (2.000000,0.000000) [0.000000|252.000000] "Unit_KiloMeterPerHour" ICAS1_Gateway
 SG_ TSK_Ausrollkurve_Segeln_20 m4 : 49|7@1+ (2.000000,0.000000) [0.000000|252.000000] "Unit_KiloMeterPerHour" ICAS1_Gateway
 SG_ TSK_Ausrollkurve_Mux M : 56|3@1+ (1.000000,0.000000) [0.000000|7.000000] "" ICAS1_Gateway
 SG_ TSK_Ausrollkurve_Reku  : 59|1@1+ (1.000000,0.000000) [0.000000|1.000000] "" ICAS1_Gateway
 SG_ TSK_Ausrollkurve_Schrittweite  : 60|1@1+ (1.000000,0.000000) [0.000000|1.000000] "" ICAS1_Gateway
 SG_ TSK_Ausrollkurve_Zaehler  : 61|2@1+ (1.000000,0.000000) [0.000000|3.000000] "" ICAS1_Gateway

BO_ 1716 VIN_01: 8 ICAS1_Gateway
 SG_ VIN_01_MUX M : 0|2@1+ (1.000000,0.000000) [0.000000|3.000000] "" Airbag Motor_BEV
 SG_ KS_Geheimnis_1 m0 : 8|8@1+ (1.000000,0.000000) [0.000000|255.000000] "" Airbag
 SG_ VIN_4 m1 : 8|8@1+ (1.000000,0.000000) [0.000000|255.000000] "" Airbag Motor_BEV
 SG_ VIN_11 m2 : 8|8@1+ (1.000000,0.000000) [0.000000|255.000000] "" Airbag Motor_BEV
 SG_ KS_Geheimnis_2 m0 : 16|8@1+ (1.000000,0.000000) [0.000000|255.000000] "" Airbag
 SG_ VIN_5 m1 : 16|8@1+ (1.000000,0.000000) [0.000000|255.000000] "" Airbag Motor_BEV
 SG_ VIN_12 m2 : 16|8@1+ (1.000000,0.000000) [0.000000|255.000000] "" Airbag Motor_BEV
 SG_ KS_Geheimnis_3 m0 : 24|8@1+ (1.000000,0.000000) [0.000000|255.000000] "" Airbag
 SG_ VIN_6 m1 : 24|8@1+ (1.000000,0.000000) [0.000000|255.000000] "" Airbag Motor_BEV
 SG_ VIN_13 m2 : 24|8@1+ (1.000000,0.000000) [0.000000|255.000000] "" Airbag Motor_BEV
 SG_ KS_Geheimnis_4 m0 : 32|8@1+ (1.000000,0.000000) [0.000000|255.000000] "" Airbag
 SG_ VIN_7 m1 : 32|8@1+ (1.000000,0.000000) [0.000000|255.000000] "" Airbag Motor_BEV
 SG_ VIN_14 m2 : 32|8@1+ (1.000000,0.000000) [0.000000|255.000000] "" Airbag Motor_BEV
 SG_ VIN_1 m0 : 40|8@1+ (1.000000,0.000000) [0.000000|255.000000] "" Airbag Motor_BEV
 SG_ VIN_8 m1 : 40|8@1+ (1.000000,0.000000) [0.000000|255.000000] "" Airbag Motor_BEV
 SG_ VIN_15 m2 : 40|8@1+ (1.000000,0.000000) [0.000000|255.000000] "" Airbag Motor_BEV
 SG_ VIN_2 m0 : 48|8@1+ (1.000000,0.000000) [0.000000|255.000000] "" Airbag Motor_BEV
 SG_ VIN_9 m1 : 48|8@1+ (1.000000,0.000000) [0.000000|255.000000] "" Airbag Motor_BEV
 SG_ VIN_16 m2 : 48|8@1+ (1.000000,0.000000) [0.000000|255.000000] "" Airbag Motor_BEV
 SG_ VIN_3 m0 : 56|8@1+ (1.000000,0.000000) [0.000000|255.000000] "" Airbag Motor_BEV
 SG_ VIN_10 m1 : 56|8@1+ (1.000000,0.000000) [0.000000|255.000000] "" Airbag Motor_BEV
 SG_ VIN_17 m2 : 56|8@1+ (1.000000,0.000000) [0.000000|255.000000] "" Airbag Motor_BEV

BO_ 261 VMM_01: 8 ICAS1_Gateway
 SG_ VMM_01_CRC  : 0|8@1+ (1.000000,0.000000) [0.000000|255.000000] "" Motor_BEV
 SG_ VMM_01_BZ  : 8|4@1+ (1.000000,0.000000) [0.000000|15.000000] "" Motor_BEV
 SG_ HMS_P_beibehalten_GE  : 12|2@1+ (1.000000,0.000000) [0.000000|3.000000] "" Vector__XXX
 SG_ VZM_Unterdrueckung_Antriebsmom  : 14|1@1+ (1.000000,0.000000) [0.000000|1.000000] "" Airbag Motor_BEV
 SG_ HMS_halten_nicht_verfuegbar  : 20|1@1+ (1.000000,0.000000) [0.000000|1.000000] "" Vector__XXX
 SG_ HMS_parken_nicht_verfuegbar  : 32|1@1+ (1.000000,0.000000) [0.000000|1.000000] "" Vector__XXX
 SG_ HMS_Anforderung_GE  : 33|3@1+ (1.000000,0.000000) [0.000000|7.000000] "" Vector__XXX
 SG_ HMS_Systemstatus  : 36|4@1+ (1.000000,0.000000) [0.000000|15.000000] "" Motor_BEV
 SG_ HMS_Stillstand  : 40|3@1+ (1.000000,0.000000) [0.000000|7.000000] "" Motor_BEV
 SG_ HMS_aktives_System  : 43|5@1+ (1.000000,0.000000) [0.000000|31.000000] "" Motor_BEV
 SG_ VMM_Inkonsistenz_GE  : 48|1@1+ (1.000000,0.000000) [0.000000|1.000000] "" Motor_BEV
 SG_ VMM_Inkonsistenz_HVLM  : 49|1@1+ (1.000000,0.000000) [0.000000|1.000000] "" Motor_BEV
 SG_ HMS_Fehlerstatus  : 50|3@1+ (1.000000,0.000000) [0.000000|7.000000] "" Vector__XXX
 SG_ HMS_Index_Haltemoment  : 53|1@1+ (1.000000,0.000000) [0.000000|1.000000] "" Motor_BEV
 SG_ HMS_Haltemoment  : 54|10@1+ (10.000000,0.000000) [0.000000|10210.000000] "Unit_NewtoMeter" Motor_BEV

BO_ 313 VMM_02: 32 ICAS1_Gateway
 SG_ VMM_02_CRC  : 0|8@1+ (1.000000,0.000000) [0.000000|255.000000] "" Motor_BEV
 SG_ VMM_02_BZ  : 8|4@1+ (1.000000,0.000000) [0.000000|15.000000] "" Motor_BEV
 SG_ VZM_aktiver_Basisservice  : 12|3@1+ (1.000000,0.000000) [0.000000|7.000000] "" Motor_BEV
 SG_ VZM_Anhalteweg_nicht_verfuegbar  : 15|1@1+ (1.000000,0.000000) [0.000000|1.000000] "" Motor_BEV
 SG_ VZM_Fahrer_bremst  : 16|1@1+ (1.000000,0.000000) [0.000000|1.000000] "" Motor_BEV
 SG_ VZM_QBit_Fahrer_bremst  : 17|1@1+ (1.000000,0.000000) [0.000000|1.000000] "" Motor_BEV
 SG_ VMM_MKB_codiert  : 18|1@1+ (1.000000,0.000000) [0.000000|1.000000] "" Airbag
 SG_ VMM_Inkonsistenz_EBKV  : 19|1@1+ (1.000000,0.000000) [0.000000|1.000000] "" Vector__XXX
 SG_ VMM_Notstopp_Status  : 20|3@1+ (1.000000,0.000000) [0.000000|7.000000] "" Motor_BEV
 SG_ VZM_Warnruck_nicht_verfuegbar  : 23|1@1+ (1.000000,0.000000) [0.000000|1.000000] "" Motor_BEV
 SG_ VZM_Warnruckeln_nicht_verfuegbar  : 24|1@1+ (1.000000,0.000000) [0.000000|1.000000] "" Motor_BEV
 SG_ VZM_Bkd_nicht_verfuegbar  : 25|1@1+ (1.000000,0.000000) [0.000000|1.000000] "" Motor_BEV
 SG_ VMM_Bremslicht_defekt  : 26|1@1+ (1.000000,0.000000) [0.000000|1.000000] "" Motor_BEV
 SG_ VZM_Fahrer_bremst_deutlich  : 27|1@1+ (1.000000,0.000000) [0.000000|1.000000] "" Airbag Motor_BEV
 SG_ VZM_TSK_SRBM_Anf  : 28|1@1+ (1.000000,0.000000) [0.000000|1.000000] "" Motor_BEV
 SG_ VZM_TSK_SRBM_nicht_verfuegbar  : 29|1@1+ (1.000000,0.000000) [0.000000|1.000000] "" Motor_BEV
 SG_ VZM_Verz_Reg_aktiv  : 30|5@1+ (1.000000,0.000000) [0.000000|31.000000] "" Motor_BEV
 SG_ VZM_Verz_Reg_nicht_verfuegbar  : 35|1@1+ (1.000000,0.000000) [0.000000|1.000000] "" Motor_BEV
 SG_ VMM_Inkonsistenz_KAS  : 36|1@1+ (1.000000,0.000000) [0.000000|1.000000] "" Motor_BEV
 SG_ VMM_Bremslicht_unplausibel  : 37|1@1+ (1.000000,0.000000) [0.000000|1.000000] "" Motor_BEV
 SG_ VMM_Inkonsistenz_ACC  : 38|1@1+ (1.000000,0.000000) [0.000000|1.000000] "" Motor_BEV
 SG_ VMM_Inkonsistenz_AWV_PCF  : 39|1@1+ (1.000000,0.000000) [0.000000|1.000000] "" Motor_BEV
 SG_ VMM_Inkonsistenz_ARA  : 40|1@1+ (1.000000,0.000000) [0.000000|1.000000] "" Motor_BEV
 SG_ VMM_Inkonsistenz_ParkAssist  : 41|1@1+ (1.000000,0.000000) [0.000000|1.000000] "" Motor_BEV
 SG_ VMM_Inkonsistenz_FAS_VK  : 42|1@1+ (1.000000,0.000000) [0.000000|1.000000] "" Motor_BEV
 SG_ VMM_Inkonsistenz_NV  : 43|1@1+ (1.000000,0.000000) [0.000000|1.000000] "" Motor_BEV
 SG_ VMM_Inkonsistenz_RCTA  : 44|1@1+ (1.000000,0.000000) [0.000000|1.000000] "" Motor_BEV
 SG_ VMM_Inkonsistenz_TSK  : 45|1@1+ (1.000000,0.000000) [0.000000|1.000000] "" Motor_BEV
 SG_ VMM_Inkonsistenz_MO  : 46|1@1+ (1.000000,0.000000) [0.000000|1.000000] "" Motor_BEV
 SG_ VMM_Inkonsistenz_AEB  : 47|1@1+ (1.000000,0.000000) [0.000000|1.000000] "" Vector__XXX
 SG_ VMM_Fahrer_Bremskraft_bestimmend  : 48|1@1+ (1.000000,0.000000) [0.000000|1.000000] "" Motor_BEV
 SG_ VMM_Inkonsistenz_EA  : 49|1@1+ (1.000000,0.000000) [0.000000|1.000000] "" Motor_BEV
 SG_ VZM_Status_Wegregelung  : 50|2@1+ (1.000000,0.000000) [0.000000|3.000000] "" Motor_BEV
 SG_ VZM_Verz_ASIL_Verfuegbarkeit  : 52|3@1+ (1.000000,0.000000) [0.000000|7.000000] "" Motor_BEV
 SG_ VZM_aktives_System  : 55|5@1+ (1.000000,0.000000) [0.000000|31.000000] "" Airbag Motor_BEV
 SG_ VZM_Verz_Begrenzung  : 60|1@1+ (1.000000,0.000000) [0.000000|1.000000] "" Motor_BEV
 SG_ VZM_Systemstatus  : 61|3@1+ (1.000000,0.000000) [0.000000|7.000000] "" Motor_BEV
 SG_ VZM_SRBM_Soll  : 64|12@1+ (8.000000,0.000000) [0.000000|32744.000000] "Unit_NewtoMeter" Motor_BEV
 SG_ VZM_SRBM_Ist  : 76|12@1+ (8.000000,0.000000) [0.000000|32744.000000] "Unit_NewtoMeter" Motor_BEV
 SG_ VZM_SRBM_max_Gradient  : 88|7@1+ (50.000000,0.000000) [0.000000|6250.000000] "Unit_NewtoMeterPerSecon" Motor_BEV
 SG_ VMM_Inkonsistenz_KAM  : 95|1@1+ (1.000000,0.000000) [0.000000|1.000000] "" Vector__XXX

BO_ 2463978663 VZE_04: 32 ICAS1_Gateway
 SG_ VZE_Anzeigemodus  : 0|2@1+ (1.000000,0.000000) [0.000000|3.000000] "" Vector__XXX
 SG_ VZE_Hinweistext  : 2|3@1+ (1.000000,0.000000) [1.000000|7.000000] "" Motor_BEV
 SG_ VZE_Verkehrszeichen_Einheit  : 8|1@1+ (1.000000,0.000000) [0.000000|1.000000] "" Vector__XXX
 SG_ VZE_Anzeigeunterdrueck_Zeichen_3  : 9|1@1+ (1.000000,0.000000) [0.000000|1.000000] "" Vector__XXX
 SG_ VZE_Anzeigeunterdrueck_Zeichen_2  : 10|1@1+ (1.000000,0.000000) [0.000000|1.000000] "" Vector__XXX
 SG_ VZE_Verkehrszeichen_1  : 11|8@1+ (1.000000,0.000000) [1.000000|255.000000] "" Motor_BEV
 SG_ VZE_Verkehrszeichen_2  : 19|8@1+ (1.000000,0.000000) [1.000000|255.000000] "" Vector__XXX
 SG_ VZE_Verkehrszeichen_3  : 27|8@1+ (1.000000,0.000000) [1.000000|255.000000] "" Vector__XXX
 SG_ VZE_Warnung_Verkehrszeichen_1  : 35|1@1+ (1.000000,0.000000) [0.000000|1.000000] "" Vector__XXX
 SG_ VZE_Warnung_Verkehrszeichen_2  : 36|1@1+ (1.000000,0.000000) [0.000000|1.000000] "" Vector__XXX
 SG_ VZE_Warnung_Verkehrszeichen_3  : 37|1@1+ (1.000000,0.000000) [0.000000|1.000000] "" Vector__XXX
 SG_ VZE_Zusatzschild_1  : 38|4@1+ (1.000000,0.000000) [1.000000|15.000000] "" Vector__XXX
 SG_ VZE_Zusatzschild_2  : 42|4@1+ (1.000000,0.000000) [1.000000|15.000000] "" Vector__XXX
 SG_ VZE_Zusatzschild_3  : 46|4@1+ (1.000000,0.000000) [1.000000|15.000000] "" Vector__XXX
 SG_ VZE_Anzeigeunterdrueck_Zeichen_1  : 50|1@1+ (1.000000,0.000000) [0.000000|1.000000] "" Vector__XXX
 SG_ VZE_Zeichen_01_KameraWied  : 51|1@1+ (1.000000,0.000000) [0.000000|1.000000] "" Motor_BEV
 SG_ VZE_Zeichen_02_KameraWied  : 52|1@1+ (1.000000,0.000000) [0.000000|1.000000] "" Vector__XXX
 SG_ VZE_Zeichen_03_KameraWied  : 53|1@1+ (1.000000,0.000000) [0.000000|1.000000] "" Vector__XXX
 SG_ VZE_Zeichen_01_Kamera  : 54|1@1+ (1.000000,0.000000) [0.000000|1.000000] "" Motor_BEV
 SG_ VZE_Zeichen_01_Karte  : 55|1@1+ (1.000000,0.000000) [0.000000|1.000000] "" Vector__XXX
 SG_ VZE_Zeichen_01_Gesetz  : 56|1@1+ (1.000000,0.000000) [0.000000|1.000000] "" Vector__XXX
 SG_ VZE_Zeichen_02_Kamera  : 57|1@1+ (1.000000,0.000000) [0.000000|1.000000] "" Vector__XXX
 SG_ VZE_Zeichen_02_Karte  : 58|1@1+ (1.000000,0.000000) [0.000000|1.000000] "" Vector__XXX
 SG_ VZE_Zeichen_02_Gesetz  : 59|1@1+ (1.000000,0.000000) [0.000000|1.000000] "" Vector__XXX
 SG_ VZE_Zeichen_03_Kamera  : 60|1@1+ (1.000000,0.000000) [0.000000|1.000000] "" Vector__XXX
 SG_ VZE_Zeichen_03_Karte  : 61|1@1+ (1.000000,0.000000) [0.000000|1.000000] "" Vector__XXX
 SG_ VZE_Zeichen_03_Gesetz  : 62|1@1+ (1.000000,0.000000) [0.000000|1.000000] "" Vector__XXX
 SG_ VZE_Gong  : 63|1@1+ (1.000000,0.000000) [0.000000|1.000000] "" Vector__XXX
 SG_ VZE_Anzeigeunterdrueck_Zeichen_5  : 72|1@1+ (1.000000,0.000000) [0.000000|1.000000] "" Vector__XXX
 SG_ VZE_Zeichen_05_KameraWied  : 73|1@1+ (1.000000,0.000000) [0.000000|1.000000] "" Vector__XXX
 SG_ VZE_Zeichen_05_Kamera  : 74|1@1+ (1.000000,0.000000) [0.000000|1.000000] "" Vector__XXX
 SG_ VZE_Verkehrszeichen_4  : 75|8@1+ (1.000000,0.000000) [1.000000|255.000000] "" Motor_BEV
 SG_ VZE_Verkehrszeichen_5  : 83|8@1+ (1.000000,0.000000) [1.000000|255.000000] "" Motor_BEV
 SG_ VZE_Anhaenger_Vmax  : 91|4@1+ (10.000000,10.000000) [10.000000|140.000000] "Unit_KiloMeterPerHour" Vector__XXX
 SG_ VZE_Zeichen_04_Gesetz  : 95|1@1+ (1.000000,0.000000) [0.000000|1.000000] "" Vector__XXX
 SG_ VZE_Zeichen_04_Kamera  : 96|1@1+ (1.000000,0.000000) [0.000000|1.000000] "" Vector__XXX
 SG_ VZE_Zeichen_04_KameraWied  : 97|1@1+ (1.000000,0.000000) [0.000000|1.000000] "" Vector__XXX
 SG_ VZE_Zeichen_04_Karte  : 98|1@1+ (1.000000,0.000000) [0.000000|1.000000] "" Vector__XXX
 SG_ VZE_Warnung_Verkehrszeichen_4  : 99|1@1+ (1.000000,0.000000) [0.000000|1.000000] "" Vector__XXX
 SG_ VZE_Warnung_Verkehrszeichen_5  : 100|1@1+ (1.000000,0.000000) [0.000000|1.000000] "" Vector__XXX
 SG_ VZE_Zeichen_05_Gesetz  : 101|1@1+ (1.000000,0.000000) [0.000000|1.000000] "" Vector__XXX
 SG_ VZE_Zusatzschild_4  : 102|4@1+ (1.000000,0.000000) [1.000000|15.000000] "" Vector__XXX
 SG_ VZE_Zusatzschild_5  : 106|4@1+ (1.000000,0.000000) [1.000000|15.000000] "" Vector__XXX
 SG_ VZE_Baustelle  : 110|2@1+ (1.000000,0.000000) [0.000000|3.000000] "" Vector__XXX
 SG_ VZE_Zeichen_05_Karte  : 112|1@1+ (1.000000,0.000000) [0.000000|1.000000] "" Vector__XXX
 SG_ VZE_Zeichen_05_Entfernung  : 113|7@1+ (1.000000,0.000000) [1.000000|127.000000] "Unit_Meter" Motor_BEV
 SG_ VZE_Zeichen_05_Entfernung_StdA  : 120|7@1+ (1.000000,0.000000) [1.000000|127.000000] "Unit_Meter" Motor_BEV
 SG_ VZE_Anzeigeunterdrueck_Zeichen_4  : 127|1@1+ (1.000000,0.000000) [0.000000|1.000000] "" Vector__XXX
 SG_ VZE_Verkehrszeichen_6  : 128|8@1+ (1.000000,0.000000) [1.000000|255.000000] "Unit_None" Motor_BEV
 SG_ VZE_Zusatzschild_6  : 136|4@1+ (1.000000,0.000000) [1.000000|15.000000] "" Vector__XXX
 SG_ VZE_Zeichen_06_Entfernung  : 140|7@1+ (1.000000,0.000000) [1.000000|127.000000] "Unit_Meter" Motor_BEV
 SG_ VZE_Zeichen_06_Entfernung_StdA  : 147|7@1+ (1.000000,0.000000) [1.000000|127.000000] "Unit_Meter" Motor_BEV
 SG_ VZE_Umweltinfo_Naesse  : 154|1@1+ (1.000000,0.000000) [0.000000|1.000000] "" Motor_BEV
 SG_ VZE_Umweltinfo_Nebel  : 155|1@1+ (1.000000,0.000000) [0.000000|1.000000] "" Motor_BEV
 SG_ VZE_Umweltinfo_Anhaengerbetrieb  : 156|1@1+ (1.000000,0.000000) [0.000000|1.000000] "" Vector__XXX
 SG_ VZE_Erweiterte_Information  : 157|8@1+ (1.000000,0.000000) [1.000000|255.000000] "Unit_None" Vector__XXX
 SG_ VZE_Tempowarnung_Status  : 165|1@1+ (1.000000,0.000000) [0.000000|1.000000] "" Vector__XXX
 SG_ VZE_Tempowarnung_Einheit  : 166|1@1+ (1.000000,0.000000) [0.000000|1.000000] "" Vector__XXX
 SG_ VZE_Tempowarnung_Offset  : 167|5@1+ (1.000000,0.000000) [1.000000|31.000000] "" Vector__XXX
 SG_ VZE_FoD_Status  : 206|2@1+ (1.000000,0.000000) [0.000000|3.000000] "" Vector__XXX
 SG_ VZE_Anzeige_ZS_1  : 208|4@1+ (1.000000,0.000000) [1.000000|15.000000] "Unit_None" Vector__XXX
 SG_ VZE_Anzeige_ZS_2  : 212|4@1+ (1.000000,0.000000) [1.000000|15.000000] "Unit_None" Vector__XXX
 SG_ VZE_Anzeige_ZS_3  : 216|4@1+ (1.000000,0.000000) [1.000000|15.000000] "Unit_None" Vector__XXX
 SG_ VZE_Hinweistext_03  : 220|4@1+ (1.000000,0.000000) [1.000000|15.000000] "" Vector__XXX
 SG_ VZE_Land  : 224|5@1+ (1.000000,0.000000) [1.000000|31.000000] "" Vector__XXX
 SG_ VZE_Warnung_VZ_1  : 229|1@1+ (1.000000,0.000000) [0.000000|1.000000] "" Vector__XXX
 SG_ VZE_Warnung_VZ_2  : 230|1@1+ (1.000000,0.000000) [0.000000|1.000000] "" Vector__XXX
 SG_ VZE_Warnung_VZ_3  : 231|1@1+ (1.000000,0.000000) [0.000000|1.000000] "" Vector__XXX
 SG_ VZE_Anzeige_VZ_1  : 232|8@1+ (1.000000,0.000000) [1.000000|255.000000] "" Vector__XXX
 SG_ VZE_Anzeige_VZ_2  : 240|8@1+ (1.000000,0.000000) [1.000000|255.000000] "Unit_None" Vector__XXX
 SG_ VZE_Anzeige_VZ_3  : 248|8@1+ (1.000000,0.000000) [1.000000|255.000000] "Unit_None" Vector__XXX

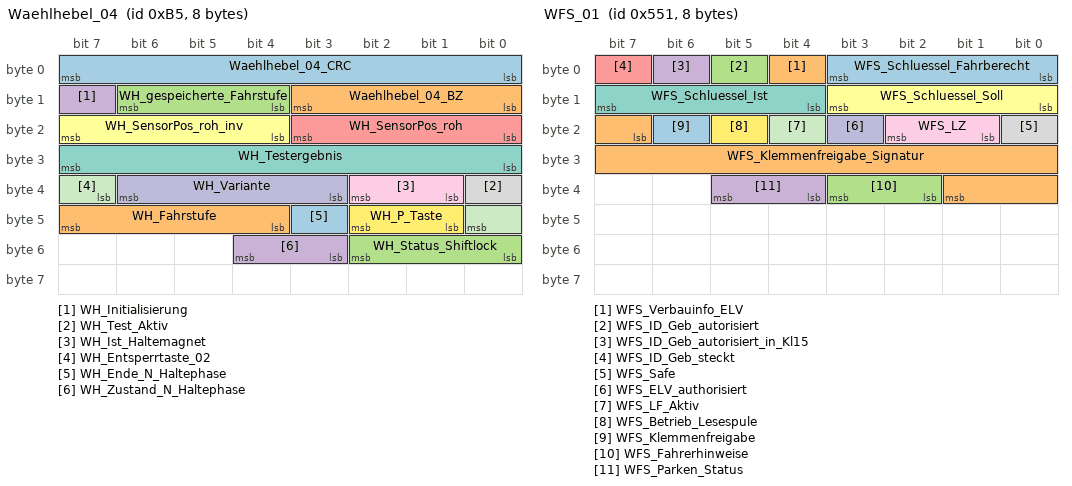
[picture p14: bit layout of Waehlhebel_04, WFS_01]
BO_ 181 Waehlhebel_04: 8 ICAS1_Gateway
 SG_ Waehlhebel_04_CRC  : 0|8@1+ (1.000000,0.000000) [0.000000|255.000000] "" Motor_BEV
 SG_ Waehlhebel_04_BZ  : 8|4@1+ (1.000000,0.000000) [0.000000|15.000000] "" Motor_BEV
 SG_ WH_gespeicherte_Fahrstufe  : 12|3@1+ (1.000000,0.000000) [0.000000|7.000000] "" Vector__XXX
 SG_ WH_Initialisierung  : 15|1@1+ (1.000000,0.000000) [0.000000|1.000000] "" Motor_BEV
 SG_ WH_SensorPos_roh  : 16|4@1+ (1.000000,0.000000) [0.000000|15.000000] "" Motor_BEV
 SG_ WH_SensorPos_roh_inv  : 20|4@1+ (1.000000,0.000000) [0.000000|15.000000] "" Motor_BEV
 SG_ WH_Testergebnis  : 24|8@1+ (1.000000,0.000000) [0.000000|255.000000] "" Vector__XXX
 SG_ WH_Test_Aktiv  : 32|1@1+ (1.000000,0.000000) [0.000000|1.000000] "" Vector__XXX
 SG_ WH_Ist_Haltemagnet  : 33|2@1+ (1.000000,0.000000) [0.000000|3.000000] "" Motor_BEV
 SG_ WH_Variante  : 35|4@1+ (1.000000,0.000000) [0.000000|15.000000] "" Motor_BEV
 SG_ WH_Entsperrtaste_02  : 39|2@1+ (1.000000,0.000000) [0.000000|3.000000] "" Motor_BEV
 SG_ WH_P_Taste  : 41|2@1+ (1.000000,0.000000) [0.000000|3.000000] "" Motor_BEV
 SG_ WH_Ende_N_Haltephase  : 43|1@1+ (1.000000,0.000000) [0.000000|1.000000] "" Vector__XXX
 SG_ WH_Fahrstufe  : 44|4@1+ (1.000000,0.000000) [0.000000|15.000000] "" Motor_BEV
 SG_ WH_Status_Shiftlock  : 48|3@1+ (1.000000,0.000000) [0.000000|7.000000] "" Motor_BEV
 SG_ WH_Zustand_N_Haltephase  : 51|2@1+ (1.000000,0.000000) [0.000000|3.000000] "" Vector__XXX

BO_ 2463978687 Waehlhebel_06: 8 ICAS1_Gateway
 SG_ WH_Fehler_Haltemagnet_Status  : 41|1@1+ (1.000000,0.000000) [0.000000|1.000000] "" Motor_BEV
 SG_ WH_Fehler_CRC_SBM  : 42|1@1+ (1.000000,0.000000) [0.000000|1.000000] "" Motor_BEV
 SG_ WH_Fehler_CRC_SBM_Status  : 43|1@1+ (1.000000,0.000000) [0.000000|1.000000] "" Motor_BEV
 SG_ WH_Fehler_Timeout_SBM  : 44|1@1+ (1.000000,0.000000) [0.000000|1.000000] "" Motor_BEV
 SG_ WH_Fehler_Timeout_SBM_Status  : 45|1@1+ (1.000000,0.000000) [0.000000|1.000000] "" Motor_BEV
 SG_ WH_Fehler_Ueberspannung  : 46|1@1+ (1.000000,0.000000) [0.000000|1.000000] "" Motor_BEV
 SG_ WH_Fehler_Ueberspannung_Status  : 47|1@1+ (1.000000,0.000000) [0.000000|1.000000] "" Motor_BEV
 SG_ WH_Fehler_BZ_SBM  : 48|1@1+ (1.000000,0.000000) [0.000000|1.000000] "" Motor_BEV
 SG_ WH_Fehler_BZ_SBM_Status  : 49|1@1+ (1.000000,0.000000) [0.000000|1.000000] "" Motor_BEV
 SG_ WH_Fehler_Unterspannung  : 50|1@1+ (1.000000,0.000000) [0.000000|1.000000] "" Motor_BEV
 SG_ WH_Fehler_Unterspannung_Status  : 51|1@1+ (1.000000,0.000000) [0.000000|1.000000] "" Motor_BEV
 SG_ WH_Fehler_Ausleuchtung  : 52|1@1+ (1.000000,0.000000) [0.000000|1.000000] "" Motor_BEV
 SG_ WH_Fehler_Ausleuchtung_Status  : 53|1@1+ (1.000000,0.000000) [0.000000|1.000000] "" Motor_BEV
 SG_ WH_Fehler_Entsperrtaste  : 54|1@1+ (1.000000,0.000000) [0.000000|1.000000] "" Motor_BEV
 SG_ WH_Fehler_Entsperrtaste_Status  : 55|1@1+ (1.000000,0.000000) [0.000000|1.000000] "" Motor_BEV
 SG_ WH_Fehler_P_Taste  : 56|1@1+ (1.000000,0.000000) [0.000000|1.000000] "" Motor_BEV
 SG_ WH_Fehler_P_Taste_Status  : 57|1@1+ (1.000000,0.000000) [0.000000|1.000000] "" Motor_BEV
 SG_ WH_Fehler_Sensor_einfach  : 58|1@1+ (1.000000,0.000000) [0.000000|1.000000] "" Motor_BEV
 SG_ WH_Fehler_Sensor_einfach_Status  : 59|1@1+ (1.000000,0.000000) [0.000000|1.000000] "" Motor_BEV
 SG_ WH_Fehler_Sensor_mehrfach  : 60|1@1+ (1.000000,0.000000) [0.000000|1.000000] "" Motor_BEV
 SG_ WH_Fehler_Sensor_mehrfach_Status  : 61|1@1+ (1.000000,0.000000) [0.000000|1.000000] "" Motor_BEV
 SG_ WH_Fehler_Shiftlock  : 62|1@1+ (1.000000,0.000000) [0.000000|1.000000] "" Motor_BEV
 SG_ WH_Fehler_Shiftlock_Status  : 63|1@1+ (1.000000,0.000000) [0.000000|1.000000] "" Motor_BEV

BO_ 916 WBA_03: 8 Motor_BEV
 SG_ WBA_03_CRC  : 0|8@1+ (1.000000,0.000000) [0.000000|255.000000] "" ICAS1_Gateway
 SG_ WBA_03_BZ  : 8|4@1+ (1.000000,0.000000) [0.000000|15.000000] "" ICAS1_Gateway
 SG_ WBA_Fahrstufe_02  : 12|4@1+ (1.000000,0.000000) [0.000000|15.000000] "" ICAS1_Gateway ICAS1_KommunikationsServer
 SG_ WBA_ZielFahrstufe  : 16|4@1+ (1.000000,0.000000) [0.000000|15.000000] "" ICAS1_Gateway
 SG_ WBA_GE_Warnung_02  : 20|4@1+ (1.000000,0.000000) [0.000000|15.000000] "" ICAS1_Gateway
 SG_ WBA_eing_Gang_02  : 24|4@1+ (1.000000,0.000000) [0.000000|15.000000] "" ICAS1_Gateway
 SG_ WBA_GE_Texte  : 28|3@1+ (1.000000,0.000000) [0.000000|7.000000] "" ICAS1_Gateway
 SG_ WBA_Segeln_aktiv  : 31|1@1+ (1.000000,0.000000) [0.000000|1.000000] "" ICAS1_Gateway
 SG_ WBA_Schaltschema_02  : 32|3@1+ (1.000000,0.000000) [0.000000|7.000000] "" ICAS1_Gateway
 SG_ WBA_Schaltschema_FS_inaktiv  : 35|2@1+ (1.000000,0.000000) [0.000000|3.000000] "" ICAS1_Gateway
 SG_ WBA_GE_Zusatzwarnungen  : 37|3@1+ (1.000000,0.000000) [0.000000|7.000000] "" ICAS1_Gateway
 SG_ GE_Sollgang  : 40|4@1+ (1.000000,0.000000) [0.000000|15.000000] "" ICAS1_Gateway
 SG_ GE_Tipschaltempf_verfuegbar  : 44|1@1+ (1.000000,0.000000) [0.000000|1.000000] "" ICAS1_Gateway
 SG_ WBA_GE_Texte_02  : 45|3@1+ (1.000000,0.000000) [0.000000|7.000000] "" ICAS1_Gateway
 SG_ WBA_Schaltschema_Tippgasse  : 48|1@1+ (1.000000,0.000000) [0.000000|1.000000] "" ICAS1_Gateway
 SG_ WBA_Schaltschema_Fahreraktion  : 49|1@1+ (1.000000,0.000000) [0.000000|1.000000] "" ICAS1_Gateway
 SG_ WBA_Schaltschema_FS_vorwaerts  : 50|2@1+ (1.000000,0.000000) [0.000000|3.000000] "" ICAS1_Gateway
 SG_ WBA_Shiftlock_Lampe  : 52|1@1+ (1.000000,0.000000) [0.000000|1.000000] "" ICAS1_Gateway
 SG_ WBA_Anforderung_Akustik  : 53|1@1+ (1.000000,0.000000) [0.000000|1.000000] "" ICAS1_Gateway
 SG_ WBA_Blinken  : 54|1@1+ (1.000000,0.000000) [0.000000|1.000000] "" ICAS1_Gateway
 SG_ GE_Wiederstart_Anz_Std  : 55|1@1+ (1.000000,0.000000) [0.000000|1.000000] "" ICAS1_Gateway
 SG_ GE_Stoppverbot_Anz_01  : 56|1@1+ (1.000000,0.000000) [0.000000|1.000000] "" ICAS1_Gateway
 SG_ GE_Stoppverbot_Anz_02  : 57|1@1+ (1.000000,0.000000) [0.000000|1.000000] "" ICAS1_Gateway
 SG_ GE_Stoppverbot_Anz_03  : 58|1@1+ (1.000000,0.000000) [0.000000|1.000000] "" ICAS1_Gateway
 SG_ GE_Stoppverbot_Anz_04  : 59|1@1+ (1.000000,0.000000) [0.000000|1.000000] "" ICAS1_Gateway
 SG_ GE_Stoppverbot_Anz_05  : 60|1@1+ (1.000000,0.000000) [0.000000|1.000000] "" ICAS1_Gateway
 SG_ GE_Stoppverbot_Anz_06  : 61|1@1+ (1.000000,0.000000) [0.000000|1.000000] "" ICAS1_Gateway
 SG_ GE_Stoppverbot_Anz_07  : 62|1@1+ (1.000000,0.000000) [0.000000|1.000000] "" ICAS1_Gateway
 SG_ GE_Stoppverbot_Anz_Std  : 63|1@1+ (1.000000,0.000000) [0.000000|1.000000] "" ICAS1_Gateway

BO_ 1361 WFS_01: 8 ICAS1_Gateway
 SG_ WFS_Schluessel_Fahrberecht  : 0|4@1+ (1.000000,0.000000) [0.000000|15.000000] "" Vector__XXX
 SG_ WFS_Verbauinfo_ELV  : 4|1@1+ (1.000000,0.000000) [0.000000|1.000000] "" Vector__XXX
 SG_ WFS_ID_Geb_autorisiert  : 5|1@1+ (1.000000,0.000000) [0.000000|1.000000] "" Vector__XXX
 SG_ WFS_ID_Geb_autorisiert_in_Kl15  : 6|1@1+ (1.000000,0.000000) [0.000000|1.000000] "" Vector__XXX
 SG_ WFS_ID_Geb_steckt  : 7|1@1+ (1.000000,0.000000) [0.000000|1.000000] "" Vector__XXX
 SG_ WFS_Schluessel_Soll  : 8|4@1+ (1.000000,0.000000) [0.000000|15.000000] "" Vector__XXX
 SG_ WFS_Schluessel_Ist  : 12|4@1+ (1.000000,0.000000) [0.000000|15.000000] "" Vector__XXX
 SG_ WFS_Safe  : 16|1@1+ (1.000000,0.000000) [0.000000|1.000000] "" Vector__XXX
 SG_ WFS_LZ  : 17|2@1+ (1.000000,0.000000) [0.000000|3.000000] "" Vector__XXX
 SG_ WFS_ELV_authorisiert  : 19|1@1+ (1.000000,0.000000) [0.000000|1.000000] "" Vector__XXX
 SG_ WFS_LF_Aktiv  : 20|1@1+ (1.000000,0.000000) [0.000000|1.000000] "" Vector__XXX
 SG_ WFS_Betrieb_Lesespule  : 21|1@1+ (1.000000,0.000000) [0.000000|1.000000] "" Vector__XXX
 SG_ WFS_Klemmenfreigabe  : 22|1@1+ (1.000000,0.000000) [0.000000|1.000000] "" Motor_BEV
 SG_ WFS_Klemmenfreigabe_Signatur  : 23|11@1+ (1.000000,0.000000) [0.000000|2047.000000] "" Vector__XXX
 SG_ WFS_Fahrerhinweise  : 34|2@1+ (1.000000,0.000000) [0.000000|3.000000] "" Vector__XXX
 SG_ WFS_Parken_Status  : 36|2@1+ (1.000000,0.000000) [0.000000|3.000000] "" Vector__XXX

BO_ 2617028096 XCP_Airbag_CRO_01: 64 Vector__XXX
 SG_ XCP_Airbag_CRO_01_Data  : 0|512@1+ (1.000000,0.000000) [0.000000|13407807929942597099574024998205846127479365820592393377723561443721764030073546976801874298166903427690031858186486050853753882811946569946433649006084096.000000] "" Airbag

BO_ 2617028097 XCP_Airbag_DTO_01: 64 Airbag
 SG_ XCP_Airbag_DTO_01_Data  : 0|512@1+ (1.000000,0.000000) [0.000000|13407807929942597099574024998205846127479365820592393377723561443721764030073546976801874298166903427690031858186486050853753882811946569946433649006084096.000000] "" Vector__XXX

BO_ 2617239040 XCP_EMotor_01_CRO_01: 64 Vector__XXX
 SG_ XCP_EMotor_01_CRO_01_Data  : 0|64@1+ (1.000000,0.000000) [0.000000|18446744073709551616.000000] "" LE1

BO_ 2617239041 XCP_EMotor_01_DTO_01: 64 LE1
 SG_ XCP_EMotor_01_DTO_01_Data  : 0|64@1+ (1.000000,0.000000) [0.000000|18446744073709551616.000000] "" Vector__XXX

BO_ 2617239042 XCP_EMotor_01_DTO_02: 64 LE1
 SG_ XCP_EMotor_01_DTO_02_Data  : 0|64@1+ (1.000000,0.000000) [0.000000|18446744073709551616.000000] "" Vector__XXX

BO_ 2617239043 XCP_EMotor_01_DTO_03: 64 LE1
 SG_ XCP_EMotor_01_DTO_03_Data  : 0|64@1+ (1.000000,0.000000) [0.000000|18446744073709551616.000000] "" Vector__XXX

BO_ 2617239044 XCP_EMotor_01_DTO_04: 64 LE1
 SG_ XCP_EMotor_01_DTO_04_Data  : 0|64@1+ (1.000000,0.000000) [0.000000|18446744073709551616.000000] "" Vector__XXX

BO_ 2617122304 XCP_EMotor_02_CRO_01: 64 Vector__XXX
 SG_ XCP_EMotor_02_CRO_01_Data  : 0|64@1+ (1.000000,0.000000) [0.000000|18446744073709551616.000000] "" LE2

BO_ 2617122305 XCP_EMotor_02_DTO_01: 64 LE2
 SG_ XCP_EMotor_02_DTO_01_Data  : 0|64@1+ (1.000000,0.000000) [0.000000|18446744073709551616.000000] "" Vector__XXX

BO_ 2617122306 XCP_EMotor_02_DTO_02: 64 LE2
 SG_ XCP_EMotor_02_DTO_02_Data  : 0|64@1+ (1.000000,0.000000) [0.000000|18446744073709551616.000000] "" Vector__XXX

BO_ 2617122307 XCP_EMotor_02_DTO_03: 64 LE2
 SG_ XCP_EMotor_02_DTO_03_Data  : 0|64@1+ (1.000000,0.000000) [0.000000|18446744073709551616.000000] "" Vector__XXX

BO_ 2617122308 XCP_EMotor_02_DTO_04: 64 LE2
 SG_ XCP_EMotor_02_DTO_04_Data  : 0|64@1+ (1.000000,0.000000) [0.000000|18446744073709551616.000000] "" Vector__XXX

BO_ 2617226768 XCP_Motor_CRO_01: 64 Vector__XXX
 SG_ XCP_Motor_CRO_01_Data  : 0|64@1+ (1.000000,0.000000) [0.000000|18446744073709551616.000000] "" Motor_BEV

BO_ 2617226769 XCP_Motor_DTO_01: 64 Motor_BEV
 SG_ XCP_Motor_DTO_01_Data  : 0|64@1+ (1.000000,0.000000) [0.000000|18446744073709551616.000000] "" Vector__XXX

BO_ 1411 ZV_02: 8 ICAS1_Gateway
 SG_ ZV_verriegeln_Anf  : 0|1@1+ (1.000000,0.000000) [0.000000|1.000000] "" Vector__XXX
 SG_ ZV_STSG_HFS_Anf  : 1|1@1+ (1.000000,0.000000) [0.000000|1.000000] "" Vector__XXX
 SG_ ZV_STSG_HBFS_Anf  : 2|1@1+ (1.000000,0.000000) [0.000000|1.000000] "" Vector__XXX
 SG_ ZV_Anf_Challenge_Auth  : 3|1@1+ (1.000000,0.000000) [0.000000|1.000000] "" Vector__XXX
 SG_ BCM_FH_Freigabe  : 12|1@1+ (1.000000,0.000000) [0.000000|1.000000] "" Vector__XXX
 SG_ BCM_Komfortfkt_Freigabe  : 13|1@1+ (1.000000,0.000000) [0.000000|1.000000] "" Vector__XXX
 SG_ BCM_HSK_Freigabe  : 14|1@1+ (1.000000,0.000000) [0.000000|1.000000] "" Vector__XXX
 SG_ BCM_Verdeck_Freigabe  : 15|1@1+ (1.000000,0.000000) [0.000000|1.000000] "" Vector__XXX
 SG_ ZV_verriegelt_intern_ist  : 16|1@1+ (1.000000,0.000000) [0.000000|1.000000] "" Vector__XXX
 SG_ ZV_verriegelt_extern_ist  : 17|1@1+ (1.000000,0.000000) [0.000000|1.000000] "" Airbag
 SG_ ZV_verriegelt_intern_soll  : 18|1@1+ (1.000000,0.000000) [0.000000|1.000000] "" Vector__XXX
 SG_ ZV_verriegelt_extern_soll  : 19|1@1+ (1.000000,0.000000) [0.000000|1.000000] "" Airbag
 SG_ ZV_gesafet_extern_ist  : 20|1@1+ (1.000000,0.000000) [0.000000|1.000000] "" Vector__XXX
 SG_ ZV_gesafet_extern_soll  : 21|1@1+ (1.000000,0.000000) [0.000000|1.000000] "" Vector__XXX
 SG_ ZV_Einzeltuerentriegelung  : 22|1@1+ (1.000000,0.000000) [0.000000|1.000000] "" Vector__XXX
 SG_ ZV_Heckeinzelentriegelung  : 23|1@1+ (1.000000,0.000000) [0.000000|1.000000] "" Vector__XXX
 SG_ ZV_FT_offen  : 24|1@1+ (1.000000,0.000000) [0.000000|1.000000] "" Motor_BEV
 SG_ ZV_BT_offen  : 25|1@1+ (1.000000,0.000000) [0.000000|1.000000] "" Motor_BEV
 SG_ ZV_HFS_offen  : 26|1@1+ (1.000000,0.000000) [0.000000|1.000000] "" Motor_BEV
 SG_ ZV_HBFS_offen  : 27|1@1+ (1.000000,0.000000) [0.000000|1.000000] "" Motor_BEV
 SG_ ZV_HD_offen  : 28|1@1+ (1.000000,0.000000) [0.000000|1.000000] "" Motor_BEV
 SG_ ZV_HS_offen  : 29|1@1+ (1.000000,0.000000) [0.000000|1.000000] "" Vector__XXX
 SG_ IRUE_aktiv  : 30|1@1+ (1.000000,0.000000) [0.000000|1.000000] "" Vector__XXX
 SG_ DWA_aktiv  : 31|1@1+ (1.000000,0.000000) [0.000000|1.000000] "" Vector__XXX
 SG_ FFB_HDF_Taste  : 34|1@1+ (1.000000,0.000000) [0.000000|1.000000] "" Vector__XXX
 SG_ FFB_Panik_Taste  : 35|1@1+ (1.000000,0.000000) [0.000000|1.000000] "" Vector__XXX
 SG_ FFB_Auf_Taste  : 36|1@1+ (1.000000,0.000000) [0.000000|1.000000] "" Vector__XXX
 SG_ FFB_Zu_Taste  : 37|1@1+ (1.000000,0.000000) [0.000000|1.000000] "" Vector__XXX
 SG_ FFB_CarFinder  : 38|1@1+ (1.000000,0.000000) [0.000000|1.000000] "" Vector__XXX
 SG_ FFB_Komfortoeffnen  : 39|1@1+ (1.000000,0.000000) [0.000000|1.000000] "" Vector__XXX
 SG_ FFB_Komfortschliessen  : 40|1@1+ (1.000000,0.000000) [0.000000|1.000000] "" Vector__XXX
 SG_ FBS_IDG_in_Reichweite  : 41|1@1+ (1.000000,0.000000) [0.000000|1.000000] "" Vector__XXX
 SG_ ZV_Schluessel_Zugang  : 42|4@1+ (1.000000,0.000000) [0.000000|15.000000] "" Vector__XXX
 SG_ ZV_SafeFunktion_aktiv  : 46|1@1+ (1.000000,0.000000) [0.000000|1.000000] "" Vector__XXX
 SG_ FBS_Warn_Schluessel_Batt  : 47|1@1+ (1.000000,0.000000) [0.000000|1.000000] "" Vector__XXX
 SG_ ZV_Oeffnungsmodus  : 48|2@1+ (1.000000,0.000000) [0.000000|3.000000] "" Vector__XXX
 SG_ ZV_ist_Zustand_verfuegbar  : 54|1@1+ (1.000000,0.000000) [0.000000|1.000000] "" Vector__XXX
 SG_ IRUE_Taster_Fkts_LED  : 55|1@1+ (1.000000,0.000000) [0.000000|1.000000] "" Vector__XXX
 SG_ ZV_Tankklappe_offen  : 56|1@1+ (1.000000,0.000000) [0.000000|1.000000] "" Vector__XXX
 SG_ ZV_Rollo_auf  : 57|1@1+ (1.000000,0.000000) [0.000000|1.000000] "" Vector__XXX
 SG_ ZV_Rollo_zu  : 58|1@1+ (1.000000,0.000000) [0.000000|1.000000] "" Vector__XXX
 SG_ ZV_SAD_auf  : 59|1@1+ (1.000000,0.000000) [0.000000|1.000000] "" Vector__XXX
 SG_ ZV_SAD_zu  : 60|1@1+ (1.000000,0.000000) [0.000000|1.000000] "" Vector__XXX
 SG_ ZV_verriegelt_soll  : 62|2@1+ (1.000000,0.000000) [0.000000|3.000000] "" Vector__XXX

BA_DEF_ BO_ "DiagRequest" ENUM "No", "Yes";
BA_DEF_ BO_ "DiagResponse" ENUM "No", "Yes";
BA_DEF_ BO_ "DiagState" ENUM "No", "Yes";
BA_DEF_ BO_ "GenMsgChkConstant" HEX 0 4095;
BA_DEF_ BO_ "GenMsgCycleTime" INT 0 65535;
BA_DEF_ BO_ "GenMsgCycleTimeFast" INT 0 65535;
BA_DEF_ BO_ "GenMsgDelayTime" INT 0 100000;
BA_DEF_ BO_ "GenMsgILSupport" ENUM "No", "Yes";
BA_DEF_ BO_ "GenMsgNrOfRepetition" INT 0 100;
BA_DEF_ BO_ "GenMsgPDUConstants" STRING;
BA_DEF_ BO_ "GenMsgSendType" ENUM "Cyclic", "not_used", "not_used", "not_used", "not_used", "not_used", "not_used", "IfActive", "NoMsgSendType";
BA_DEF_ BO_ "GenMsgStartDelayTime" INT 0 100000;
BA_DEF_ BO_ "NmMessage" ENUM "No", "Yes";
BA_DEF_ BO_ "NmhMessage" ENUM "No", "Yes";
BA_DEF_ BO_ "MsgType" ENUM "Application", "NM", "NMH", "TP2.0", "ISO-TP", "BAP", "EID", "KS";
BA_DEF_ BO_ "VAGTP20_API" HEX 0 255;
BA_DEF_ BO_ "VAGTP20_DynConnection" ENUM "No", "Yes";
BA_DEF_ BO_ "VAGTP20_DynSetup" ENUM "No", "Yes";
BA_DEF_ BO_ "VAGTP20_StatConnection" ENUM "No", "Yes";
BA_DEF_ BO_ "CANFD_BRS" ENUM "0", "1";
BA_DEF_ BO_ "VFrameFormat" ENUM "StandardCAN", "ExtendedCAN", "reserved", "reserved", "reserved", "reserved", "reserved", "reserved", "reserved", "reserved", "reserved", "reserved", "reserved", "reserved", "StandardCAN_FD", "ExtendedCAN_FD";
BA_DEF_ SG_ "GenSigSendType" ENUM "Cyclic", "OnWrite", "OnWriteWithRepetition", "OnChange", "OnChangeWithRepetition", "IfActive", "IfActiveWithRepetition", "NoSigSendType", "OnChangeAndIfActive", "OnChangeAndIfActiveWithRepetition";
BA_DEF_ SG_ "GenSigFuncType" ENUM "NoFunction", "MsgCounter", "CRC-8", "XOR", "XOR-2", "DatedBit", "SW-Kl15", "CHK", "Constant", "Protocol", "CRC-8-SAE_J1850";
BA_DEF_ SG_ "GenSigSwitchedByIgnition" ENUM "No", "Yes";
BA_DEF_DEF_  "DiagRequest" "No";
BA_DEF_DEF_  "DiagResponse" "No";
BA_DEF_DEF_  "DiagState" "No";
BA_DEF_DEF_  "GenMsgChkConstant" 0;
BA_DEF_DEF_  "GenMsgCycleTime" 0;
BA_DEF_DEF_  "GenMsgCycleTimeFast" 0;
BA_DEF_DEF_  "GenMsgDelayTime" 0;
BA_DEF_DEF_  "GenMsgILSupport" "No";
BA_DEF_DEF_  "GenMsgNrOfRepetition" 0;
BA_DEF_DEF_  "GenMsgPDUConstants" "";
BA_DEF_DEF_  "GenMsgSendType" "NoMsgSendType";
BA_DEF_DEF_  "GenMsgStartDelayTime" 0;
BA_DEF_DEF_  "NmMessage" "No";
BA_DEF_DEF_  "NmhMessage" "No";
BA_DEF_DEF_  "MsgType" "Application";
BA_DEF_DEF_  "VAGTP20_API" 0;
BA_DEF_DEF_  "VAGTP20_DynConnection" "No";
BA_DEF_DEF_  "VAGTP20_DynSetup" "No";
BA_DEF_DEF_  "VAGTP20_StatConnection" "No";
BA_DEF_DEF_  "CANFD_BRS" "1";
BA_DEF_DEF_  "VFrameFormat" "StandardCAN";
BA_DEF_DEF_  "GenSigSendType" "NoSigSendType";
BA_DEF_DEF_  "GenSigFuncType" "NoFunction";
BA_DEF_DEF_  "GenSigSwitchedByIgnition" "Yes";
BA_ "GenMsgCycleTime" BO_ 949 100;
BA_ "GenMsgILSupport" BO_ 949 "Yes";
BA_ "GenMsgSendType" BO_ 949 "Cyclic";
BA_ "VFrameFormat" BO_ 949 "StandardCAN_FD";
BA_ "GenMsgCycleTime" BO_ 1511 200;
BA_ "GenMsgILSupport" BO_ 1511 "Yes";
BA_ "GenMsgSendType" BO_ 1511 "Cyclic";
BA_ "VFrameFormat" BO_ 1511 "StandardCAN_FD";
BA_ "GenMsgCycleTime" BO_ 1505 200;
BA_ "GenMsgILSupport" BO_ 1505 "Yes";
BA_ "GenMsgSendType" BO_ 1505 "Cyclic";
BA_ "VFrameFormat" BO_ 1505 "StandardCAN_FD";
BA_ "GenMsgCycleTime" BO_ 2549088277 500;
BA_ "GenMsgILSupport" BO_ 2549088277 "Yes";
BA_ "GenMsgSendType" BO_ 2549088277 "Cyclic";
BA_ "CANFD_BRS" BO_ 2549088277 "0";
BA_ "VFrameFormat" BO_ 2549088277 "ExtendedCAN";
BA_ "GenMsgCycleTime" BO_ 2549088380 500;
BA_ "GenMsgILSupport" BO_ 2549088380 "Yes";
BA_ "GenMsgSendType" BO_ 2549088380 "Cyclic";
BA_ "VFrameFormat" BO_ 2549088380 "ExtendedCAN_FD";
BA_ "GenMsgCycleTime" BO_ 2549088272 500;
BA_ "GenMsgILSupport" BO_ 2549088272 "Yes";
BA_ "GenMsgSendType" BO_ 2549088272 "Cyclic";
BA_ "VFrameFormat" BO_ 2549088272 "ExtendedCAN_FD";
BA_ "GenMsgCycleTime" BO_ 2549088440 500;
BA_ "GenMsgILSupport" BO_ 2549088440 "Yes";
BA_ "GenMsgSendType" BO_ 2549088440 "Cyclic";
BA_ "VFrameFormat" BO_ 2549088440 "ExtendedCAN_FD";
BA_ "GenMsgCycleTime" BO_ 2549088374 500;
BA_ "GenMsgILSupport" BO_ 2549088374 "Yes";
BA_ "GenMsgSendType" BO_ 2549088374 "Cyclic";
BA_ "VFrameFormat" BO_ 2549088374 "ExtendedCAN_FD";
BA_ "MsgType" BO_ 2621440277 "ISO-TP";
BA_ "VFrameFormat" BO_ 2621440277 "ExtendedCAN_FD";
BA_ "MsgType" BO_ 2621571349 "ISO-TP";
BA_ "VFrameFormat" BO_ 2621571349 "ExtendedCAN_FD";
BA_ "GenMsgCycleTime" BO_ 982 100;
BA_ "GenMsgDelayTime" BO_ 982 20;
BA_ "GenMsgILSupport" BO_ 982 "Yes";
BA_ "GenMsgSendType" BO_ 982 "Cyclic";
BA_ "VFrameFormat" BO_ 982 "StandardCAN_FD";
BA_ "GenMsgChkConstant" BO_ 134 134;
BA_ "GenMsgCycleTime" BO_ 134 5;
BA_ "GenMsgILSupport" BO_ 134 "Yes";
BA_ "GenMsgPDUConstants" BO_ 134 "0x86,0x86,0x86,0x86,0x86,0x86,0x86,0x86,0x86,0x86,0x86,0x86,0x86,0x86,0x86,0x86";
BA_ "GenMsgSendType" BO_ 134 "Cyclic";
BA_ "VFrameFormat" BO_ 134 "StandardCAN_FD";
BA_ "GenMsgCycleTime" BO_ 817 500;
BA_ "GenMsgCycleTimeFast" BO_ 817 30;
BA_ "GenMsgILSupport" BO_ 817 "Yes";
BA_ "GenMsgSendType" BO_ 817 "Cyclic";
BA_ "VFrameFormat" BO_ 817 "StandardCAN_FD";
BA_ "GenMsgCycleTimeFast" BO_ 15 10;
BA_ "GenMsgILSupport" BO_ 15 "Yes";
BA_ "GenMsgSendType" BO_ 15 "IfActive";
BA_ "VFrameFormat" BO_ 15 "StandardCAN_FD";
BA_ "GenMsgCycleTime" BO_ 1600 500;
BA_ "GenMsgILSupport" BO_ 1600 "Yes";
BA_ "GenMsgSendType" BO_ 1600 "Cyclic";
BA_ "VFrameFormat" BO_ 1600 "StandardCAN_FD";
BA_ "GenMsgCycleTime" BO_ 167 10;
BA_ "GenMsgILSupport" BO_ 167 "Yes";
BA_ "GenMsgPDUConstants" BO_ 167 "0xd2,0x3d,0xcd,0x28,0x4c,0x14,0x22,0x4b,0x24,0xac,0xfa,0x55,0x66,0x80,0x0d,0x6c";
BA_ "GenMsgSendType" BO_ 167 "Cyclic";
BA_ "VFrameFormat" BO_ 167 "StandardCAN_FD";
BA_ "GenMsgCycleTime" BO_ 168 10;
BA_ "GenMsgILSupport" BO_ 168 "Yes";
BA_ "GenMsgPDUConstants" BO_ 168 "0x52,0x8c,0x50,0xee,0x4f,0xa6,0xcc,0xcf,0x7d,0x2f,0x98,0x6b,0x27,0x41,0x9f,0x93";
BA_ "GenMsgSendType" BO_ 168 "Cyclic";
BA_ "VFrameFormat" BO_ 168 "StandardCAN_FD";
BA_ "GenMsgCycleTime" BO_ 958 100;
BA_ "GenMsgDelayTime" BO_ 958 10;
BA_ "GenMsgILSupport" BO_ 958 "Yes";
BA_ "GenMsgPDUConstants" BO_ 958 "0x1f,0x28,0xc6,0x85,0xe6,0xf8,0xb0,0x19,0x5b,0x64,0x35,0x21,0xe4,0xf7,0x9c,0x24";
BA_ "GenMsgSendType" BO_ 958 "Cyclic";
BA_ "VFrameFormat" BO_ 958 "StandardCAN_FD";
BA_ "GenMsgCycleTime" BO_ 1631 500;
BA_ "GenMsgILSupport" BO_ 1631 "Yes";
BA_ "GenMsgSendType" BO_ 1631 "Cyclic";
BA_ "VFrameFormat" BO_ 1631 "StandardCAN_FD";
BA_ "GenMsgCycleTime" BO_ 1648 500;
BA_ "GenMsgDelayTime" BO_ 1648 20;
BA_ "GenMsgILSupport" BO_ 1648 "Yes";
BA_ "GenMsgSendType" BO_ 1648 "Cyclic";
BA_ "VFrameFormat" BO_ 1648 "StandardCAN_FD";
BA_ "GenMsgCycleTime" BO_ 967 100;
BA_ "GenMsgILSupport" BO_ 967 "Yes";
BA_ "GenMsgSendType" BO_ 967 "Cyclic";
BA_ "VFrameFormat" BO_ 967 "StandardCAN_FD";
BA_ "GenMsgCycleTime" BO_ 706 500;
BA_ "GenMsgDelayTime" BO_ 706 100;
BA_ "GenMsgILSupport" BO_ 706 "Yes";
BA_ "GenMsgSendType" BO_ 706 "Cyclic";
BA_ "VFrameFormat" BO_ 706 "StandardCAN_FD";
BA_ "GenMsgCycleTime" BO_ 267 20;
BA_ "GenMsgILSupport" BO_ 267 "Yes";
BA_ "GenMsgPDUConstants" BO_ 267 "0x77,0x5c,0xa0,0x89,0x4b,0x7c,0xbb,0xd6,0x1f,0x6c,0x4f,0xf6,0x20,0x2b,0x43,0xdd";
BA_ "GenMsgSendType" BO_ 267 "Cyclic";
BA_ "VFrameFormat" BO_ 267 "StandardCAN_FD";
BA_ "GenMsgCycleTime" BO_ 330 20;
BA_ "GenMsgILSupport" BO_ 330 "Yes";
BA_ "GenMsgSendType" BO_ 330 "Cyclic";
BA_ "VFrameFormat" BO_ 330 "StandardCAN_FD";
BA_ "GenMsgCycleTime" BO_ 512 50;
BA_ "GenMsgILSupport" BO_ 512 "Yes";
BA_ "GenMsgSendType" BO_ 512 "Cyclic";
BA_ "VFrameFormat" BO_ 512 "StandardCAN_FD";
BA_ "GenMsgCycleTime" BO_ 332 100;
BA_ "GenMsgDelayTime" BO_ 332 10;
BA_ "GenMsgILSupport" BO_ 332 "Yes";
BA_ "GenMsgSendType" BO_ 332 "Cyclic";
BA_ "VFrameFormat" BO_ 332 "StandardCAN_FD";
BA_ "GenMsgCycleTime" BO_ 246 10;
BA_ "GenMsgILSupport" BO_ 246 "Yes";
BA_ "GenMsgPDUConstants" BO_ 246 "0x89,0xd6,0xf6,0xdd,0xe7,0x74,0x0f,0xd2,0x26,0x5a,0x44,0x70,0xd5,0x67,0x79,0x3d";
BA_ "GenMsgSendType" BO_ 246 "Cyclic";
BA_ "VFrameFormat" BO_ 246 "StandardCAN_FD";
BA_ "GenMsgCycleTime" BO_ 190 10;
BA_ "GenMsgILSupport" BO_ 190 "Yes";
BA_ "GenMsgPDUConstants" BO_ 190 "0x18,0x71,0x10,0x8d,0xd7,0xaa,0xb0,0x78,0xac,0x12,0xae,0x0c,0xdd,0xf1,0x85,0x68";
BA_ "GenMsgSendType" BO_ 190 "Cyclic";
BA_ "VFrameFormat" BO_ 190 "StandardCAN_FD";
BA_ "GenMsgCycleTime" BO_ 2463978666 100;
BA_ "GenMsgILSupport" BO_ 2463978666 "Yes";
BA_ "GenMsgSendType" BO_ 2463978666 "Cyclic";
BA_ "VFrameFormat" BO_ 2463978666 "ExtendedCAN_FD";
BA_ "GenMsgChkConstant" BO_ 1601 71;
BA_ "GenMsgCycleTime" BO_ 1601 1000;
BA_ "GenMsgILSupport" BO_ 1601 "Yes";
BA_ "GenMsgPDUConstants" BO_ 1601 "0x47,0x47,0x47,0x47,0x47,0x47,0x47,0x47,0x47,0x47,0x47,0x47,0x47,0x47,0x47,0x47";
BA_ "GenMsgSendType" BO_ 1601 "Cyclic";
BA_ "VFrameFormat" BO_ 1601 "StandardCAN_FD";
BA_ "GenMsgCycleTime" BO_ 1155 500;
BA_ "GenMsgDelayTime" BO_ 1155 50;
BA_ "GenMsgILSupport" BO_ 1155 "Yes";
BA_ "GenMsgSendType" BO_ 1155 "Cyclic";
BA_ "VFrameFormat" BO_ 1155 "StandardCAN_FD";
BA_ "GenMsgCycleTime" BO_ 2527679686 2000;
BA_ "GenMsgDelayTime" BO_ 2527679686 100;
BA_ "GenMsgILSupport" BO_ 2527679686 "Yes";
BA_ "GenMsgSendType" BO_ 2527679686 "Cyclic";
BA_ "VFrameFormat" BO_ 2527679686 "ExtendedCAN_FD";
BA_ "GenMsgILSupport" BO_ 22 "Yes";
BA_ "VFrameFormat" BO_ 22 "StandardCAN_FD";
BA_ "GenMsgILSupport" BO_ 24 "Yes";
BA_ "VFrameFormat" BO_ 24 "StandardCAN_FD";
BA_ "GenMsgCycleTime" BO_ 339 200;
BA_ "GenMsgDelayTime" BO_ 339 10;
BA_ "GenMsgILSupport" BO_ 339 "Yes";
BA_ "GenMsgPDUConstants" BO_ 339 "0x03,0x13,0x23,0x7a,0x40,0x51,0x68,0xba,0xa8,0xbe,0x55,0x02,0x11,0x31,0x76,0xec";
BA_ "GenMsgSendType" BO_ 339 "Cyclic";
BA_ "VFrameFormat" BO_ 339 "StandardCAN_FD";
BA_ "GenMsgCycleTime" BO_ 2600468501 200;
BA_ "GenMsgCycleTimeFast" BO_ 2600468501 10;
BA_ "NmhMessage" BO_ 2600468501 "Yes";
BA_ "MsgType" BO_ 2600468501 "NMH";
BA_ "CANFD_BRS" BO_ 2600468501 "0";
BA_ "VFrameFormat" BO_ 2600468501 "ExtendedCAN";
BA_ "GenMsgCycleTime" BO_ 2600468604 200;
BA_ "GenMsgCycleTimeFast" BO_ 2600468604 10;
BA_ "NmhMessage" BO_ 2600468604 "Yes";
BA_ "MsgType" BO_ 2600468604 "NMH";
BA_ "CANFD_BRS" BO_ 2600468604 "0";
BA_ "VFrameFormat" BO_ 2600468604 "ExtendedCAN";
BA_ "GenMsgCycleTime" BO_ 2600468496 200;
BA_ "GenMsgCycleTimeFast" BO_ 2600468496 10;
BA_ "NmhMessage" BO_ 2600468496 "Yes";
BA_ "MsgType" BO_ 2600468496 "NMH";
BA_ "CANFD_BRS" BO_ 2600468496 "0";
BA_ "VFrameFormat" BO_ 2600468496 "ExtendedCAN";
BA_ "GenMsgCycleTime" BO_ 2600468664 200;
BA_ "GenMsgCycleTimeFast" BO_ 2600468664 10;
BA_ "NmhMessage" BO_ 2600468664 "Yes";
BA_ "MsgType" BO_ 2600468664 "NMH";
BA_ "CANFD_BRS" BO_ 2600468664 "0";
BA_ "VFrameFormat" BO_ 2600468664 "ExtendedCAN";
BA_ "GenMsgCycleTime" BO_ 2600468598 200;
BA_ "GenMsgCycleTimeFast" BO_ 2600468598 10;
BA_ "NmhMessage" BO_ 2600468598 "Yes";
BA_ "MsgType" BO_ 2600468598 "NMH";
BA_ "CANFD_BRS" BO_ 2600468598 "0";
BA_ "VFrameFormat" BO_ 2600468598 "ExtendedCAN";
BA_ "GenMsgCycleTime" BO_ 2600468733 200;
BA_ "GenMsgCycleTimeFast" BO_ 2600468733 10;
BA_ "NmhMessage" BO_ 2600468733 "Yes";
BA_ "MsgType" BO_ 2600468733 "NMH";
BA_ "CANFD_BRS" BO_ 2600468733 "0";
BA_ "VFrameFormat" BO_ 2600468733 "ExtendedCAN";
BA_ "DiagRequest" BO_ 2621440533 "Yes";
BA_ "MsgType" BO_ 2621440533 "ISO-TP";
BA_ "VFrameFormat" BO_ 2621440533 "ExtendedCAN_FD";
BA_ "DiagResponse" BO_ 2621571605 "Yes";
BA_ "MsgType" BO_ 2621571605 "ISO-TP";
BA_ "VFrameFormat" BO_ 2621571605 "ExtendedCAN_FD";
BA_ "DiagRequest" BO_ 2621440636 "Yes";
BA_ "MsgType" BO_ 2621440636 "ISO-TP";
BA_ "VFrameFormat" BO_ 2621440636 "ExtendedCAN_FD";
BA_ "DiagResponse" BO_ 2621571708 "Yes";
BA_ "MsgType" BO_ 2621571708 "ISO-TP";
BA_ "VFrameFormat" BO_ 2621571708 "ExtendedCAN_FD";
BA_ "DiagRequest" BO_ 2621440696 "Yes";
BA_ "MsgType" BO_ 2621440696 "ISO-TP";
BA_ "VFrameFormat" BO_ 2621440696 "ExtendedCAN_FD";
BA_ "DiagResponse" BO_ 2621571768 "Yes";
BA_ "MsgType" BO_ 2621571768 "ISO-TP";
BA_ "VFrameFormat" BO_ 2621571768 "ExtendedCAN_FD";
BA_ "DiagState" BO_ 2621506048 "Yes";
BA_ "MsgType" BO_ 2621506048 "ISO-TP";
BA_ "VFrameFormat" BO_ 2621506048 "ExtendedCAN_FD";
BA_ "DiagRequest" BO_ 2621440630 "Yes";
BA_ "MsgType" BO_ 2621440630 "ISO-TP";
BA_ "VFrameFormat" BO_ 2621440630 "ExtendedCAN_FD";
BA_ "DiagResponse" BO_ 2621571702 "Yes";
BA_ "MsgType" BO_ 2621571702 "ISO-TP";
BA_ "VFrameFormat" BO_ 2621571702 "ExtendedCAN_FD";
BA_ "DiagState" BO_ 2564502513 "Yes";
BA_ "MsgType" BO_ 2564502513 "ISO-TP";
BA_ "VFrameFormat" BO_ 2564502513 "ExtendedCAN_FD";
BA_ "DiagRequest" BO_ 2564425457 "Yes";
BA_ "MsgType" BO_ 2564425457 "ISO-TP";
BA_ "VFrameFormat" BO_ 2564425457 "ExtendedCAN_FD";
BA_ "DiagResponse" BO_ 2564485382 "Yes";
BA_ "MsgType" BO_ 2564485382 "ISO-TP";
BA_ "VFrameFormat" BO_ 2564485382 "ExtendedCAN_FD";
BA_ "DiagRequest" BO_ 2564425713 "Yes";
BA_ "MsgType" BO_ 2564425713 "ISO-TP";
BA_ "VFrameFormat" BO_ 2564425713 "ExtendedCAN_FD";
BA_ "DiagResponse" BO_ 2564485383 "Yes";
BA_ "MsgType" BO_ 2564485383 "ISO-TP";
BA_ "VFrameFormat" BO_ 2564485383 "ExtendedCAN_FD";
BA_ "DiagRequest" BO_ 2564424177 "Yes";
BA_ "MsgType" BO_ 2564424177 "ISO-TP";
BA_ "VFrameFormat" BO_ 2564424177 "ExtendedCAN_FD";
BA_ "DiagResponse" BO_ 2564485377 "Yes";
BA_ "MsgType" BO_ 2564485377 "ISO-TP";
BA_ "VFrameFormat" BO_ 2564485377 "ExtendedCAN_FD";
BA_ "GenMsgCycleTime" BO_ 627 100;
BA_ "GenMsgDelayTime" BO_ 627 10;
BA_ "GenMsgILSupport" BO_ 627 "Yes";
BA_ "GenMsgPDUConstants" BO_ 627 "0xc6,0x40,0x32,0xbe,0xc7,0x76,0x16,0x17,0x05,0xd8,0xab,0x52,0x45,0x35,0xf1,0x1d";
BA_ "GenMsgSendType" BO_ 627 "Cyclic";
BA_ "VFrameFormat" BO_ 627 "StandardCAN_FD";
BA_ "GenMsgCycleTime" BO_ 2463978709 500;
BA_ "GenMsgDelayTime" BO_ 2463978709 50;
BA_ "GenMsgILSupport" BO_ 2463978709 "Yes";
BA_ "GenMsgSendType" BO_ 2463978709 "Cyclic";
BA_ "VFrameFormat" BO_ 2463978709 "ExtendedCAN_FD";
BA_ "GenMsgCycleTime" BO_ 2589283656 500;
BA_ "GenMsgDelayTime" BO_ 2589283656 100;
BA_ "GenMsgILSupport" BO_ 2589283656 "Yes";
BA_ "GenMsgSendType" BO_ 2589283656 "Cyclic";
BA_ "VFrameFormat" BO_ 2589283656 "ExtendedCAN_FD";
BA_ "GenMsgCycleTime" BO_ 2527679741 240;
BA_ "GenMsgILSupport" BO_ 2527679741 "Yes";
BA_ "GenMsgPDUConstants" BO_ 2527679741 "0x9d,0xe8,0x36,0xa1,0xca,0x3b,0x1d,0x33,0xe0,0xd5,0xbb,0x5f,0xae,0x3c,0x31,0x9f";
BA_ "GenMsgSendType" BO_ 2527679741 "Cyclic";
BA_ "VFrameFormat" BO_ 2527679741 "ExtendedCAN_FD";
BA_ "GenMsgCycleTime" BO_ 518 20;
BA_ "GenMsgILSupport" BO_ 518 "Yes";
BA_ "GenMsgSendType" BO_ 518 "Cyclic";
BA_ "VFrameFormat" BO_ 518 "StandardCAN_FD";
BA_ "GenMsgCycleTime" BO_ 2527679685 2000;
BA_ "GenMsgDelayTime" BO_ 2527679685 100;
BA_ "GenMsgILSupport" BO_ 2527679685 "Yes";
BA_ "GenMsgSendType" BO_ 2527679685 "Cyclic";
BA_ "VFrameFormat" BO_ 2527679685 "ExtendedCAN_FD";
BA_ "GenMsgCycleTime" BO_ 319 200;
BA_ "GenMsgDelayTime" BO_ 319 20;
BA_ "GenMsgILSupport" BO_ 319 "Yes";
BA_ "GenMsgSendType" BO_ 319 "Cyclic";
BA_ "CANFD_BRS" BO_ 319 "0";
BA_ "GenMsgCycleTime" BO_ 1122 150;
BA_ "GenMsgILSupport" BO_ 1122 "Yes";
BA_ "GenMsgSendType" BO_ 1122 "Cyclic";
BA_ "VFrameFormat" BO_ 1122 "StandardCAN_FD";
BA_ "GenMsgCycleTime" BO_ 1123 150;
BA_ "GenMsgILSupport" BO_ 1123 "Yes";
BA_ "GenMsgSendType" BO_ 1123 "Cyclic";
BA_ "VFrameFormat" BO_ 1123 "StandardCAN_FD";
BA_ "GenMsgCycleTime" BO_ 1124 150;
BA_ "GenMsgILSupport" BO_ 1124 "Yes";
BA_ "GenMsgSendType" BO_ 1124 "Cyclic";
BA_ "VFrameFormat" BO_ 1124 "StandardCAN_FD";
BA_ "GenMsgCycleTime" BO_ 591 40;
BA_ "GenMsgILSupport" BO_ 591 "Yes";
BA_ "GenMsgSendType" BO_ 591 "Cyclic";
BA_ "VFrameFormat" BO_ 591 "StandardCAN_FD";
BA_ "DiagRequest" BO_ 2033 "Yes";
BA_ "MsgType" BO_ 2033 "ISO-TP";
BA_ "CANFD_BRS" BO_ 2033 "0";
BA_ "DiagResponse" BO_ 2041 "Yes";
BA_ "MsgType" BO_ 2041 "ISO-TP";
BA_ "CANFD_BRS" BO_ 2041 "0";
BA_ "GenMsgCycleTime" BO_ 980 1000;
BA_ "GenMsgCycleTimeFast" BO_ 980 100;
BA_ "GenMsgDelayTime" BO_ 980 50;
BA_ "GenMsgILSupport" BO_ 980 "Yes";
BA_ "GenMsgNrOfRepetition" BO_ 980 5;
BA_ "GenMsgPDUConstants" BO_ 980 "0xc3,0x79,0xbf,0xdb,0xe9,0x11,0x46,0x86,0x69,0xb6,0x9b,0x29,0x15,0x9c,0x45,0x0d";
BA_ "GenMsgSendType" BO_ 980 "Cyclic";
BA_ "VFrameFormat" BO_ 980 "StandardCAN_FD";
BA_ "GenMsgDelayTime" BO_ 2464153718 50;
BA_ "GenMsgILSupport" BO_ 2464153718 "Yes";
BA_ "VFrameFormat" BO_ 2464153718 "ExtendedCAN_FD";
BA_ "GenMsgDelayTime" BO_ 2464284790 50;
BA_ "GenMsgILSupport" BO_ 2464284790 "Yes";
BA_ "VFrameFormat" BO_ 2464284790 "ExtendedCAN_FD";
BA_ "GenMsgCycleTime" BO_ 1413 1000;
BA_ "GenMsgDelayTime" BO_ 1413 10;
BA_ "GenMsgILSupport" BO_ 1413 "Yes";
BA_ "GenMsgSendType" BO_ 1413 "Cyclic";
BA_ "VFrameFormat" BO_ 1413 "StandardCAN_FD";
BA_ "GenMsgCycleTime" BO_ 2589283396 500;
BA_ "GenMsgILSupport" BO_ 2589283396 "Yes";
BA_ "GenMsgSendType" BO_ 2589283396 "Cyclic";
BA_ "VFrameFormat" BO_ 2589283396 "ExtendedCAN_FD";
BA_ "GenMsgCycleTime" BO_ 1019 80;
BA_ "GenMsgILSupport" BO_ 1019 "Yes";
BA_ "GenMsgSendType" BO_ 1019 "Cyclic";
BA_ "VFrameFormat" BO_ 1019 "StandardCAN_FD";
BA_ "GenMsgCycleTime" BO_ 1716 200;
BA_ "GenMsgILSupport" BO_ 1716 "Yes";
BA_ "GenMsgSendType" BO_ 1716 "Cyclic";
BA_ "VFrameFormat" BO_ 1716 "StandardCAN_FD";
BA_ "GenMsgCycleTime" BO_ 261 20;
BA_ "GenMsgILSupport" BO_ 261 "Yes";
BA_ "GenMsgPDUConstants" BO_ 261 "0xde,0x0e,0xa7,0x1d,0xc3,0x83,0xbd,0x82,0x8c,0xa2,0x0c,0x7b,0x4d,0x3c,0x58,0x79";
BA_ "GenMsgSendType" BO_ 261 "Cyclic";
BA_ "VFrameFormat" BO_ 261 "StandardCAN_FD";
BA_ "GenMsgCycleTime" BO_ 313 20;
BA_ "GenMsgILSupport" BO_ 313 "Yes";
BA_ "GenMsgPDUConstants" BO_ 313 "0xed,0x03,0x1c,0x13,0xc6,0x23,0x78,0x7a,0x8b,0x40,0x14,0x51,0xbf,0x68,0x32,0xba";
BA_ "GenMsgSendType" BO_ 313 "Cyclic";
BA_ "VFrameFormat" BO_ 313 "StandardCAN_FD";
BA_ "GenMsgCycleTime" BO_ 2463978663 200;
BA_ "GenMsgDelayTime" BO_ 2463978663 40;
BA_ "GenMsgILSupport" BO_ 2463978663 "Yes";
BA_ "GenMsgSendType" BO_ 2463978663 "Cyclic";
BA_ "VFrameFormat" BO_ 2463978663 "ExtendedCAN_FD";
BA_ "GenMsgChkConstant" BO_ 181 228;
BA_ "GenMsgCycleTime" BO_ 181 10;
BA_ "GenMsgILSupport" BO_ 181 "Yes";
BA_ "GenMsgPDUConstants" BO_ 181 "0xe4,0xe4,0xe4,0xe4,0xe4,0xe4,0xe4,0xe4,0xe4,0xe4,0xe4,0xe4,0xe4,0xe4,0xe4,0xe4";
BA_ "GenMsgSendType" BO_ 181 "Cyclic";
BA_ "VFrameFormat" BO_ 181 "StandardCAN_FD";
BA_ "GenMsgCycleTime" BO_ 2463978687 1000;
BA_ "GenMsgDelayTime" BO_ 2463978687 100;
BA_ "GenMsgILSupport" BO_ 2463978687 "Yes";
BA_ "GenMsgSendType" BO_ 2463978687 "Cyclic";
BA_ "VFrameFormat" BO_ 2463978687 "ExtendedCAN_FD";
BA_ "GenMsgCycleTime" BO_ 916 160;
BA_ "GenMsgDelayTime" BO_ 916 10;
BA_ "GenMsgILSupport" BO_ 916 "Yes";
BA_ "GenMsgPDUConstants" BO_ 916 "0x47,0x94,0x92,0x6a,0x67,0xb5,0x0d,0x38,0xe3,0x8a,0x5d,0xb4,0x54,0xab,0xae,0x27";
BA_ "GenMsgSendType" BO_ 916 "Cyclic";
BA_ "VFrameFormat" BO_ 916 "StandardCAN_FD";
BA_ "GenMsgCycleTime" BO_ 1361 200;
BA_ "GenMsgDelayTime" BO_ 1361 50;
BA_ "GenMsgILSupport" BO_ 1361 "Yes";
BA_ "GenMsgSendType" BO_ 1361 "Cyclic";
BA_ "VFrameFormat" BO_ 1361 "StandardCAN_FD";
BA_ "MsgType" BO_ 2617028096 "EID";
BA_ "VFrameFormat" BO_ 2617028096 "ExtendedCAN_FD";
BA_ "MsgType" BO_ 2617028097 "EID";
BA_ "VFrameFormat" BO_ 2617028097 "ExtendedCAN_FD";
BA_ "MsgType" BO_ 2617239040 "EID";
BA_ "VFrameFormat" BO_ 2617239040 "ExtendedCAN_FD";
BA_ "MsgType" BO_ 2617239041 "EID";
BA_ "VFrameFormat" BO_ 2617239041 "ExtendedCAN_FD";
BA_ "MsgType" BO_ 2617239042 "EID";
BA_ "VFrameFormat" BO_ 2617239042 "ExtendedCAN_FD";
BA_ "MsgType" BO_ 2617239043 "EID";
BA_ "VFrameFormat" BO_ 2617239043 "ExtendedCAN_FD";
BA_ "MsgType" BO_ 2617239044 "EID";
BA_ "VFrameFormat" BO_ 2617239044 "ExtendedCAN_FD";
BA_ "MsgType" BO_ 2617122304 "EID";
BA_ "VFrameFormat" BO_ 2617122304 "ExtendedCAN_FD";
BA_ "MsgType" BO_ 2617122305 "EID";
BA_ "VFrameFormat" BO_ 2617122305 "ExtendedCAN_FD";
BA_ "MsgType" BO_ 2617122306 "EID";
BA_ "VFrameFormat" BO_ 2617122306 "ExtendedCAN_FD";
BA_ "MsgType" BO_ 2617122307 "EID";
BA_ "VFrameFormat" BO_ 2617122307 "ExtendedCAN_FD";
BA_ "MsgType" BO_ 2617122308 "EID";
BA_ "VFrameFormat" BO_ 2617122308 "ExtendedCAN_FD";
BA_ "MsgType" BO_ 2617226768 "EID";
BA_ "VFrameFormat" BO_ 2617226768 "ExtendedCAN_FD";
BA_ "MsgType" BO_ 2617226769 "EID";
BA_ "VFrameFormat" BO_ 2617226769 "ExtendedCAN_FD";
BA_ "GenMsgCycleTime" BO_ 1411 200;
BA_ "GenMsgCycleTimeFast" BO_ 1411 50;
BA_ "GenMsgDelayTime" BO_ 1411 20;
BA_ "GenMsgILSupport" BO_ 1411 "Yes";
BA_ "GenMsgNrOfRepetition" BO_ 1411 3;
BA_ "GenMsgSendType" BO_ 1411 "Cyclic";
BA_ "VFrameFormat" BO_ 1411 "StandardCAN_FD";
BA_ "GenMsgCycleTime" BO_ 949 100;
BA_ "GenMsgILSupport" BO_ 949 "Yes";
BA_ "GenMsgSendType" BO_ 949 "Cyclic";
BA_ "VFrameFormat" BO_ 949 "StandardCAN_FD";
BA_ "GenMsgCycleTime" BO_ 1511 200;
BA_ "GenMsgILSupport" BO_ 1511 "Yes";
BA_ "GenMsgSendType" BO_ 1511 "Cyclic";
BA_ "VFrameFormat" BO_ 1511 "StandardCAN_FD";
BA_ "GenMsgCycleTime" BO_ 1505 200;
BA_ "GenMsgILSupport" BO_ 1505 "Yes";
BA_ "GenMsgSendType" BO_ 1505 "Cyclic";
BA_ "VFrameFormat" BO_ 1505 "StandardCAN_FD";
BA_ "GenMsgCycleTime" BO_ 2549088277 500;
BA_ "GenMsgILSupport" BO_ 2549088277 "Yes";
BA_ "GenMsgSendType" BO_ 2549088277 "Cyclic";
BA_ "CANFD_BRS" BO_ 2549088277 "0";
BA_ "VFrameFormat" BO_ 2549088277 "ExtendedCAN";
BA_ "GenMsgCycleTime" BO_ 2549088380 500;
BA_ "GenMsgILSupport" BO_ 2549088380 "Yes";
BA_ "GenMsgSendType" BO_ 2549088380 "Cyclic";
BA_ "VFrameFormat" BO_ 2549088380 "ExtendedCAN_FD";
BA_ "GenMsgCycleTime" BO_ 2549088272 500;
BA_ "GenMsgILSupport" BO_ 2549088272 "Yes";
BA_ "GenMsgSendType" BO_ 2549088272 "Cyclic";
BA_ "VFrameFormat" BO_ 2549088272 "ExtendedCAN_FD";
BA_ "GenMsgCycleTime" BO_ 2549088440 500;
BA_ "GenMsgILSupport" BO_ 2549088440 "Yes";
BA_ "GenMsgSendType" BO_ 2549088440 "Cyclic";
BA_ "VFrameFormat" BO_ 2549088440 "ExtendedCAN_FD";
BA_ "GenMsgCycleTime" BO_ 2549088374 500;
BA_ "GenMsgILSupport" BO_ 2549088374 "Yes";
BA_ "GenMsgSendType" BO_ 2549088374 "Cyclic";
BA_ "VFrameFormat" BO_ 2549088374 "ExtendedCAN_FD";
BA_ "MsgType" BO_ 2621440277 "ISO-TP";
BA_ "VFrameFormat" BO_ 2621440277 "ExtendedCAN_FD";
BA_ "MsgType" BO_ 2621571349 "ISO-TP";
BA_ "VFrameFormat" BO_ 2621571349 "ExtendedCAN_FD";
BA_ "GenMsgCycleTime" BO_ 982 100;
BA_ "GenMsgDelayTime" BO_ 982 20;
BA_ "GenMsgILSupport" BO_ 982 "Yes";
BA_ "GenMsgSendType" BO_ 982 "Cyclic";
BA_ "VFrameFormat" BO_ 982 "StandardCAN_FD";
BA_ "GenMsgChkConstant" BO_ 134 134;
BA_ "GenMsgCycleTime" BO_ 134 5;
BA_ "GenMsgILSupport" BO_ 134 "Yes";
BA_ "GenMsgPDUConstants" BO_ 134 "0x86,0x86,0x86,0x86,0x86,0x86,0x86,0x86,0x86,0x86,0x86,0x86,0x86,0x86,0x86,0x86";
BA_ "GenMsgSendType" BO_ 134 "Cyclic";
BA_ "VFrameFormat" BO_ 134 "StandardCAN_FD";
BA_ "GenMsgCycleTime" BO_ 817 500;
BA_ "GenMsgCycleTimeFast" BO_ 817 30;
BA_ "GenMsgILSupport" BO_ 817 "Yes";
BA_ "GenMsgSendType" BO_ 817 "Cyclic";
BA_ "VFrameFormat" BO_ 817 "StandardCAN_FD";
BA_ "GenMsgCycleTimeFast" BO_ 15 10;
BA_ "GenMsgILSupport" BO_ 15 "Yes";
BA_ "GenMsgSendType" BO_ 15 "IfActive";
BA_ "VFrameFormat" BO_ 15 "StandardCAN_FD";
BA_ "GenMsgCycleTime" BO_ 1600 500;
BA_ "GenMsgILSupport" BO_ 1600 "Yes";
BA_ "GenMsgSendType" BO_ 1600 "Cyclic";
BA_ "VFrameFormat" BO_ 1600 "StandardCAN_FD";
BA_ "GenMsgCycleTime" BO_ 167 10;
BA_ "GenMsgILSupport" BO_ 167 "Yes";
BA_ "GenMsgPDUConstants" BO_ 167 "0xd2,0x3d,0xcd,0x28,0x4c,0x14,0x22,0x4b,0x24,0xac,0xfa,0x55,0x66,0x80,0x0d,0x6c";
BA_ "GenMsgSendType" BO_ 167 "Cyclic";
BA_ "VFrameFormat" BO_ 167 "StandardCAN_FD";
BA_ "GenMsgCycleTime" BO_ 168 10;
BA_ "GenMsgILSupport" BO_ 168 "Yes";
BA_ "GenMsgPDUConstants" BO_ 168 "0x52,0x8c,0x50,0xee,0x4f,0xa6,0xcc,0xcf,0x7d,0x2f,0x98,0x6b,0x27,0x41,0x9f,0x93";
BA_ "GenMsgSendType" BO_ 168 "Cyclic";
BA_ "VFrameFormat" BO_ 168 "StandardCAN_FD";
BA_ "GenMsgCycleTime" BO_ 958 100;
BA_ "GenMsgDelayTime" BO_ 958 10;
BA_ "GenMsgILSupport" BO_ 958 "Yes";
BA_ "GenMsgPDUConstants" BO_ 958 "0x1f,0x28,0xc6,0x85,0xe6,0xf8,0xb0,0x19,0x5b,0x64,0x35,0x21,0xe4,0xf7,0x9c,0x24";
BA_ "GenMsgSendType" BO_ 958 "Cyclic";
BA_ "VFrameFormat" BO_ 958 "StandardCAN_FD";
BA_ "GenMsgCycleTime" BO_ 1631 500;
BA_ "GenMsgILSupport" BO_ 1631 "Yes";
BA_ "GenMsgSendType" BO_ 1631 "Cyclic";
BA_ "VFrameFormat" BO_ 1631 "StandardCAN_FD";
BA_ "GenMsgCycleTime" BO_ 1648 500;
BA_ "GenMsgDelayTime" BO_ 1648 20;
BA_ "GenMsgILSupport" BO_ 1648 "Yes";
BA_ "GenMsgSendType" BO_ 1648 "Cyclic";
BA_ "VFrameFormat" BO_ 1648 "StandardCAN_FD";
BA_ "GenMsgCycleTime" BO_ 967 100;
BA_ "GenMsgILSupport" BO_ 967 "Yes";
BA_ "GenMsgSendType" BO_ 967 "Cyclic";
BA_ "VFrameFormat" BO_ 967 "StandardCAN_FD";
BA_ "GenMsgCycleTime" BO_ 706 500;
BA_ "GenMsgDelayTime" BO_ 706 100;
BA_ "GenMsgILSupport" BO_ 706 "Yes";
BA_ "GenMsgSendType" BO_ 706 "Cyclic";
BA_ "VFrameFormat" BO_ 706 "StandardCAN_FD";
BA_ "GenMsgCycleTime" BO_ 267 20;
BA_ "GenMsgILSupport" BO_ 267 "Yes";
BA_ "GenMsgPDUConstants" BO_ 267 "0x77,0x5c,0xa0,0x89,0x4b,0x7c,0xbb,0xd6,0x1f,0x6c,0x4f,0xf6,0x20,0x2b,0x43,0xdd";
BA_ "GenMsgSendType" BO_ 267 "Cyclic";
BA_ "VFrameFormat" BO_ 267 "StandardCAN_FD";
BA_ "GenMsgCycleTime" BO_ 330 20;
BA_ "GenMsgILSupport" BO_ 330 "Yes";
BA_ "GenMsgSendType" BO_ 330 "Cyclic";
BA_ "VFrameFormat" BO_ 330 "StandardCAN_FD";
BA_ "GenMsgCycleTime" BO_ 512 50;
BA_ "GenMsgILSupport" BO_ 512 "Yes";
BA_ "GenMsgSendType" BO_ 512 "Cyclic";
BA_ "VFrameFormat" BO_ 512 "StandardCAN_FD";
BA_ "GenMsgCycleTime" BO_ 332 100;
BA_ "GenMsgDelayTime" BO_ 332 10;
BA_ "GenMsgILSupport" BO_ 332 "Yes";
BA_ "GenMsgSendType" BO_ 332 "Cyclic";
BA_ "VFrameFormat" BO_ 332 "StandardCAN_FD";
BA_ "GenMsgCycleTime" BO_ 246 10;
BA_ "GenMsgILSupport" BO_ 246 "Yes";
BA_ "GenMsgPDUConstants" BO_ 246 "0x89,0xd6,0xf6,0xdd,0xe7,0x74,0x0f,0xd2,0x26,0x5a,0x44,0x70,0xd5,0x67,0x79,0x3d";
BA_ "GenMsgSendType" BO_ 246 "Cyclic";
BA_ "VFrameFormat" BO_ 246 "StandardCAN_FD";
BA_ "GenMsgCycleTime" BO_ 190 10;
BA_ "GenMsgILSupport" BO_ 190 "Yes";
BA_ "GenMsgPDUConstants" BO_ 190 "0x18,0x71,0x10,0x8d,0xd7,0xaa,0xb0,0x78,0xac,0x12,0xae,0x0c,0xdd,0xf1,0x85,0x68";
BA_ "GenMsgSendType" BO_ 190 "Cyclic";
BA_ "VFrameFormat" BO_ 190 "StandardCAN_FD";
BA_ "GenMsgCycleTime" BO_ 2463978666 100;
BA_ "GenMsgILSupport" BO_ 2463978666 "Yes";
BA_ "GenMsgSendType" BO_ 2463978666 "Cyclic";
BA_ "VFrameFormat" BO_ 2463978666 "ExtendedCAN_FD";
BA_ "GenMsgChkConstant" BO_ 1601 71;
BA_ "GenMsgCycleTime" BO_ 1601 1000;
BA_ "GenMsgILSupport" BO_ 1601 "Yes";
BA_ "GenMsgPDUConstants" BO_ 1601 "0x47,0x47,0x47,0x47,0x47,0x47,0x47,0x47,0x47,0x47,0x47,0x47,0x47,0x47,0x47,0x47";
BA_ "GenMsgSendType" BO_ 1601 "Cyclic";
BA_ "VFrameFormat" BO_ 1601 "StandardCAN_FD";
BA_ "GenMsgCycleTime" BO_ 1155 500;
BA_ "GenMsgDelayTime" BO_ 1155 50;
BA_ "GenMsgILSupport" BO_ 1155 "Yes";
BA_ "GenMsgSendType" BO_ 1155 "Cyclic";
BA_ "VFrameFormat" BO_ 1155 "StandardCAN_FD";
BA_ "GenMsgCycleTime" BO_ 2527679686 2000;
BA_ "GenMsgDelayTime" BO_ 2527679686 100;
BA_ "GenMsgILSupport" BO_ 2527679686 "Yes";
BA_ "GenMsgSendType" BO_ 2527679686 "Cyclic";
BA_ "VFrameFormat" BO_ 2527679686 "ExtendedCAN_FD";
BA_ "GenMsgILSupport" BO_ 22 "Yes";
BA_ "VFrameFormat" BO_ 22 "StandardCAN_FD";
BA_ "GenMsgILSupport" BO_ 24 "Yes";
BA_ "VFrameFormat" BO_ 24 "StandardCAN_FD";
BA_ "GenMsgCycleTime" BO_ 339 200;
BA_ "GenMsgDelayTime" BO_ 339 10;
BA_ "GenMsgILSupport" BO_ 339 "Yes";
BA_ "GenMsgPDUConstants" BO_ 339 "0x03,0x13,0x23,0x7a,0x40,0x51,0x68,0xba,0xa8,0xbe,0x55,0x02,0x11,0x31,0x76,0xec";
BA_ "GenMsgSendType" BO_ 339 "Cyclic";
BA_ "VFrameFormat" BO_ 339 "StandardCAN_FD";
BA_ "GenMsgCycleTime" BO_ 2600468501 200;
BA_ "GenMsgCycleTimeFast" BO_ 2600468501 10;
BA_ "NmhMessage" BO_ 2600468501 "Yes";
BA_ "MsgType" BO_ 2600468501 "NMH";
BA_ "CANFD_BRS" BO_ 2600468501 "0";
BA_ "VFrameFormat" BO_ 2600468501 "ExtendedCAN";
BA_ "GenMsgCycleTime" BO_ 2600468604 200;
BA_ "GenMsgCycleTimeFast" BO_ 2600468604 10;
BA_ "NmhMessage" BO_ 2600468604 "Yes";
BA_ "MsgType" BO_ 2600468604 "NMH";
BA_ "CANFD_BRS" BO_ 2600468604 "0";
BA_ "VFrameFormat" BO_ 2600468604 "ExtendedCAN";
BA_ "GenMsgCycleTime" BO_ 2600468496 200;
BA_ "GenMsgCycleTimeFast" BO_ 2600468496 10;
BA_ "NmhMessage" BO_ 2600468496 "Yes";
BA_ "MsgType" BO_ 2600468496 "NMH";
BA_ "CANFD_BRS" BO_ 2600468496 "0";
BA_ "VFrameFormat" BO_ 2600468496 "ExtendedCAN";
BA_ "GenMsgCycleTime" BO_ 2600468664 200;
BA_ "GenMsgCycleTimeFast" BO_ 2600468664 10;
BA_ "NmhMessage" BO_ 2600468664 "Yes";
BA_ "MsgType" BO_ 2600468664 "NMH";
BA_ "CANFD_BRS" BO_ 2600468664 "0";
BA_ "VFrameFormat" BO_ 2600468664 "ExtendedCAN";
BA_ "GenMsgCycleTime" BO_ 2600468598 200;
BA_ "GenMsgCycleTimeFast" BO_ 2600468598 10;
BA_ "NmhMessage" BO_ 2600468598 "Yes";
BA_ "MsgType" BO_ 2600468598 "NMH";
BA_ "CANFD_BRS" BO_ 2600468598 "0";
BA_ "VFrameFormat" BO_ 2600468598 "ExtendedCAN";
BA_ "GenMsgCycleTime" BO_ 2600468733 200;
BA_ "GenMsgCycleTimeFast" BO_ 2600468733 10;
BA_ "NmhMessage" BO_ 2600468733 "Yes";
BA_ "MsgType" BO_ 2600468733 "NMH";
BA_ "CANFD_BRS" BO_ 2600468733 "0";
BA_ "VFrameFormat" BO_ 2600468733 "ExtendedCAN";
BA_ "DiagRequest" BO_ 2621440533 "Yes";
BA_ "MsgType" BO_ 2621440533 "ISO-TP";
BA_ "VFrameFormat" BO_ 2621440533 "ExtendedCAN_FD";
BA_ "DiagResponse" BO_ 2621571605 "Yes";
BA_ "MsgType" BO_ 2621571605 "ISO-TP";
BA_ "VFrameFormat" BO_ 2621571605 "ExtendedCAN_FD";
BA_ "DiagRequest" BO_ 2621440636 "Yes";
BA_ "MsgType" BO_ 2621440636 "ISO-TP";
BA_ "VFrameFormat" BO_ 2621440636 "ExtendedCAN_FD";
BA_ "DiagResponse" BO_ 2621571708 "Yes";
BA_ "MsgType" BO_ 2621571708 "ISO-TP";
BA_ "VFrameFormat" BO_ 2621571708 "ExtendedCAN_FD";
BA_ "DiagRequest" BO_ 2621440696 "Yes";
BA_ "MsgType" BO_ 2621440696 "ISO-TP";
BA_ "VFrameFormat" BO_ 2621440696 "ExtendedCAN_FD";
BA_ "DiagResponse" BO_ 2621571768 "Yes";
BA_ "MsgType" BO_ 2621571768 "ISO-TP";
BA_ "VFrameFormat" BO_ 2621571768 "ExtendedCAN_FD";
BA_ "DiagState" BO_ 2621506048 "Yes";
BA_ "MsgType" BO_ 2621506048 "ISO-TP";
BA_ "VFrameFormat" BO_ 2621506048 "ExtendedCAN_FD";
BA_ "DiagRequest" BO_ 2621440630 "Yes";
BA_ "MsgType" BO_ 2621440630 "ISO-TP";
BA_ "VFrameFormat" BO_ 2621440630 "ExtendedCAN_FD";
BA_ "DiagResponse" BO_ 2621571702 "Yes";
BA_ "MsgType" BO_ 2621571702 "ISO-TP";
BA_ "VFrameFormat" BO_ 2621571702 "ExtendedCAN_FD";
BA_ "DiagState" BO_ 2564502513 "Yes";
BA_ "MsgType" BO_ 2564502513 "ISO-TP";
BA_ "VFrameFormat" BO_ 2564502513 "ExtendedCAN_FD";
BA_ "DiagRequest" BO_ 2564425457 "Yes";
BA_ "MsgType" BO_ 2564425457 "ISO-TP";
BA_ "VFrameFormat" BO_ 2564425457 "ExtendedCAN_FD";
BA_ "DiagResponse" BO_ 2564485382 "Yes";
BA_ "MsgType" BO_ 2564485382 "ISO-TP";
BA_ "VFrameFormat" BO_ 2564485382 "ExtendedCAN_FD";
BA_ "DiagRequest" BO_ 2564425713 "Yes";
BA_ "MsgType" BO_ 2564425713 "ISO-TP";
BA_ "VFrameFormat" BO_ 2564425713 "ExtendedCAN_FD";
BA_ "DiagResponse" BO_ 2564485383 "Yes";
BA_ "MsgType" BO_ 2564485383 "ISO-TP";
BA_ "VFrameFormat" BO_ 2564485383 "ExtendedCAN_FD";
BA_ "DiagRequest" BO_ 2564424177 "Yes";
BA_ "MsgType" BO_ 2564424177 "ISO-TP";
BA_ "VFrameFormat" BO_ 2564424177 "ExtendedCAN_FD";
BA_ "DiagResponse" BO_ 2564485377 "Yes";
BA_ "MsgType" BO_ 2564485377 "ISO-TP";
BA_ "VFrameFormat" BO_ 2564485377 "ExtendedCAN_FD";
BA_ "GenMsgCycleTime" BO_ 627 100;
BA_ "GenMsgDelayTime" BO_ 627 10;
BA_ "GenMsgILSupport" BO_ 627 "Yes";
BA_ "GenMsgPDUConstants" BO_ 627 "0xc6,0x40,0x32,0xbe,0xc7,0x76,0x16,0x17,0x05,0xd8,0xab,0x52,0x45,0x35,0xf1,0x1d";
BA_ "GenMsgSendType" BO_ 627 "Cyclic";
BA_ "VFrameFormat" BO_ 627 "StandardCAN_FD";
BA_ "GenMsgCycleTime" BO_ 2463978709 500;
BA_ "GenMsgDelayTime" BO_ 2463978709 50;
BA_ "GenMsgILSupport" BO_ 2463978709 "Yes";
BA_ "GenMsgSendType" BO_ 2463978709 "Cyclic";
BA_ "VFrameFormat" BO_ 2463978709 "ExtendedCAN_FD";
BA_ "GenMsgCycleTime" BO_ 2589283656 500;
BA_ "GenMsgDelayTime" BO_ 2589283656 100;
BA_ "GenMsgILSupport" BO_ 2589283656 "Yes";
BA_ "GenMsgSendType" BO_ 2589283656 "Cyclic";
BA_ "VFrameFormat" BO_ 2589283656 "ExtendedCAN_FD";
BA_ "GenMsgCycleTime" BO_ 2527679741 240;
BA_ "GenMsgILSupport" BO_ 2527679741 "Yes";
BA_ "GenMsgPDUConstants" BO_ 2527679741 "0x9d,0xe8,0x36,0xa1,0xca,0x3b,0x1d,0x33,0xe0,0xd5,0xbb,0x5f,0xae,0x3c,0x31,0x9f";
BA_ "GenMsgSendType" BO_ 2527679741 "Cyclic";
BA_ "VFrameFormat" BO_ 2527679741 "ExtendedCAN_FD";
BA_ "GenMsgCycleTime" BO_ 518 20;
BA_ "GenMsgILSupport" BO_ 518 "Yes";
BA_ "GenMsgSendType" BO_ 518 "Cyclic";
BA_ "VFrameFormat" BO_ 518 "StandardCAN_FD";
BA_ "GenMsgCycleTime" BO_ 2527679685 2000;
BA_ "GenMsgDelayTime" BO_ 2527679685 100;
BA_ "GenMsgILSupport" BO_ 2527679685 "Yes";
BA_ "GenMsgSendType" BO_ 2527679685 "Cyclic";
BA_ "VFrameFormat" BO_ 2527679685 "ExtendedCAN_FD";
BA_ "GenMsgCycleTime" BO_ 319 200;
BA_ "GenMsgDelayTime" BO_ 319 20;
BA_ "GenMsgILSupport" BO_ 319 "Yes";
BA_ "GenMsgSendType" BO_ 319 "Cyclic";
BA_ "CANFD_BRS" BO_ 319 "0";
BA_ "GenMsgCycleTime" BO_ 1122 150;
BA_ "GenMsgILSupport" BO_ 1122 "Yes";
BA_ "GenMsgSendType" BO_ 1122 "Cyclic";
BA_ "VFrameFormat" BO_ 1122 "StandardCAN_FD";
BA_ "GenMsgCycleTime" BO_ 1123 150;
BA_ "GenMsgILSupport" BO_ 1123 "Yes";
BA_ "GenMsgSendType" BO_ 1123 "Cyclic";
BA_ "VFrameFormat" BO_ 1123 "StandardCAN_FD";
BA_ "GenMsgCycleTime" BO_ 1124 150;
BA_ "GenMsgILSupport" BO_ 1124 "Yes";
BA_ "GenMsgSendType" BO_ 1124 "Cyclic";
BA_ "VFrameFormat" BO_ 1124 "StandardCAN_FD";
BA_ "GenMsgCycleTime" BO_ 591 40;
BA_ "GenMsgILSupport" BO_ 591 "Yes";
BA_ "GenMsgSendType" BO_ 591 "Cyclic";
BA_ "VFrameFormat" BO_ 591 "StandardCAN_FD";
BA_ "DiagRequest" BO_ 2033 "Yes";
BA_ "MsgType" BO_ 2033 "ISO-TP";
BA_ "CANFD_BRS" BO_ 2033 "0";
BA_ "DiagResponse" BO_ 2041 "Yes";
BA_ "MsgType" BO_ 2041 "ISO-TP";
BA_ "CANFD_BRS" BO_ 2041 "0";
BA_ "GenMsgCycleTime" BO_ 980 1000;
BA_ "GenMsgCycleTimeFast" BO_ 980 100;
BA_ "GenMsgDelayTime" BO_ 980 50;
BA_ "GenMsgILSupport" BO_ 980 "Yes";
BA_ "GenMsgNrOfRepetition" BO_ 980 5;
BA_ "GenMsgPDUConstants" BO_ 980 "0xc3,0x79,0xbf,0xdb,0xe9,0x11,0x46,0x86,0x69,0xb6,0x9b,0x29,0x15,0x9c,0x45,0x0d";
BA_ "GenMsgSendType" BO_ 980 "Cyclic";
BA_ "VFrameFormat" BO_ 980 "StandardCAN_FD";
BA_ "GenMsgDelayTime" BO_ 2464153718 50;
BA_ "GenMsgILSupport" BO_ 2464153718 "Yes";
BA_ "VFrameFormat" BO_ 2464153718 "ExtendedCAN_FD";
BA_ "GenMsgDelayTime" BO_ 2464284790 50;
BA_ "GenMsgILSupport" BO_ 2464284790 "Yes";
BA_ "VFrameFormat" BO_ 2464284790 "ExtendedCAN_FD";
BA_ "GenMsgCycleTime" BO_ 1413 1000;
BA_ "GenMsgDelayTime" BO_ 1413 10;
BA_ "GenMsgILSupport" BO_ 1413 "Yes";
BA_ "GenMsgSendType" BO_ 1413 "Cyclic";
BA_ "VFrameFormat" BO_ 1413 "StandardCAN_FD";
BA_ "GenMsgCycleTime" BO_ 2589283396 500;
BA_ "GenMsgILSupport" BO_ 2589283396 "Yes";
BA_ "GenMsgSendType" BO_ 2589283396 "Cyclic";
BA_ "VFrameFormat" BO_ 2589283396 "ExtendedCAN_FD";
BA_ "GenMsgCycleTime" BO_ 1019 80;
BA_ "GenMsgILSupport" BO_ 1019 "Yes";
BA_ "GenMsgSendType" BO_ 1019 "Cyclic";
BA_ "VFrameFormat" BO_ 1019 "StandardCAN_FD";
BA_ "GenMsgCycleTime" BO_ 1716 200;
BA_ "GenMsgILSupport" BO_ 1716 "Yes";
BA_ "GenMsgSendType" BO_ 1716 "Cyclic";
BA_ "VFrameFormat" BO_ 1716 "StandardCAN_FD";
BA_ "GenMsgCycleTime" BO_ 261 20;
BA_ "GenMsgILSupport" BO_ 261 "Yes";
BA_ "GenMsgPDUConstants" BO_ 261 "0xde,0x0e,0xa7,0x1d,0xc3,0x83,0xbd,0x82,0x8c,0xa2,0x0c,0x7b,0x4d,0x3c,0x58,0x79";
BA_ "GenMsgSendType" BO_ 261 "Cyclic";
BA_ "VFrameFormat" BO_ 261 "StandardCAN_FD";
BA_ "GenMsgCycleTime" BO_ 313 20;
BA_ "GenMsgILSupport" BO_ 313 "Yes";
BA_ "GenMsgPDUConstants" BO_ 313 "0xed,0x03,0x1c,0x13,0xc6,0x23,0x78,0x7a,0x8b,0x40,0x14,0x51,0xbf,0x68,0x32,0xba";
BA_ "GenMsgSendType" BO_ 313 "Cyclic";
BA_ "VFrameFormat" BO_ 313 "StandardCAN_FD";
BA_ "GenMsgCycleTime" BO_ 2463978663 200;
BA_ "GenMsgDelayTime" BO_ 2463978663 40;
BA_ "GenMsgILSupport" BO_ 2463978663 "Yes";
BA_ "GenMsgSendType" BO_ 2463978663 "Cyclic";
BA_ "VFrameFormat" BO_ 2463978663 "ExtendedCAN_FD";
BA_ "GenMsgChkConstant" BO_ 181 228;
BA_ "GenMsgCycleTime" BO_ 181 10;
BA_ "GenMsgILSupport" BO_ 181 "Yes";
BA_ "GenMsgPDUConstants" BO_ 181 "0xe4,0xe4,0xe4,0xe4,0xe4,0xe4,0xe4,0xe4,0xe4,0xe4,0xe4,0xe4,0xe4,0xe4,0xe4,0xe4";
BA_ "GenMsgSendType" BO_ 181 "Cyclic";
BA_ "VFrameFormat" BO_ 181 "StandardCAN_FD";
BA_ "GenMsgCycleTime" BO_ 2463978687 1000;
BA_ "GenMsgDelayTime" BO_ 2463978687 100;
BA_ "GenMsgILSupport" BO_ 2463978687 "Yes";
BA_ "GenMsgSendType" BO_ 2463978687 "Cyclic";
BA_ "VFrameFormat" BO_ 2463978687 "ExtendedCAN_FD";
BA_ "GenMsgCycleTime" BO_ 916 160;
BA_ "GenMsgDelayTime" BO_ 916 10;
BA_ "GenMsgILSupport" BO_ 916 "Yes";
BA_ "GenMsgPDUConstants" BO_ 916 "0x47,0x94,0x92,0x6a,0x67,0xb5,0x0d,0x38,0xe3,0x8a,0x5d,0xb4,0x54,0xab,0xae,0x27";
BA_ "GenMsgSendType" BO_ 916 "Cyclic";
BA_ "VFrameFormat" BO_ 916 "StandardCAN_FD";
BA_ "GenMsgCycleTime" BO_ 1361 200;
BA_ "GenMsgDelayTime" BO_ 1361 50;
BA_ "GenMsgILSupport" BO_ 1361 "Yes";
BA_ "GenMsgSendType" BO_ 1361 "Cyclic";
BA_ "VFrameFormat" BO_ 1361 "StandardCAN_FD";
BA_ "MsgType" BO_ 2617028096 "EID";
BA_ "VFrameFormat" BO_ 2617028096 "ExtendedCAN_FD";
BA_ "MsgType" BO_ 2617028097 "EID";
BA_ "VFrameFormat" BO_ 2617028097 "ExtendedCAN_FD";
BA_ "MsgType" BO_ 2617239040 "EID";
BA_ "VFrameFormat" BO_ 2617239040 "ExtendedCAN_FD";
BA_ "MsgType" BO_ 2617239041 "EID";
BA_ "VFrameFormat" BO_ 2617239041 "ExtendedCAN_FD";
BA_ "MsgType" BO_ 2617239042 "EID";
BA_ "VFrameFormat" BO_ 2617239042 "ExtendedCAN_FD";
BA_ "MsgType" BO_ 2617239043 "EID";
BA_ "VFrameFormat" BO_ 2617239043 "ExtendedCAN_FD";
BA_ "MsgType" BO_ 2617239044 "EID";
BA_ "VFrameFormat" BO_ 2617239044 "ExtendedCAN_FD";
BA_ "MsgType" BO_ 2617122304 "EID";
BA_ "VFrameFormat" BO_ 2617122304 "ExtendedCAN_FD";
BA_ "MsgType" BO_ 2617122305 "EID";
BA_ "VFrameFormat" BO_ 2617122305 "ExtendedCAN_FD";
BA_ "MsgType" BO_ 2617122306 "EID";
BA_ "VFrameFormat" BO_ 2617122306 "ExtendedCAN_FD";
BA_ "MsgType" BO_ 2617122307 "EID";
BA_ "VFrameFormat" BO_ 2617122307 "ExtendedCAN_FD";
BA_ "MsgType" BO_ 2617122308 "EID";
BA_ "VFrameFormat" BO_ 2617122308 "ExtendedCAN_FD";
BA_ "MsgType" BO_ 2617226768 "EID";
BA_ "VFrameFormat" BO_ 2617226768 "ExtendedCAN_FD";
BA_ "MsgType" BO_ 2617226769 "EID";
BA_ "VFrameFormat" BO_ 2617226769 "ExtendedCAN_FD";
BA_ "GenMsgCycleTime" BO_ 1411 200;
BA_ "GenMsgCycleTimeFast" BO_ 1411 50;
BA_ "GenMsgDelayTime" BO_ 1411 20;
BA_ "GenMsgILSupport" BO_ 1411 "Yes";
BA_ "GenMsgNrOfRepetition" BO_ 1411 3;
BA_ "GenMsgSendType" BO_ 1411 "Cyclic";
BA_ "VFrameFormat" BO_ 1411 "StandardCAN_FD";
